VERSION ""

NS_ :

BS_:

BU_: Turbocharger OnBoardDataLogger OffBoardDiagnosticTool2 OffBoardDiagnosticTool1 FileServer ParkingBrakeController SeatControl2 FanDriveController SteeringColumnUnit CommunicationUnitRadio CommunicationUnitSatellite CommunicationUnitCellular PropulsionBatteryCharger ChassisController2 ChassisController1 EngineValveControl AuxiliaryHeater2 AuxiliaryHeater1 ClutchUnit RampControl InformationSystem1 SuspensionSystemController2 OilSensor VehicleDynamicStability ExhaustEmissionController TransmissionDisplay2 TransmissionDisplay1 ClimateControl2 WaterPumpController RearAxleSteeringController LightingOperatorControl SeatController1 IgnitionController2 IgnitionController1 TirePressureController CabController2 CabController1 PneumaticSystemController SuspensionSystemController1 HydraulicPumpController EnduranceBrakingSystem RetarderExhaustEngine2 OnBoardDiagnosticUnit HeadwayController RetarderExhaustEngine1 CabDisplay1 ManagementComputer VirtualTerminal OffVehicleGateway PowerTakeOffFront HitchControl AuxiliaryValveControl BodyController TractorTrailerBridge1 StarterSystem ElectricalSystem VehicleSecurity VehicleNavigation AerodynamicControl ElectricalChargingSystem ClimateControl1 TripRecorder InstrumentCluster SuspensionDriveAxle2 SuspensionDriveAxle1 SuspensionSteerAxle SteeringController FuelSystem CruiseControl RetarderDriveline RetarderEngine BrakesDriveAxle2 BrakesDriveAxle1 BrakesSystemController BrakesSteerAxle AxleDrive2 AxleDrive1 AxleSteering PowerTakeOff ShiftConsoleSecondary ShiftConsolePrimary Transmission2 Transmission1 Engine2 Engine1

BO_ 2365479678 ASC1: 8 Vector__XXX
 SG_ MemoryLevel : 60|4@1+ (1,0) [0|15] "" Vector__XXX
 SG_ SuspensionCtrlRefusalInformation : 56|4@1+ (1,0) [0|15] "" Vector__XXX
 SG_ SpeedDependantLevelCtrlStatus : 54|2@1+ (1,0) [0|3] "" Vector__XXX
 SG_ AllwLevelCtrlDuringBrakingStatus : 52|2@1+ (1,0) [0|3] "" Vector__XXX
 SG_ SuspensionRemoteCtrl2 : 50|2@1+ (1,0) [0|3] "" Vector__XXX
 SG_ SuspensionRemoteCtrl1 : 48|2@1+ (1,0) [0|3] "" Vector__XXX
 SG_ LiftAxle2Pos : 46|2@1+ (1,0) [0|3] "" Vector__XXX
 SG_ RearAxleInBumperRange : 42|2@1+ (1,0) [0|3] "" Vector__XXX
 SG_ FrontAxleInBumperRange : 40|2@1+ (1,0) [0|3] "" Vector__XXX
 SG_ LiftAxle1Pos : 38|2@1+ (1,0) [0|3] "" Vector__XXX
 SG_ DoorRelease : 36|2@1+ (1,0) [0|3] "" Vector__XXX
 SG_ VehicleMotionInhibit : 34|2@1+ (1,0) [0|3] "" Vector__XXX
 SG_ SecurityDevice : 32|2@1+ (1,0) [0|3] "" Vector__XXX
 SG_ LevelCtrlMode : 28|4@1+ (1,0) [0|15] "" Vector__XXX
 SG_ KneelingInformation : 24|4@1+ (1,0) [0|15] "" Vector__XXX
 SG_ LiftingCtrlModeRearAxle : 22|2@1+ (1,0) [0|3] "" Vector__XXX
 SG_ LiftingCtrlModeFrontAxle : 20|2@1+ (1,0) [0|3] "" Vector__XXX
 SG_ LoweringCtrlModeRearAxle : 18|2@1+ (1,0) [0|3] "" Vector__XXX
 SG_ LoweringCtrlModeFrontAxle : 16|2@1+ (1,0) [0|3] "" Vector__XXX
 SG_ AboveNominalLevelRearAxle : 14|2@1+ (1,0) [0|3] "" Vector__XXX
 SG_ AboveNominalLevelFrontAxle : 12|2@1+ (1,0) [0|3] "" Vector__XXX
 SG_ BelowNominalLevelRearAxle : 10|2@1+ (1,0) [0|3] "" Vector__XXX
 SG_ BelowNominalLevelFrontAxle : 8|2@1+ (1,0) [0|3] "" Vector__XXX
 SG_ NominalLevelRearAxle : 4|4@1+ (1,0) [0|15] "" Vector__XXX
 SG_ NominalLevelFrontAxle : 0|4@1+ (1,0) [0|15] "" Vector__XXX

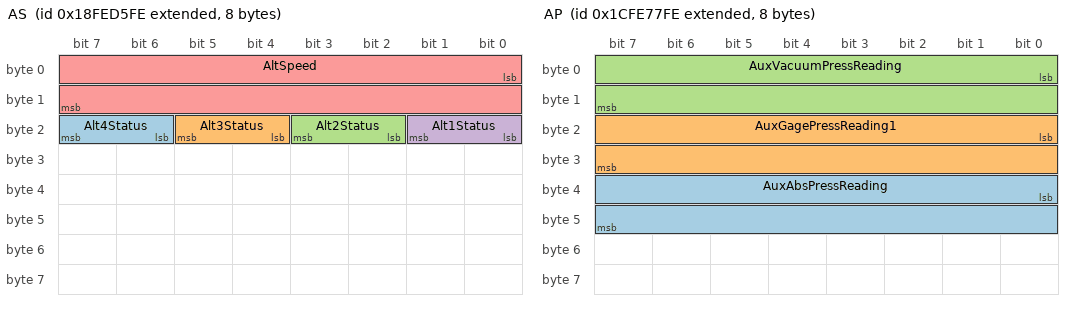
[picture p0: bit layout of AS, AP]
BO_ 2566837758 AS: 8 Vector__XXX
 SG_ Alt4Status : 22|2@1+ (1,0) [0|3] "" Vector__XXX
 SG_ Alt3Status : 20|2@1+ (1,0) [0|3] "" Vector__XXX
 SG_ Alt2Status : 18|2@1+ (1,0) [0|3] "" Vector__XXX
 SG_ Alt1Status : 16|2@1+ (1,0) [0|3] "" Vector__XXX
 SG_ AltSpeed : 0|16@1+ (0.5,0) [0|32127.5] "rpm" Vector__XXX

BO_ 2633922558 AP: 8 Vector__XXX
 SG_ AuxAbsPressReading : 32|16@1+ (0.5,0) [0|32127.5] "kPa" Vector__XXX
 SG_ AuxGagePressReading1 : 16|16@1+ (0.5,0) [0|32127.5] "kPa" Vector__XXX
 SG_ AuxVacuumPressReading : 0|16@1+ (0.5,0) [0|32127.5] "kPa" Vector__XXX

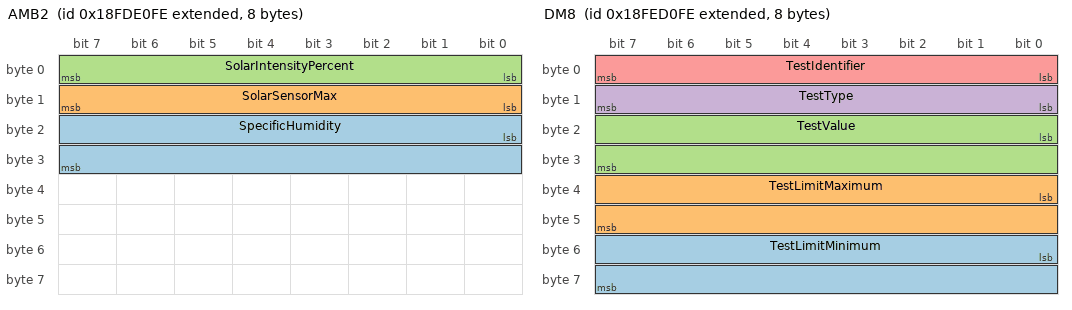
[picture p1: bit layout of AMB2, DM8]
BO_ 2566775038 AMB2: 8 Vector__XXX
 SG_ SpecificHumidity : 16|16@1+ (0.01,0) [0|642.55] "g/kg" Vector__XXX
 SG_ SolarSensorMax : 8|8@1+ (1,0) [0|100] "mW/cm^2" Vector__XXX
 SG_ SolarIntensityPercent : 0|8@1+ (0.4,0) [0|100] "%" Vector__XXX

BO_ 2566836478 DM8: 8 Vector__XXX
 SG_ TestLimitMinimum : 48|16@1+ (1,0) [0|64255] "" Vector__XXX
 SG_ TestLimitMaximum : 32|16@1+ (1,0) [0|64255] "" Vector__XXX
 SG_ TestValue : 16|16@1+ (1,0) [0|64255] "" Vector__XXX
 SG_ TestType : 8|8@1+ (1,0) [1|64] "" Vector__XXX
 SG_ TestIdentifier : 0|8@1+ (1,0) [1|64] "" Vector__XXX

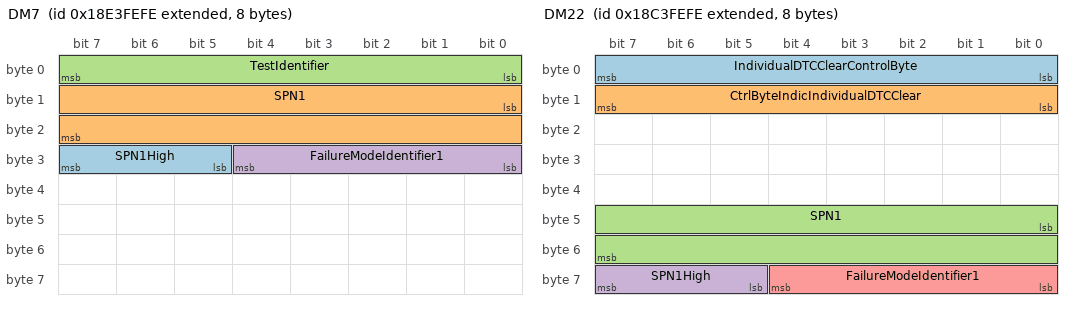
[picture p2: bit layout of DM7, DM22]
BO_ 2565078782 DM7: 8 Vector__XXX
 SG_ SPN1High : 29|3@1+ (1,0) [0|7] "" Vector__XXX
 SG_ SPN1 : 8|16@1+ (1,0) [0|65536] "" Vector__XXX
 SG_ TestIdentifier : 0|8@1+ (1,0) [1|64] "" Vector__XXX
 SG_ FailureModeIdentifier1 : 24|5@1+ (1,0) [0|0] "" Vector__XXX

BO_ 2566836222 DM6: 22 Vector__XXX
 SG_ FlashRedStopLamp : 12|2@1+ (1,0) [0|3] "" Vector__XXX
 SG_ FlashProtectLamp : 8|2@1+ (1,0) [0|3] "" Vector__XXX
 SG_ FlashMalfuncIndicatorLamp : 14|2@1+ (1,0) [0|3] "" Vector__XXX
 SG_ FlashAmberWarningLamp : 10|2@1+ (1,0) [0|3] "" Vector__XXX
 SG_ MalfunctionIndicatorLampStatus : 6|2@1+ (1,0) [0|3] "" Vector__XXX
 SG_ RedStopLampState : 4|2@1+ (1,0) [0|3] "" Vector__XXX
 SG_ AmberWarningLampStatus : 2|2@1+ (1,0) [0|3] "" Vector__XXX
 SG_ ProtectLampStatus : 0|2@1+ (1,0) [0|3] "" Vector__XXX
 SG_ DTC5 : 144|32@1+ (1,0) [0|4294967295] "" Vector__XXX
 SG_ DTC4 : 112|32@1+ (1,0) [0|4294967295] "" Vector__XXX
 SG_ DTC3 : 80|32@1+ (1,0) [0|4294967295] "" Vector__XXX
 SG_ DTC2 : 48|32@1+ (1,0) [0|4294967295] "" Vector__XXX
 SG_ DTC1 : 16|32@1+ (1,0) [0|4294967295] "" Vector__XXX

BO_ 2566835966 DM5: 8 Vector__XXX
 SG_ BoostPressureControlSystemStatus : 57|1@1- (1,0) [0|0] "" Vector__XXX
 SG_ DieselParticulateFilterStatus : 58|1@1- (1,0) [0|0] "" Vector__XXX
 SG_ NOxConvertingCatalystAdsorberSta : 59|1@1- (1,0) [0|0] "" Vector__XXX
 SG_ NMHCConvertingCatalystStatus : 60|1@1- (1,0) [0|0] "" Vector__XXX
 SG_ BoostPressureControlSystemSuppor : 41|1@1- (1,0) [0|0] "" Vector__XXX
 SG_ DieselParticulateFilterSupport : 42|1@1- (1,0) [0|0] "" Vector__XXX
 SG_ NOxConvertingCatalystAdsorberSup : 43|1@1- (1,0) [0|0] "" Vector__XXX
 SG_ NMHCConvertingCatalystSupport : 44|1@1- (1,0) [0|0] "" Vector__XXX
 SG_ MisfireMonitoringSupport : 24|1@1+ (1,0) [0|0] "" Vector__XXX
 SG_ OBDCompliance : 16|8@1+ (1,0) [0|240] "" Vector__XXX
 SG_ PreviouslyActiveTroubleCodes : 8|8@1+ (1,0) [0|240] "" Vector__XXX
 SG_ ActiveTroubleCodes : 0|8@1+ (1,0) [0|240] "" Vector__XXX
 SG_ SecondAirSystemMonStatus : 51|1@1+ (1,0) [0|1] "" Vector__XXX
 SG_ EvaporativeSystemMonStatus : 50|1@1+ (1,0) [0|1] "" Vector__XXX
 SG_ ACSystemRefrigerantMonStatus : 52|1@1+ (1,0) [0|1] "" Vector__XXX
 SG_ OxygenSensorHeaterMonStatus : 54|1@1+ (1,0) [0|1] "" Vector__XXX
 SG_ OxygenSensorMonStatus : 53|1@1+ (1,0) [0|1] "" Vector__XXX
 SG_ EGRSystemMonitoringStatus : 55|1@1+ (1,0) [0|1] "" Vector__XXX
 SG_ CatalystMonStatus : 48|1@1+ (1,0) [0|1] "" Vector__XXX
 SG_ ColdStartAidSystemMonStatus : 56|1@1+ (1,0) [0|1] "" Vector__XXX
 SG_ HeatedCatalystMonStatus : 49|1@1+ (1,0) [0|0] "" Vector__XXX
 SG_ CatalystMonSupp : 32|1@1+ (1,0) [0|1] "" Vector__XXX
 SG_ ColdStartAidSystemMonSupp : 40|1@1+ (1,0) [0|1] "" Vector__XXX
 SG_ HeatedCatalystMonSupp : 33|1@1+ (1,0) [0|0] "" Vector__XXX
 SG_ EvaporativeSystemMonSupp : 34|1@1+ (1,0) [0|1] "" Vector__XXX
 SG_ SecondAirSystemMonSupp : 35|1@1+ (1,0) [0|1] "" Vector__XXX
 SG_ ACSystemRefrigerantMonSupp : 36|1@1+ (1,0) [0|1] "" Vector__XXX
 SG_ OxygenSensorMonSupp : 37|1@1+ (1,0) [0|1] "" Vector__XXX
 SG_ OxygenSensorHeaterMonSupp : 38|1@1+ (1,0) [0|1] "" Vector__XXX
 SG_ EGRSystemMonitoringSupp : 39|1@1+ (1,0) [0|1] "" Vector__XXX
 SG_ MisfireMonitoringStatus : 28|1@1+ (1,0) [0|0] "" Vector__XXX
 SG_ ComprehensiveCompMonStatus : 30|1@1+ (1,0) [0|1] "" Vector__XXX
 SG_ FuelSystemMonitoringStatus : 29|1@1+ (1,0) [0|1] "" Vector__XXX
 SG_ ComprehensiveComponentMonSupp : 26|1@1+ (1,0) [0|0] "" Vector__XXX
 SG_ FuelSystemMonitoringSupport : 25|1@1+ (1,0) [0|1] "" Vector__XXX

BO_ 2566835710 DM4: 13 Vector__XXX
 SG_ EngIntakeManifold1Press : 48|8@1+ (2,0) [0|500] "kPa" Vector__XXX
 SG_ FreezeFrameLength : 0|8@1+ (1,0) [0|255] "Byte" Vector__XXX
 SG_ EngSpeed : 56|16@1+ (0.125,0) [0|8031.875] "rpm" Vector__XXX
 SG_ EngTorqueMode : 40|4@1+ (1,0) [0|15] "" Vector__XXX
 SG_ WheelBasedVehicleSpeed : 88|16@1+ (0.0039062485409696,0) [0|250.996] "km/h" Vector__XXX
 SG_ EngPercentLoadAtCurrentSpeed : 72|8@1+ (1,0) [0|250] "%" Vector__XXX
 SG_ EngCoolantTemp : 80|8@1+ (1,-40) [-40|210] "deg C" Vector__XXX
 SG_ DTC1 : 8|32@1+ (1,0) [0|4294967295] "" Vector__XXX

BO_ 2566835454 DM3: 0 Vector__XXX

BO_ 2566764542 DM25: 13 Vector__XXX
 SG_ ExpandedFreezeFrameLength : 0|8@1+ (1,0) [0|255] "Byte" Vector__XXX
 SG_ DTC1 : 8|32@1+ (1,0) [0|4294967295] "" Vector__XXX

BO_ 2566764286 DM24: 12 Vector__XXX
 SG_ SPNSupported1High : 21|3@1+ (1,0) [0|7] "" Vector__XXX
 SG_ SPNSupportTypeSTR3 : 82|1@1+ (1,0) [0|1] "" Vector__XXX
 SG_ SPNSupportTypeSTR2 : 81|1@1+ (1,0) [0|1] "" Vector__XXX
 SG_ SPNSupportTypeEFF3 : 80|1@1+ (1,0) [0|1] "" Vector__XXX
 SG_ SPNSupportTypeEFF2 : 48|1@1+ (1,0) [0|1] "" Vector__XXX
 SG_ SPNSupportTypeDS3 : 50|1@1+ (1,0) [0|1] "" Vector__XXX
 SG_ SPNSupportTypeDS2 : 49|1@1+ (1,0) [0|1] "" Vector__XXX
 SG_ SPNSupported3High : 85|3@1+ (1,0) [0|7] "" Vector__XXX
 SG_ SPNSupported2High : 53|3@1+ (1,0) [0|7] "" Vector__XXX
 SG_ SPNSupported3 : 64|16@1+ (1,0) [0|65535] "" Vector__XXX
 SG_ SPNSupported2 : 32|16@1+ (1,0) [0|65535] "" Vector__XXX
 SG_ SPNDataLength3 : 88|8@1+ (1,0) [0|240] "" Vector__XXX
 SG_ SPNSupportTypeSTR1 : 18|1@1+ (1,0) [0|1] "" Vector__XXX
 SG_ SPNSupportTypeDS1 : 17|1@1+ (1,0) [0|1] "" Vector__XXX
 SG_ SPNSupportTypeEFF1 : 16|1@1+ (1,0) [0|1] "" Vector__XXX
 SG_ SPNDataLength2 : 56|8@1+ (1,0) [0|240] "" Vector__XXX
 SG_ SPNDataLength1 : 24|8@1+ (1,0) [0|240] "" Vector__XXX
 SG_ SPNSupported1 : 0|16@1+ (1,0) [0|65535] "" Vector__XXX

BO_ 2566764030 DM23: 22 Vector__XXX
 SG_ FlashRedStopLamp : 12|2@1+ (1,0) [0|3] "" Vector__XXX
 SG_ FlashProtectLamp : 8|2@1+ (1,0) [0|3] "" Vector__XXX
 SG_ FlashMalfuncIndicatorLamp : 14|2@1+ (1,0) [0|3] "" Vector__XXX
 SG_ FlashAmberWarningLamp : 10|2@1+ (1,0) [0|3] "" Vector__XXX
 SG_ MalfunctionIndicatorLampStatus : 6|2@1+ (1,0) [0|3] "" Vector__XXX
 SG_ RedStopLampState : 4|2@1+ (1,0) [0|3] "" Vector__XXX
 SG_ AmberWarningLampStatus : 2|2@1+ (1,0) [0|3] "" Vector__XXX
 SG_ ProtectLampStatus : 0|2@1+ (1,0) [0|3] "" Vector__XXX
 SG_ DTC5 : 144|32@1+ (1,0) [0|4294967295] "" Vector__XXX
 SG_ DTC4 : 112|32@1+ (1,0) [0|4294967295] "" Vector__XXX
 SG_ DTC3 : 80|32@1+ (1,0) [0|4294967295] "" Vector__XXX
 SG_ DTC2 : 48|32@1+ (1,0) [0|4294967295] "" Vector__XXX
 SG_ DTC1 : 16|32@1+ (1,0) [0|4294967295] "" Vector__XXX

BO_ 2562981630 DM22: 8 Vector__XXX
 SG_ IndividualDTCClearControlByte : 0|8@1+ (1,0) [0|255] "" Vector__XXX
 SG_ CtrlByteIndicIndividualDTCClear : 8|8@1+ (1,0) [0|255] "" Vector__XXX
 SG_ SPN1 : 40|16@1+ (1,0) [0|65536] "" Vector__XXX
 SG_ SPN1High : 61|3@1+ (1,0) [0|7] "" Vector__XXX
 SG_ FailureModeIdentifier1 : 56|5@1+ (1,0) [0|0] "" Vector__XXX

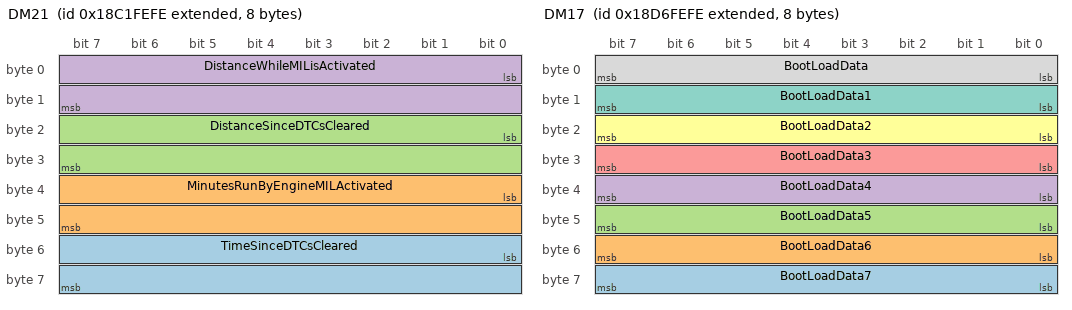
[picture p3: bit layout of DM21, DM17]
BO_ 2562850558 DM21: 8 Vector__XXX
 SG_ TimeSinceDTCsCleared : 48|16@1+ (1,0) [0|64255] "mins" Vector__XXX
 SG_ MinutesRunByEngineMILActivated : 32|16@1+ (1,0) [0|64255] "mins" Vector__XXX
 SG_ DistanceSinceDTCsCleared : 16|16@1+ (1,0) [0|64255] "km" Vector__XXX
 SG_ DistanceWhileMILisActivated : 0|16@1+ (1,0) [0|64255] "km" Vector__XXX

BO_ 2562916094 DM20: 11 Vector__XXX
 SG_ ApplSysMonitorDenominator : 72|16@1+ (1,0) [0|65535] "" Vector__XXX
 SG_ ApplSysMonitorNumerator : 56|16@1+ (1,0) [0|65535] "" Vector__XXX
 SG_ SPNofApplSysMonitor : 32|24@1+ (1,0) [0|524287] "" Vector__XXX
 SG_ OBDMonitoringCondEncountered : 16|16@1+ (1,0) [0|65535] "" Vector__XXX
 SG_ IgnitionCycleCounter : 0|16@1+ (1,0) [0|65535] "" Vector__XXX

BO_ 2564030206 DM19: 20 Vector__XXX
 SG_ CalibrationID4 : 128|32@1+ (1,0) [0|4294967295] "" Vector__XXX
 SG_ CalibrationID3 : 96|32@1+ (1,0) [0|4294967295] "" Vector__XXX
 SG_ CalibrationID2 : 64|32@1+ (1,0) [0|4294967295] "" Vector__XXX
 SG_ CalibrationID1 : 32|32@1+ (1,0) [0|4294967295] "" Vector__XXX
 SG_ CalibrationVerificationNumber : 0|32@1+ (1,0) [0|4294967295] "" Vector__XXX

BO_ 2564226814 DM17: 8 Vector__XXX
 SG_ BootLoadData7 : 56|8@1- (1,0) [0|0] "" Vector__XXX
 SG_ BootLoadData6 : 48|8@1- (1,0) [0|0] "" Vector__XXX
 SG_ BootLoadData5 : 40|8@1- (1,0) [0|0] "" Vector__XXX
 SG_ BootLoadData4 : 32|8@1- (1,0) [0|0] "" Vector__XXX
 SG_ BootLoadData3 : 24|8@1- (1,0) [0|0] "" Vector__XXX
 SG_ BootLoadData2 : 16|8@1- (1,0) [0|0] "" Vector__XXX
 SG_ BootLoadData1 : 8|8@1- (1,0) [0|0] "" Vector__XXX
 SG_ BootLoadData : 0|8@1- (1,0) [0|0] "" Vector__XXX

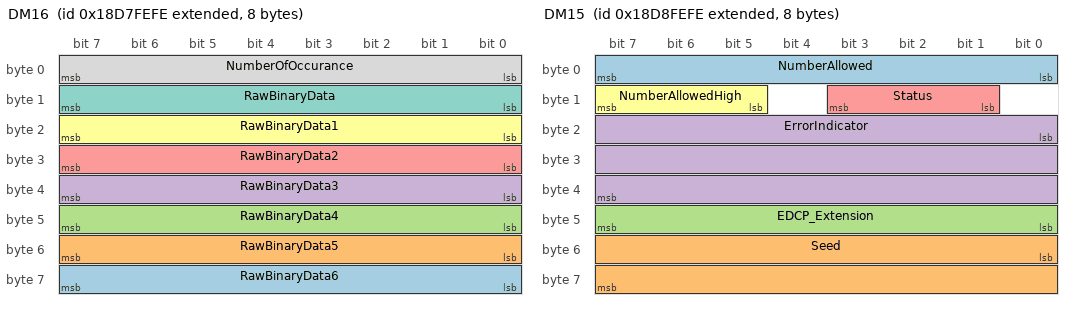
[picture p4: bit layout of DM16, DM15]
BO_ 2564292350 DM16: 8 Vector__XXX
 SG_ RawBinaryData6 : 56|8@1- (1,0) [0|0] "" Vector__XXX
 SG_ RawBinaryData5 : 48|8@1- (1,0) [0|0] "" Vector__XXX
 SG_ RawBinaryData4 : 40|8@1- (1,0) [0|0] "" Vector__XXX
 SG_ RawBinaryData3 : 32|8@1- (1,0) [0|0] "" Vector__XXX
 SG_ RawBinaryData2 : 24|8@1- (1,0) [0|0] "" Vector__XXX
 SG_ RawBinaryData1 : 16|8@1- (1,0) [0|0] "" Vector__XXX
 SG_ RawBinaryData : 8|8@1- (1,0) [0|0] "" Vector__XXX
 SG_ NumberOfOccurance : 0|8@1+ (1,0) [0|0] "" Vector__XXX

BO_ 2564357886 DM15: 8 Vector__XXX
 SG_ NumberAllowed : 0|8@1+ (1,0) [0|2047] "" Vector__XXX
 SG_ Seed : 48|16@1+ (1,0) [0|65535] "" Vector__XXX
 SG_ EDCP_Extension : 40|8@1+ (1,0) [0|255] "" Vector__XXX
 SG_ ErrorIndicator : 16|24@1+ (1,0) [0|16777215] "" Vector__XXX
 SG_ Status : 9|3@1+ (1,0) [0|7] "" Vector__XXX
 SG_ NumberAllowedHigh : 13|3@1+ (1,0) [0|7] "" Vector__XXX

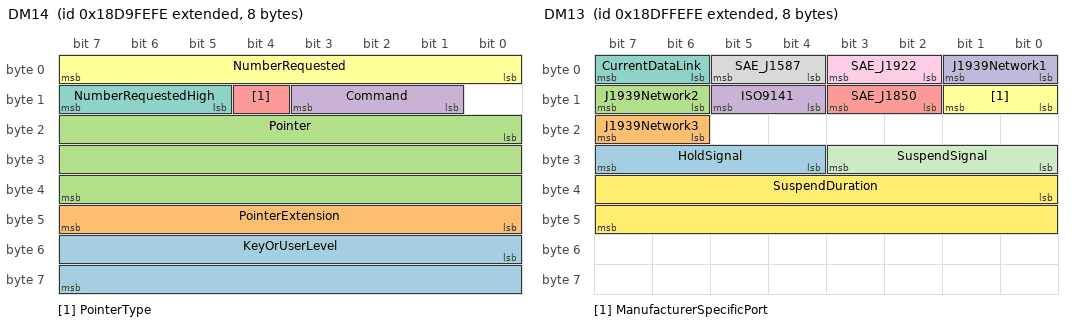
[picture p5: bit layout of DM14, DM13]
BO_ 2564423422 DM14: 8 Vector__XXX
 SG_ KeyOrUserLevel : 48|16@1+ (1,0) [0|65535] "" Vector__XXX
 SG_ PointerExtension : 40|8@1+ (1,0) [0|255] "" Vector__XXX
 SG_ Pointer : 16|24@1+ (1,0) [0|16777215] "" Vector__XXX
 SG_ Command : 9|3@1+ (1,0) [0|7] "" Vector__XXX
 SG_ PointerType : 12|1@1+ (1,0) [0|1] "" Vector__XXX
 SG_ NumberRequested : 0|8@1+ (1,0) [0|2047] "" Vector__XXX
 SG_ NumberRequestedHigh : 13|3@1+ (1,0) [0|7] "" Vector__XXX

BO_ 2564816638 DM13: 8 Vector__XXX
 SG_ HoldSignal : 28|4@1+ (1,0) [0|15] "" Vector__XXX
 SG_ J1939Network3 : 22|2@1+ (1,0) [0|3] "" Vector__XXX
 SG_ J1939Network2 : 14|2@1+ (1,0) [0|3] "" Vector__XXX
 SG_ ISO9141 : 12|2@1+ (1,0) [0|3] "" Vector__XXX
 SG_ SAE_J1850 : 10|2@1+ (1,0) [0|3] "" Vector__XXX
 SG_ ManufacturerSpecificPort : 8|2@1+ (1,0) [0|3] "" Vector__XXX
 SG_ CurrentDataLink : 6|2@1+ (1,0) [0|3] "" Vector__XXX
 SG_ SAE_J1587 : 4|2@1+ (1,0) [0|3] "" Vector__XXX
 SG_ SAE_J1922 : 2|2@1+ (1,0) [0|3] "" Vector__XXX
 SG_ J1939Network1 : 0|2@1+ (1,0) [0|3] "" Vector__XXX
 SG_ SuspendSignal : 24|4@1+ (1,0) [0|15] "" Vector__XXX
 SG_ SuspendDuration : 32|16@1+ (1,0) [0|64255] "sec" Vector__XXX

BO_ 2566837502 DM12: 22 Vector__XXX
 SG_ FlashRedStopLamp : 12|2@1+ (1,0) [0|3] "" Vector__XXX
 SG_ FlashProtectLamp : 8|2@1+ (1,0) [0|3] "" Vector__XXX
 SG_ MalfunctionIndicatorLampStatus : 6|2@1+ (1,0) [0|3] "" Vector__XXX
 SG_ RedStopLampState : 4|2@1+ (1,0) [0|3] "" Vector__XXX
 SG_ AmberWarningLampStatus : 2|2@1+ (1,0) [0|3] "" Vector__XXX
 SG_ ProtectLampStatus : 0|2@1+ (1,0) [0|3] "" Vector__XXX
 SG_ FlashMalfuncIndicatorLamp : 14|2@1+ (1,0) [0|3] "" Vector__XXX
 SG_ FlashAmberWarningLamp : 10|2@1+ (1,0) [0|3] "" Vector__XXX
 SG_ DTC5 : 144|32@1+ (1,0) [0|4294967295] "" Vector__XXX
 SG_ DTC4 : 112|32@1+ (1,0) [0|4294967295] "" Vector__XXX
 SG_ DTC3 : 80|32@1+ (1,0) [0|4294967295] "" Vector__XXX
 SG_ DTC2 : 48|32@1+ (1,0) [0|4294967295] "" Vector__XXX
 SG_ DTC1 : 16|32@1+ (1,0) [0|4294967295] "" Vector__XXX

BO_ 2566837246 DM11: 0 Vector__XXX

BO_ 2566836990 DM10: 8 Vector__XXX
 SG_ TestIdentifierSupported : 0|64@1+ (1,0) [1|1.844674407371E+019] "" Vector__XXX

BO_ 2566834942 DM1: 22 Vector__XXX
 SG_ SPN_Conversion_Method5 : 175|1@1+ (1,0) [0|0] "" Vector__XXX
 SG_ Occurance_Count5 : 168|7@1+ (1,0) [0|0] "" Vector__XXX
 SG_ Failure_Mode_Indentifier5 : 160|5@1+ (1,0) [0|0] "" Vector__XXX
 SG_ SPN5 : 151|19@0+ (1,0) [0|0] "" Vector__XXX
 SG_ SPN_Conversion_Method4 : 143|1@1+ (1,0) [0|0] "" Vector__XXX
 SG_ Occurance_Count4 : 136|7@1+ (1,0) [0|0] "" Vector__XXX
 SG_ Failure_Mode_Indentifier4 : 128|5@1+ (1,0) [0|0] "" Vector__XXX
 SG_ SPN4 : 119|19@0+ (1,0) [0|0] "" Vector__XXX
 SG_ SPN_Conversion_Method3 : 111|1@1+ (1,0) [0|0] "" Vector__XXX
 SG_ Occurance_Count3 : 104|7@1+ (1,0) [0|0] "" Vector__XXX
 SG_ Failure_Mode_Indentifier3 : 96|5@1+ (1,0) [0|0] "" Vector__XXX
 SG_ SPN3 : 87|19@0+ (1,0) [0|0] "" Vector__XXX
 SG_ Occurance_Count2 : 72|7@1+ (1,0) [0|0] "" Vector__XXX
 SG_ SPN_Conversion_Method2 : 79|1@1+ (1,0) [0|0] "" Vector__XXX
 SG_ Failure_Mode_Indentifier2 : 64|5@1+ (1,0) [0|0] "" Vector__XXX
 SG_ SPN2 : 55|19@0+ (1,0) [0|0] "" Vector__XXX
 SG_ SPN : 23|19@0+ (1,0) [0|0] "" Vector__XXX
 SG_ SPN_Conversion_Method : 47|1@1+ (1,0) [0|0] "" Vector__XXX
 SG_ Occurance_Count : 40|7@1+ (1,0) [0|0] "" Vector__XXX
 SG_ Failure_Mode_Indentifier : 32|5@1+ (1,0) [0|0] "" Vector__XXX
 SG_ FlashRedStopLamp : 12|2@1+ (1,0) [0|3] "" Vector__XXX
 SG_ FlashProtectLamp : 8|2@1+ (1,0) [0|3] "" Vector__XXX
 SG_ FlashMalfuncIndicatorLamp : 14|2@1+ (1,0) [0|3] "" Vector__XXX
 SG_ FlashAmberWarningLamp : 10|2@1+ (1,0) [0|3] "" Vector__XXX
 SG_ MalfunctionIndicatorLampStatus : 6|2@1+ (1,0) [0|3] "" Vector__XXX
 SG_ AmberWarningLampStatus : 2|2@1+ (1,0) [0|3] "" Vector__XXX
 SG_ RedStopLampState : 4|2@1+ (1,0) [0|3] "" Vector__XXX
 SG_ ProtectLampStatus : 0|2@1+ (1,0) [0|3] "" Vector__XXX

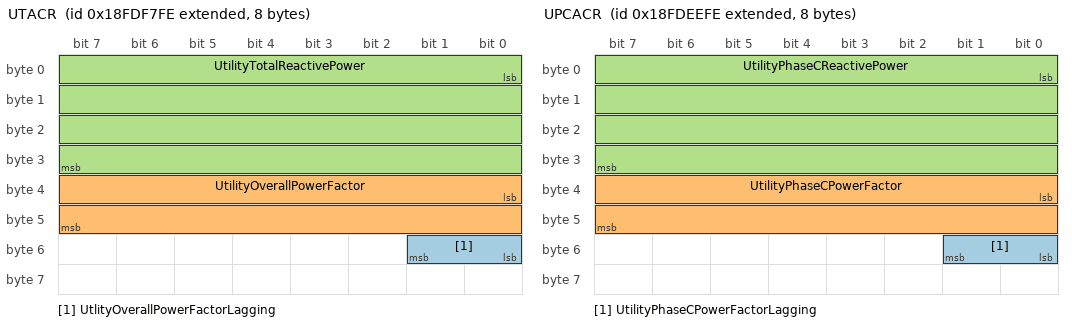
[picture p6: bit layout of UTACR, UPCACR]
BO_ 2566780926 UTACR: 8 Vector__XXX
 SG_ UtlityOverallPowerFactorLagging : 48|2@1+ (1,0) [0|3] "" Vector__XXX
 SG_ UtilityOverallPowerFactor : 32|16@1+ (1,-1) [-1|2.92181] "" Vector__XXX
 SG_ UtilityTotalReactivePower : 0|32@1+ (1,-2000000000) [-2000000000|2211081215] "VAr" Vector__XXX

BO_ 2566781182 UTACP: 8 Vector__XXX
 SG_ UtilityTotalApparentPower : 32|32@1+ (1,-2000000000) [-2000000000|2211081215] "VA" Vector__XXX
 SG_ UtilityTotalRealPower : 0|32@1+ (1,-2000000000) [-2000000000|2211081215] "W" Vector__XXX

BO_ 2566778366 UTACE: 8 Vector__XXX
 SG_ UtilityTotalKWHoursImport : 32|32@1+ (1,0) [0|4211081215] "kWh" Vector__XXX
 SG_ UtilityTotalKWHoursExport : 0|32@1+ (1,0) [0|4211081215] "kWh" Vector__XXX

BO_ 2566778622 UPCACR: 8 Vector__XXX
 SG_ UtilityPhaseCPowerFactorLagging : 48|2@1+ (1,0) [0|3] "" Vector__XXX
 SG_ UtilityPhaseCPowerFactor : 32|16@1+ (1,-1) [-1|2.92181] "" Vector__XXX
 SG_ UtilityPhaseCReactivePower : 0|32@1+ (1,-2000000000) [-2000000000|2211081215] "VAr" Vector__XXX

BO_ 2566778878 UPCACP: 8 Vector__XXX
 SG_ UtilityPhaseCApparentPower : 32|32@1+ (1,-2000000000) [-2000000000|2211081215] "VA" Vector__XXX
 SG_ UtilityPhaseCRealPower : 0|32@1+ (1,-2000000000) [-2000000000|2211081215] "W" Vector__XXX

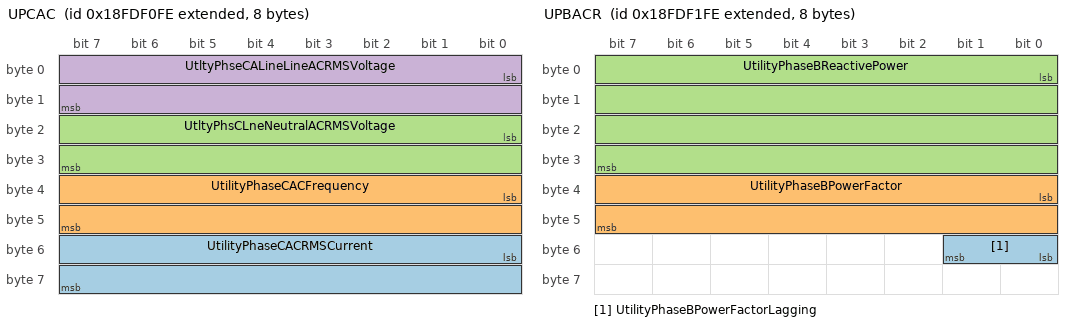
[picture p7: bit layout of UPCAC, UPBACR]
BO_ 2566779134 UPCAC: 8 Vector__XXX
 SG_ UtilityPhaseCACRMSCurrent : 48|16@1+ (1,0) [0|64255] "A" Vector__XXX
 SG_ UtilityPhaseCACFrequency : 32|16@1+ (1,0) [0|501.9921875] "Hz" Vector__XXX
 SG_ UtltyPhsCLneNeutralACRMSVoltage : 16|16@1+ (1,0) [0|64255] "V" Vector__XXX
 SG_ UtltyPhseCALineLineACRMSVoltage : 0|16@1+ (1,0) [0|64255] "V" Vector__XXX

BO_ 2566779390 UPBACR: 8 Vector__XXX
 SG_ UtilityPhaseBPowerFactorLagging : 48|2@1+ (1,0) [0|3] "" Vector__XXX
 SG_ UtilityPhaseBPowerFactor : 32|16@1+ (1,-1) [-1|2.92181] "" Vector__XXX
 SG_ UtilityPhaseBReactivePower : 0|32@1+ (1,-2000000000) [-2000000000|2211081215] "VAr" Vector__XXX

BO_ 2566779646 UPBACP: 8 Vector__XXX
 SG_ UtilityPhaseBApparentPower : 32|32@1+ (1,-2000000000) [-2000000000|2211081215] "VA" Vector__XXX
 SG_ UtilityPhaseBRealPower : 0|32@1+ (1,-2000000000) [-2000000000|2211081215] "W" Vector__XXX

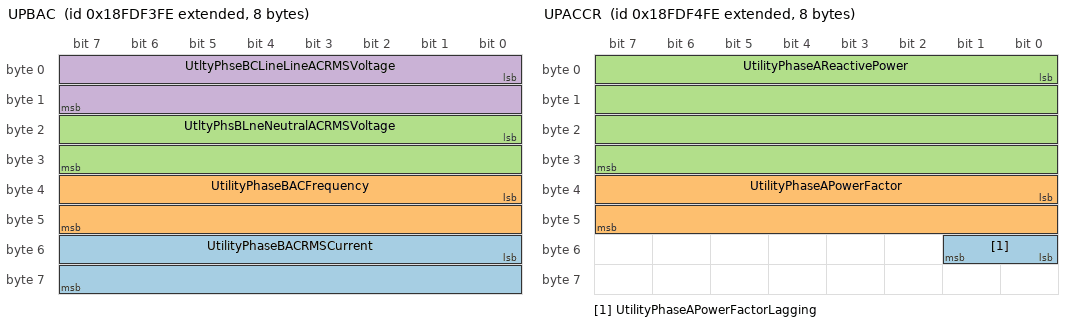
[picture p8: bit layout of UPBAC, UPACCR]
BO_ 2566779902 UPBAC: 8 Vector__XXX
 SG_ UtilityPhaseBACRMSCurrent : 48|16@1+ (1,0) [0|64255] "A" Vector__XXX
 SG_ UtilityPhaseBACFrequency : 32|16@1+ (1,0) [0|501.9921875] "Hz" Vector__XXX
 SG_ UtltyPhsBLneNeutralACRMSVoltage : 16|16@1+ (1,0) [0|64255] "V" Vector__XXX
 SG_ UtltyPhseBCLineLineACRMSVoltage : 0|16@1+ (1,0) [0|64255] "V" Vector__XXX

BO_ 2566780158 UPACCR: 8 Vector__XXX
 SG_ UtilityPhaseAPowerFactorLagging : 48|2@1+ (1,0) [0|3] "" Vector__XXX
 SG_ UtilityPhaseAPowerFactor : 32|16@1+ (1,-1) [-1|2.92181] "" Vector__XXX
 SG_ UtilityPhaseAReactivePower : 0|32@1+ (1,-2000000000) [-2000000000|2211081215] "VAr" Vector__XXX

BO_ 2566780414 UPAACP: 8 Vector__XXX
 SG_ UtilityPhaseAApparentPower : 32|32@1+ (1,-2000000000) [-2000000000|2211081215] "VA" Vector__XXX
 SG_ UtilityPhaseARealPower : 0|32@1+ (1,-2000000000) [-2000000000|2211081215] "W" Vector__XXX

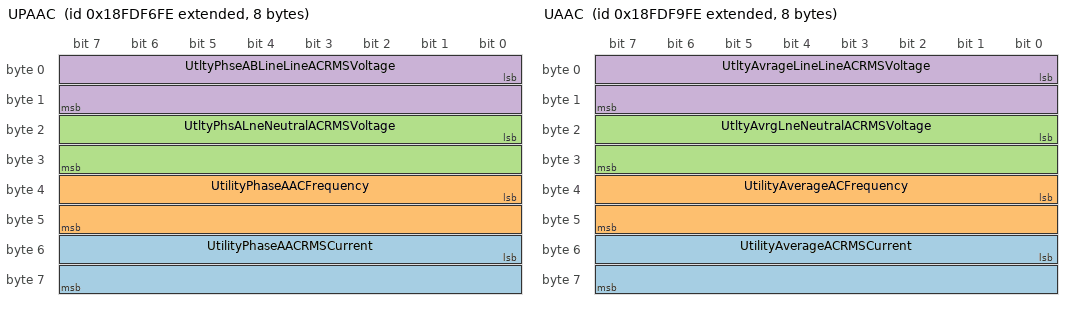
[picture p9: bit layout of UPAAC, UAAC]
BO_ 2566780670 UPAAC: 8 Vector__XXX
 SG_ UtilityPhaseAACRMSCurrent : 48|16@1+ (1,0) [0|64255] "A" Vector__XXX
 SG_ UtilityPhaseAACFrequency : 32|16@1+ (1,0) [0|501.9921875] "Hz" Vector__XXX
 SG_ UtltyPhsALneNeutralACRMSVoltage : 16|16@1+ (1,0) [0|64255] "V" Vector__XXX
 SG_ UtltyPhseABLineLineACRMSVoltage : 0|16@1+ (1,0) [0|64255] "V" Vector__XXX

BO_ 2566781438 UAAC: 8 Vector__XXX
 SG_ UtilityAverageACRMSCurrent : 48|16@1+ (1,0) [0|64255] "A" Vector__XXX
 SG_ UtilityAverageACFrequency : 32|16@1+ (1,0) [0|501.9921875] "Hz" Vector__XXX
 SG_ UtltyAvrgLneNeutralACRMSVoltage : 16|16@1+ (1,0) [0|64255] "V" Vector__XXX
 SG_ UtltyAvrageLineLineACRMSVoltage : 0|16@1+ (1,0) [0|64255] "V" Vector__XXX

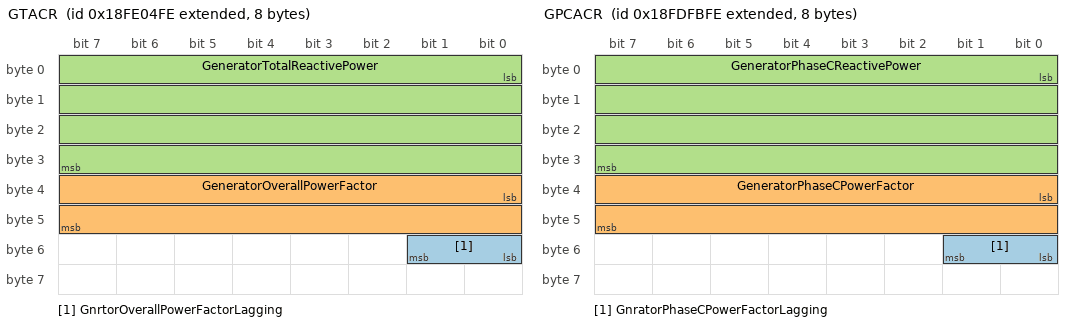
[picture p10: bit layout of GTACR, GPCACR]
BO_ 2566784254 GTACR: 8 Vector__XXX
 SG_ GnrtorOverallPowerFactorLagging : 48|2@1+ (1,0) [0|3] "" Vector__XXX
 SG_ GeneratorOverallPowerFactor : 32|16@1+ (1,-1) [-1|2.92181] "" Vector__XXX
 SG_ GeneratorTotalReactivePower : 0|32@1+ (1,-2000000000) [-2000000000|2211081215] "VAr" Vector__XXX

BO_ 2566784510 GTACP: 8 Vector__XXX
 SG_ GeneratorTotalApparentPower : 32|32@1+ (1,-2000000000) [-2000000000|2211081215] "VA" Vector__XXX
 SG_ GeneratorTotalRealPower : 0|32@1+ (1,-2000000000) [-2000000000|2211081215] "W" Vector__XXX

BO_ 2566781694 GTACE: 8 Vector__XXX
 SG_ GeneratorTotalKWHoursImport : 32|32@1+ (1,0) [0|4211081215] "kWh" Vector__XXX
 SG_ GeneratorTotalKWHoursExport : 0|32@1+ (1,0) [0|4211081215] "kWh" Vector__XXX

BO_ 2566781950 GPCACR: 8 Vector__XXX
 SG_ GnratorPhaseCPowerFactorLagging : 48|2@1+ (1,0) [0|3] "" Vector__XXX
 SG_ GeneratorPhaseCPowerFactor : 32|16@1+ (1,-1) [-1|2.92181] "" Vector__XXX
 SG_ GeneratorPhaseCReactivePower : 0|32@1+ (1,-2000000000) [-2000000000|2211081215] "VAr" Vector__XXX

BO_ 2566782206 GPCACP: 8 Vector__XXX
 SG_ GeneratorPhaseCApparentPower : 32|32@1+ (1,-2000000000) [-2000000000|2211081215] "VA" Vector__XXX
 SG_ GeneratorPhaseCRealPower : 0|32@1+ (1,-2000000000) [-2000000000|2211081215] "W" Vector__XXX

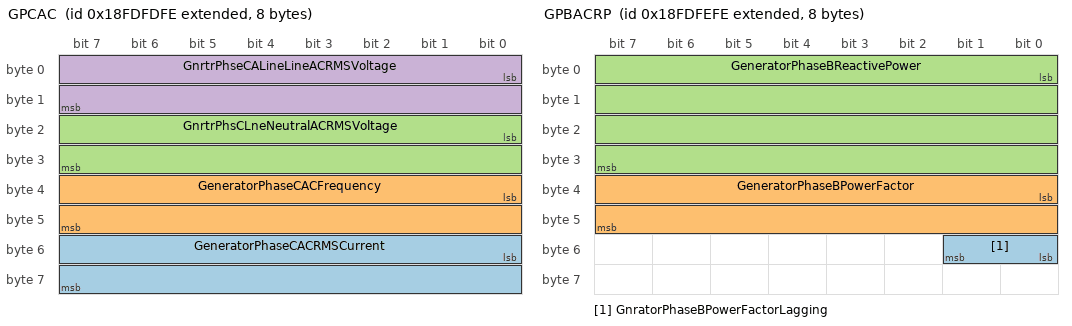
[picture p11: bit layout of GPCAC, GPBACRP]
BO_ 2566782462 GPCAC: 8 Vector__XXX
 SG_ GeneratorPhaseCACRMSCurrent : 48|16@1+ (1,0) [0|64255] "A" Vector__XXX
 SG_ GeneratorPhaseCACFrequency : 32|16@1+ (1,0) [0|501.9921875] "Hz" Vector__XXX
 SG_ GnrtrPhsCLneNeutralACRMSVoltage : 16|16@1+ (1,0) [0|64255] "V" Vector__XXX
 SG_ GnrtrPhseCALineLineACRMSVoltage : 0|16@1+ (1,0) [0|64255] "V" Vector__XXX

BO_ 2566782718 GPBACRP: 8 Vector__XXX
 SG_ GnratorPhaseBPowerFactorLagging : 48|2@1+ (1,0) [0|3] "" Vector__XXX
 SG_ GeneratorPhaseBPowerFactor : 32|16@1+ (1,-1) [-1|2.92181] "" Vector__XXX
 SG_ GeneratorPhaseBReactivePower : 0|32@1+ (1,-2000000000) [-2000000000|2211081215] "VAr" Vector__XXX

BO_ 2566782974 GPBACP: 8 Vector__XXX
 SG_ GeneratorPhaseBApparentPower : 32|32@1+ (1,-2000000000) [-2000000000|2211081215] "VA" Vector__XXX
 SG_ GeneratorPhaseBRealPower : 0|32@1+ (1,-2000000000) [-2000000000|2211081215] "W" Vector__XXX

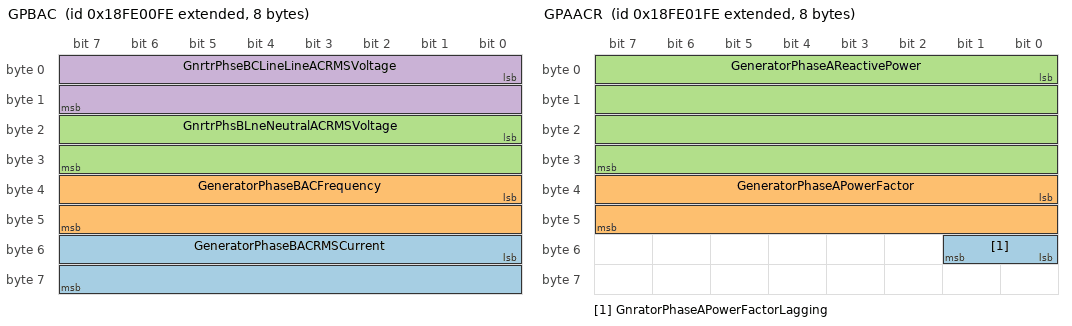
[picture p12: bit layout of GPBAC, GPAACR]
BO_ 2566783230 GPBAC: 8 Vector__XXX
 SG_ GeneratorPhaseBACRMSCurrent : 48|16@1+ (1,0) [0|64255] "A" Vector__XXX
 SG_ GeneratorPhaseBACFrequency : 32|16@1+ (1,0) [0|501.9921875] "Hz" Vector__XXX
 SG_ GnrtrPhsBLneNeutralACRMSVoltage : 16|16@1+ (1,0) [0|64255] "V" Vector__XXX
 SG_ GnrtrPhseBCLineLineACRMSVoltage : 0|16@1+ (1,0) [0|64255] "V" Vector__XXX

BO_ 2566783486 GPAACR: 8 Vector__XXX
 SG_ GnratorPhaseAPowerFactorLagging : 48|2@1+ (1,0) [0|3] "" Vector__XXX
 SG_ GeneratorPhaseAPowerFactor : 32|16@1+ (1,-1) [-1|2.92181] "" Vector__XXX
 SG_ GeneratorPhaseAReactivePower : 0|32@1+ (1,-2000000000) [-2000000000|2211081215] "VAr" Vector__XXX

BO_ 2566783742 GPAACP: 8 Vector__XXX
 SG_ GeneratorPhaseAApparentPower : 32|32@1+ (1,-2000000000) [-2000000000|2211081215] "VA" Vector__XXX
 SG_ GeneratorPhaseARealPower : 0|32@1+ (1,-2000000000) [-2000000000|2211081215] "W" Vector__XXX

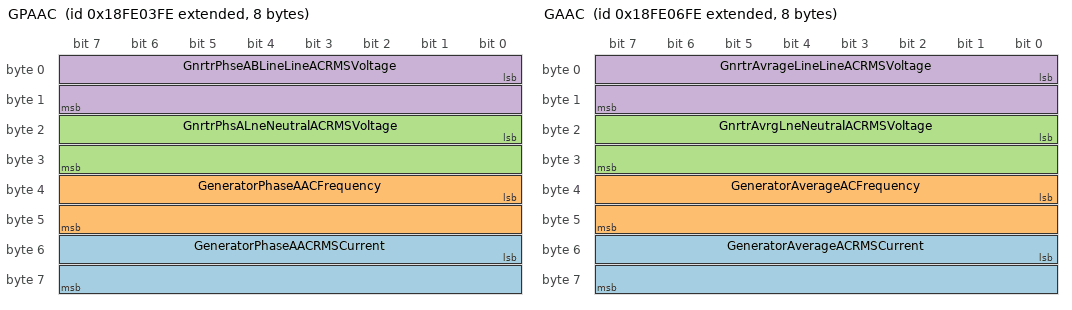
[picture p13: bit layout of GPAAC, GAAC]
BO_ 2566783998 GPAAC: 8 Vector__XXX
 SG_ GeneratorPhaseAACRMSCurrent : 48|16@1+ (1,0) [0|64255] "A" Vector__XXX
 SG_ GeneratorPhaseAACFrequency : 32|16@1+ (1,0) [0|501.9921875] "Hz" Vector__XXX
 SG_ GnrtrPhsALneNeutralACRMSVoltage : 16|16@1+ (1,0) [0|64255] "V" Vector__XXX
 SG_ GnrtrPhseABLineLineACRMSVoltage : 0|16@1+ (1,0) [0|64255] "V" Vector__XXX

BO_ 2566784766 GAAC: 8 Vector__XXX
 SG_ GeneratorAverageACRMSCurrent : 48|16@1+ (1,0) [0|64255] "A" Vector__XXX
 SG_ GeneratorAverageACFrequency : 32|16@1+ (1,0) [0|501.9921875] "Hz" Vector__XXX
 SG_ GnrtrAvrgLneNeutralACRMSVoltage : 16|16@1+ (1,0) [0|64255] "V" Vector__XXX
 SG_ GnrtrAvrageLineLineACRMSVoltage : 0|16@1+ (1,0) [0|64255] "V" Vector__XXX

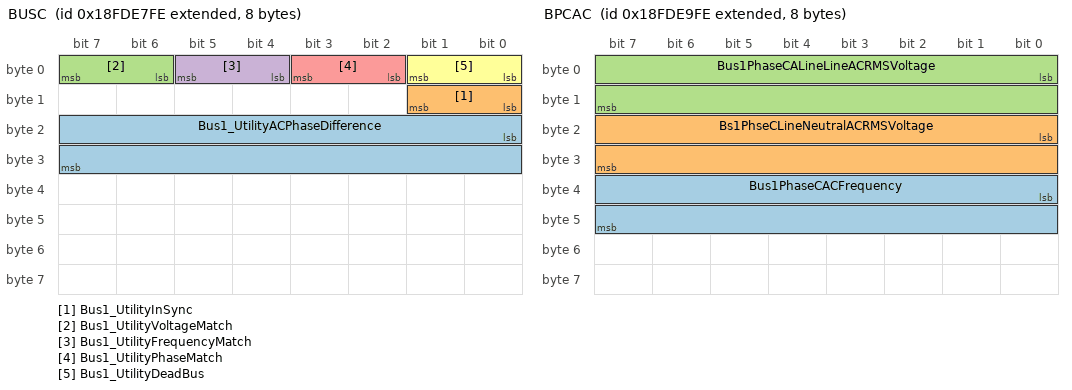
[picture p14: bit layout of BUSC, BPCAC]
BO_ 2566776830 BUSC: 8 Vector__XXX
 SG_ Bus1_UtilityACPhaseDifference : 16|16@1+ (1,-200) [-200|301.99] "deg" Vector__XXX
 SG_ Bus1_UtilityInSync : 8|2@1+ (1,0) [0|3] "" Vector__XXX
 SG_ Bus1_UtilityVoltageMatch : 6|2@1+ (1,0) [0|3] "" Vector__XXX
 SG_ Bus1_UtilityFrequencyMatch : 4|2@1+ (1,0) [0|3] "" Vector__XXX
 SG_ Bus1_UtilityPhaseMatch : 2|2@1+ (1,0) [0|3] "" Vector__XXX
 SG_ Bus1_UtilityDeadBus : 0|2@1+ (1,0) [0|3] "" Vector__XXX

BO_ 2566777342 BPCAC: 8 Vector__XXX
 SG_ Bus1PhaseCACFrequency : 32|16@1+ (1,0) [0|501.9921875] "Hz" Vector__XXX
 SG_ Bs1PhseCLineNeutralACRMSVoltage : 16|16@1+ (1,0) [0|64255] "V" Vector__XXX
 SG_ Bus1PhaseCALineLineACRMSVoltage : 0|16@1+ (1,0) [0|64255] "V" Vector__XXX

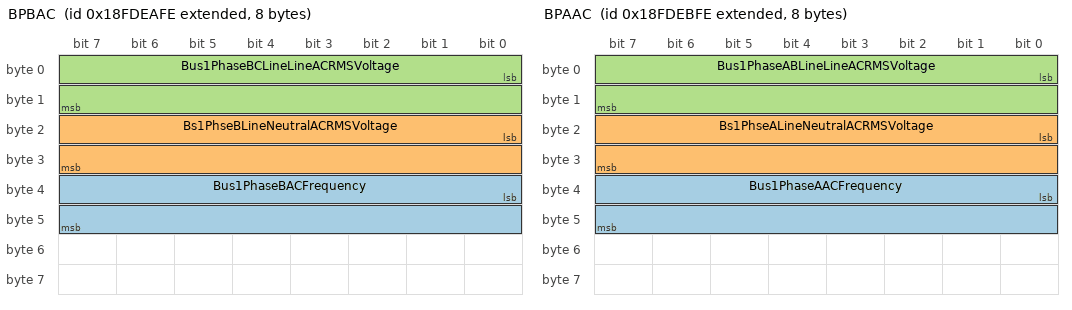
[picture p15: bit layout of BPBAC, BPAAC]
BO_ 2566777598 BPBAC: 8 Vector__XXX
 SG_ Bus1PhaseBACFrequency : 32|16@1+ (1,0) [0|501.9921875] "Hz" Vector__XXX
 SG_ Bs1PhseBLineNeutralACRMSVoltage : 16|16@1+ (1,0) [0|64255] "V" Vector__XXX
 SG_ Bus1PhaseBCLineLineACRMSVoltage : 0|16@1+ (1,0) [0|64255] "V" Vector__XXX

BO_ 2566777854 BPAAC: 8 Vector__XXX
 SG_ Bus1PhaseAACFrequency : 32|16@1+ (1,0) [0|501.9921875] "Hz" Vector__XXX
 SG_ Bs1PhseALineNeutralACRMSVoltage : 16|16@1+ (1,0) [0|64255] "V" Vector__XXX
 SG_ Bus1PhaseABLineLineACRMSVoltage : 0|16@1+ (1,0) [0|64255] "V" Vector__XXX

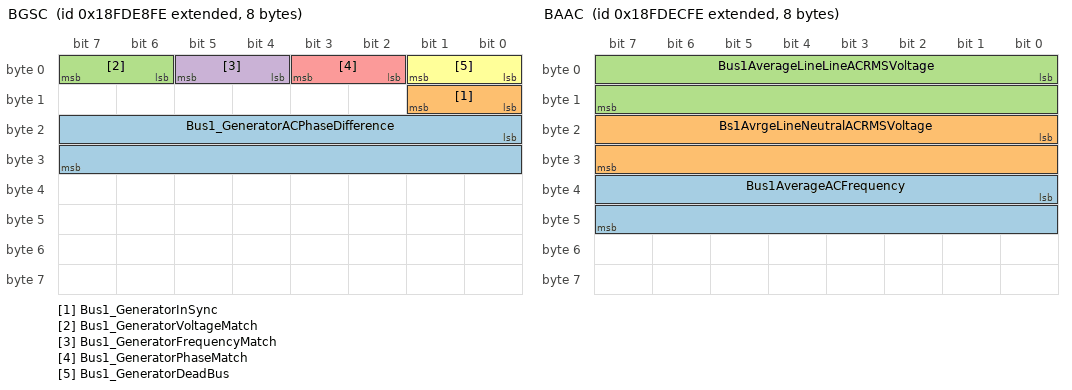
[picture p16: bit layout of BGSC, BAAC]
BO_ 2566777086 BGSC: 8 Vector__XXX
 SG_ Bus1_GeneratorACPhaseDifference : 16|16@1+ (1,-200) [-200|301.99] "deg" Vector__XXX
 SG_ Bus1_GeneratorInSync : 8|2@1+ (1,0) [0|3] "" Vector__XXX
 SG_ Bus1_GeneratorVoltageMatch : 6|2@1+ (1,0) [0|3] "" Vector__XXX
 SG_ Bus1_GeneratorFrequencyMatch : 4|2@1+ (1,0) [0|3] "" Vector__XXX
 SG_ Bus1_GeneratorPhaseMatch : 2|2@1+ (1,0) [0|3] "" Vector__XXX
 SG_ Bus1_GeneratorDeadBus : 0|2@1+ (1,0) [0|3] "" Vector__XXX

BO_ 2566778110 BAAC: 8 Vector__XXX
 SG_ Bus1AverageACFrequency : 32|16@1+ (1,0) [0|501.9921875] "Hz" Vector__XXX
 SG_ Bs1AvrgeLineNeutralACRMSVoltage : 16|16@1+ (1,0) [0|64255] "V" Vector__XXX
 SG_ Bus1AverageLineLineACRMSVoltage : 0|16@1+ (1,0) [0|64255] "V" Vector__XXX

BO_ 2633895422 WSMSTR: 8 Vector__XXX
 SG_ NumberOfMembers : 0|8@1+ (1,0) [0|0] "" Vector__XXX

BO_ 2566838526 CA: 9 Vector__XXX
 SG_ AddressAssignment : 64|8@1+ (1,0) [0|255] "" Vector__XXX
 SG_ ArbitraryAddressCapable : 63|1@1+ (1,0) [0|1] "" Vector__XXX
 SG_ IndustryGroup M : 60|3@1+ (1,0) [0|7] "" Vector__XXX
 SG_ VehicleSystemInstance : 56|4@1+ (1,0) [0|15] "" Vector__XXX
 SG_ Function : 40|8@1+ (1,0) [0|255] "" Vector__XXX
 SG_ VehicleSystem m0 : 49|7@1+ (1,0) [0|127] "" Vector__XXX
 SG_ FunctionInstance : 35|5@1+ (1,0) [0|31] "" Vector__XXX
 SG_ ECUInstance : 32|3@1+ (1,0) [0|7] "" Vector__XXX
 SG_ ManufacturerCode : 21|11@1+ (1,0) [0|2047] "" Vector__XXX
 SG_ IdentityNumber : 0|21@1+ (1,0) [0|2097152] "" Vector__XXX
 SG_ VehicleSystem5 m5 : 49|7@1+ (1,0) [0|127] "" Vector__XXX
 SG_ VehicleSystem4 m4 : 49|7@1+ (1,0) [0|127] "" Vector__XXX
 SG_ VehicleSystem3 m3 : 49|7@1+ (1,0) [0|127] "" Vector__XXX
 SG_ VehicleSystem2 m2 : 49|7@1+ (1,0) [0|127] "" Vector__XXX
 SG_ VehicleSystem1 m1 : 49|7@1+ (1,0) [0|127] "" Vector__XXX

BO_ 2565799678 ACL: 8 Vector__XXX
 SG_ ArbitraryAddressCapable : 63|1@1+ (1,0) [0|1] "" Vector__XXX
 SG_ IndustryGroup M : 60|3@1+ (1,0) [0|7] "" Vector__XXX
 SG_ VehicleSystemInstance : 56|4@1+ (1,0) [0|15] "" Vector__XXX
 SG_ Function : 40|8@1+ (1,0) [0|255] "" Vector__XXX
 SG_ FunctionInstance : 35|5@1+ (1,0) [0|31] "" Vector__XXX
 SG_ ECUInstance : 32|3@1+ (1,0) [0|7] "" Vector__XXX
 SG_ ManufacturerCode : 21|11@1+ (1,0) [0|2047] "" Vector__XXX
 SG_ IdentityNumber : 0|21@1+ (1,0) [0|2097152] "" Vector__XXX
 SG_ VehicleSystem m0 : 49|7@1+ (1,0) [0|127] "" Vector__XXX
 SG_ VehicleSystem5 m5 : 49|7@1+ (1,0) [0|127] "" Vector__XXX
 SG_ VehicleSystem4 m4 : 49|7@1+ (1,0) [0|127] "" Vector__XXX
 SG_ VehicleSystem3 m3 : 49|7@1+ (1,0) [0|127] "" Vector__XXX
 SG_ VehicleSystem2 m2 : 49|7@1+ (1,0) [0|127] "" Vector__XXX
 SG_ VehicleSystem1 m1 : 49|7@1+ (1,0) [0|127] "" Vector__XXX

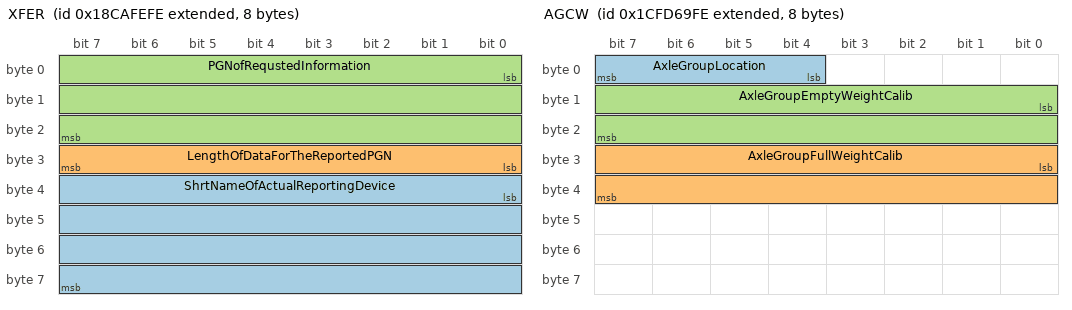
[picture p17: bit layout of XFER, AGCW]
BO_ 2563440382 XFER: 8 Vector__XXX
 SG_ ShrtNameOfActualReportingDevice : 32|32@1+ (1,0) [0|0] "(2^32 - 1)" Vector__XXX
 SG_ LengthOfDataForTheReportedPGN : 24|8@1+ (1,0) [0|255] "" Vector__XXX
 SG_ PGNofRequstedInformation : 0|24@1+ (1,0) [0|16777215] "" Vector__XXX

BO_ 2632711934 TPDT: 8 Vector__XXX
 SG_ SequenceNumber : 0|8@1+ (1,0) [0|255] "" Vector__XXX

BO_ 2632777470 TPCM: 8 Vector__XXX
 SG_ TotalNumberOfPacketsEoMA m19 : 24|8@1+ (1,0) [0|255] "" Vector__XXX
 SG_ TotalMessageSizeEoMA m19 : 8|16@1+ (1,0) [0|64255] "counts" Vector__XXX
 SG_ TotalMessageSizeBAM m32 : 8|16@1+ (1,0) [0|64255] "counts" Vector__XXX
 SG_ TotalNumberOfPacketsBAM m32 : 24|8@1+ (1,0) [0|255] "" Vector__XXX
 SG_ ConnectionAbortReason m255 : 8|8@1+ (1,0) [0|255] "" Vector__XXX
 SG_ NextPacketNumberToBeSent m17 : 16|8@1+ (1,0) [0|255] "" Vector__XXX
 SG_ NumberOfPacketsThatCanBeSent m17 : 8|8@1+ (1,0) [0|255] "" Vector__XXX
 SG_ PGNumber : 40|24@1+ (1,0) [0|16777200] "" Vector__XXX
 SG_ MaximumNumberOfPackets m16 : 32|8@1+ (1,0) [0|255] "" Vector__XXX
 SG_ TotalNumberOfPackets m16 : 24|8@1+ (1,0) [0|255] "" Vector__XXX
 SG_ TotalMessageSize m16 : 8|16@1+ (1,0) [0|64255] "counts" Vector__XXX
 SG_ ControlByte M : 0|8@1+ (1,0) [0|255] "" Vector__XXX

BO_ 2563374846 RQST2: 8 Vector__XXX
 SG_ UseTransferMode : 24|2@1+ (1,0) [0|3] "" Vector__XXX
 SG_ ParameterGroupNumber : 0|24@1+ (1,0) [0|16777215] "" Vector__XXX

BO_ 2565537534 RQST: 3 Vector__XXX
 SG_ ParameterGroupNumber : 0|24@1+ (1,0) [0|16777215] "" Vector__XXX

BO_ 2499635966 AGW: 8 Vector__XXX
 SG_ AxleGroupWeight : 8|16@1+ (2,0) [0|128510] "kg" Vector__XXX
 SG_ AxleGroupLocation : 0|4@1+ (1,0) [0|15] "" Vector__XXX

BO_ 2633853438 AGCW: 8 Vector__XXX
 SG_ AxleGroupLocation : 4|4@1+ (1,0) [0|15] "" Vector__XXX
 SG_ AxleGroupFullWeightCalib : 24|16@1+ (2,0) [0|128510] "kg" Vector__XXX
 SG_ AxleGroupEmptyWeightCalib : 8|16@1+ (2,0) [0|128510] "kg" Vector__XXX

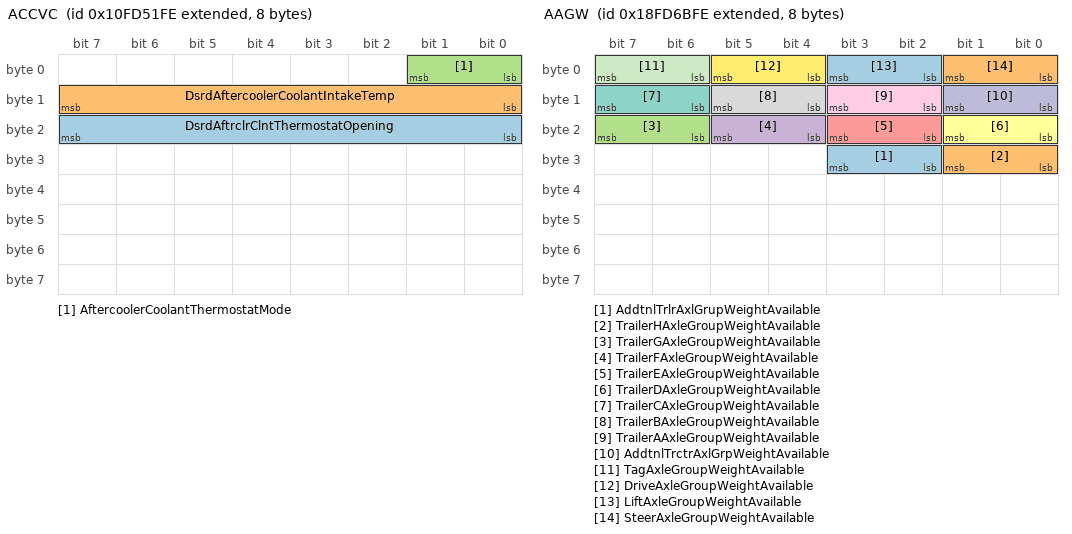
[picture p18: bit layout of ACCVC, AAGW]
BO_ 2432520702 ACCVC: 8 Vector__XXX
 SG_ DsrdAftrclrClntThermostatOpening : 16|8@1+ (1,0) [0|100] "%" Vector__XXX
 SG_ DsrdAftercoolerCoolantIntakeTemp : 8|8@1+ (1,-40) [-40|210] "deg C" Vector__XXX
 SG_ AftercoolerCoolantThermostatMode : 0|2@1+ (1,0) [0|3] "" Vector__XXX

BO_ 2566745086 AAGW: 8 Vector__XXX
 SG_ AddtnlTrlrAxlGrupWeightAvailable : 26|2@1+ (1,0) [0|3] "" Vector__XXX
 SG_ TrailerHAxleGroupWeightAvailable : 24|2@1+ (1,0) [0|3] "" Vector__XXX
 SG_ TrailerGAxleGroupWeightAvailable : 22|2@1+ (1,0) [0|3] "" Vector__XXX
 SG_ TrailerFAxleGroupWeightAvailable : 20|2@1+ (1,0) [0|3] "" Vector__XXX
 SG_ TrailerEAxleGroupWeightAvailable : 18|2@1+ (1,0) [0|3] "" Vector__XXX
 SG_ TrailerDAxleGroupWeightAvailable : 16|2@1+ (1,0) [0|3] "" Vector__XXX
 SG_ TrailerCAxleGroupWeightAvailable : 14|2@1+ (1,0) [0|3] "" Vector__XXX
 SG_ TrailerBAxleGroupWeightAvailable : 12|2@1+ (1,0) [0|3] "" Vector__XXX
 SG_ TrailerAAxleGroupWeightAvailable : 10|2@1+ (1,0) [0|3] "" Vector__XXX
 SG_ AddtnlTrctrAxlGrpWeightAvailable : 8|2@1+ (1,0) [0|3] "" Vector__XXX
 SG_ TagAxleGroupWeightAvailable : 6|2@1+ (1,0) [0|3] "" Vector__XXX
 SG_ DriveAxleGroupWeightAvailable : 4|2@1+ (1,0) [0|3] "" Vector__XXX
 SG_ LiftAxleGroupWeightAvailable : 2|2@1+ (1,0) [0|3] "" Vector__XXX
 SG_ SteerAxleGroupWeightAvailable : 0|2@1+ (1,0) [0|3] "" Vector__XXX

BO_ 2566739198 DM52: 22 Vector__XXX
 SG_ FlashRedStopLamp : 12|2@1+ (1,0) [0|3] "" Vector__XXX
 SG_ FlashProtectLamp : 8|2@1+ (1,0) [0|3] "" Vector__XXX
 SG_ FlashMalfuncIndicatorLamp : 14|2@1+ (1,0) [0|3] "" Vector__XXX
 SG_ FlashAmberWarningLamp : 10|2@1+ (1,0) [0|3] "" Vector__XXX
 SG_ MalfunctionIndicatorLampStatus : 6|2@1+ (1,0) [0|3] "" Vector__XXX
 SG_ AmberWarningLampStatus : 2|2@1+ (1,0) [0|3] "" Vector__XXX
 SG_ RedStopLampState : 4|2@1+ (1,0) [0|3] "" Vector__XXX
 SG_ ProtectLampStatus : 0|2@1+ (1,0) [0|3] "" Vector__XXX
 SG_ DTC5 : 144|32@1+ (1,0) [0|4294967295] "" Vector__XXX
 SG_ DTC4 : 112|32@1+ (1,0) [0|4294967295] "" Vector__XXX
 SG_ DTC3 : 80|32@1+ (1,0) [0|4294967295] "" Vector__XXX
 SG_ DTC2 : 48|32@1+ (1,0) [0|4294967295] "" Vector__XXX
 SG_ DTC1 : 16|32@1+ (1,0) [0|4294967295] "" Vector__XXX

CM_ BO_ 2365479678 "Used for suspension control information";
CM_ SG_ 2365479678 MemoryLevel "Signal which indicates that the air suspension control has memory levels selected or stored.";
CM_ SG_ 2365479678 SuspensionCtrlRefusalInformation "Signal which indicates that the air suspension control cannot perform a request due to the operating conditions. It also";
CM_ SG_ 2365479678 SpeedDependantLevelCtrlStatus "This parameter indicates if the function Speed Dependant Level Control is active. The function is activated by SPN 5295.";
CM_ SG_ 2365479678 AllwLevelCtrlDuringBrakingStatus "This parameter indicates if the function Allow Level Control During Braking is active. Functions is activated by SPN 5293.";
CM_ SG_ 2365479678 SuspensionRemoteCtrl2 "Signal which indicates that the suspension system is controlled by remote control #2. Remote control is an external unit to";
CM_ SG_ 2365479678 SuspensionRemoteCtrl1 "Signal which indicates that the suspension system is controlled by remote control #1. Remote control is an external unit to";
CM_ SG_ 2365479678 LiftAxle2Pos "Signal which indicates the position / load condition of lift axle / tag axle #2. Numbering of lift/tag axles starts at front axle.";
CM_ SG_ 2365479678 RearAxleInBumperRange "Signal which indicates that the vehicle height at the rear axle (SPNs 1723 and 1724) is within the bumper range.";
CM_ SG_ 2365479678 FrontAxleInBumperRange "Signal which indicates that the vehicle height at the front axle (SPNs 1721 and 1722) is within the bumper range.";
CM_ SG_ 2365479678 LiftAxle1Pos "Signal which indicates the position / load condition of lift axle / tag axle #1. Numbering of lift/tag axles starts at front axle.";
CM_ SG_ 2365479678 DoorRelease "Signal which indicates that the doors may be opened. [Please note: doors instead of door!]";
CM_ SG_ 2365479678 VehicleMotionInhibit "Signal which indicates whether vehicle motion is inhibited.";
CM_ SG_ 2365479678 SecurityDevice "The signal which indicates the status of the security device. An example of a security device is a curbstone feeler";
CM_ SG_ 2365479678 LevelCtrlMode "Signal which indicates the actual control mode of the air suspension system";
CM_ SG_ 2365479678 KneelingInformation "Signal which indicates the actual level change in case of kneeling function";
CM_ SG_ 2365479678 LiftingCtrlModeRearAxle "Signal which indicates the actual lifting level change at the rear axle";
CM_ SG_ 2365479678 LiftingCtrlModeFrontAxle "Signal which indicates the actual lifting level change at the front axle";
CM_ SG_ 2365479678 LoweringCtrlModeRearAxle "Signal which indicates the actual lowering level change at the rear axle";
CM_ SG_ 2365479678 LoweringCtrlModeFrontAxle "Signal which indicates the actual lowering level change at the front axle";
CM_ SG_ 2365479678 AboveNominalLevelRearAxle "Signal which indicates whether the actual height of the rear axle is above the nominal (desired) level of the rear axle. For";
CM_ SG_ 2365479678 AboveNominalLevelFrontAxle "Signal which indicates whether the actual height of the front axle is above the nominal (desired) level of the front axle. For";
CM_ SG_ 2365479678 BelowNominalLevelRearAxle "Signal which indicates whether the actual height of the rear axle is below the nominal (desired) level for the rear axle. For";
CM_ SG_ 2365479678 BelowNominalLevelFrontAxle "Signal which indicates whether the actual height of the front axle is below the nominal (desired) level for the front axle. For";
CM_ SG_ 2365479678 NominalLevelRearAxle "Signal which indicates the nominal (desired) height of the rear axle to be controlled by the suspension system.";
CM_ SG_ 2365479678 NominalLevelFrontAxle "Signal which indicates the nominal (desired) height of the front axle to be controlled by the suspension system.";
CM_ SG_ 2566837758 Alt4Status "Alternator 4 operating status.";
CM_ SG_ 2566837758 Alt3Status "Alternator 3 operating status.";
CM_ SG_ 2566837758 Alt2Status "Alternator 2 operating status.";
CM_ SG_ 2566837758 Alt1Status "Alternator 1 operating status.";
CM_ SG_ 2566837758 AltSpeed "Actual rotation speed of the alternator.";
CM_ SG_ 2633922558 AuxAbsPressReading "Identifies the current absolute pressure (relative to 0 pressure) that is configured uniquely per application. Not to be used";
CM_ SG_ 2633922558 AuxGagePressReading1 "Identifies the current gage pressure (relative to atmosphere) that is configured uniquely per application. Not to be used in";
CM_ SG_ 2633922558 AuxVacuumPressReading "Identifies the current vacuum pressure (relative to atmosphere) that is configured uniquely per application. Not to be used";
CM_ BO_ 2566775038 "This message contains measurement and configuration information about the vehicle ambient conditions.";
CM_ SG_ 2566775038 SpecificHumidity "Specific humidity of the ambient intake air.";
CM_ SG_ 2566775038 SolarSensorMax "This is the maximum value which can be reported by the sensor for the solar intensity. (This is a configuration parameter)";
CM_ SG_ 2566775038 SolarIntensityPercent "This is the solar radiation (power density) falling on the vehicle in percent of the maximum sensor value (SPN 2611).";
CM_ BO_ 2566836478 "Test results for non-continously monitored systems.";
CM_ SG_ 2566836478 TestLimitMinimum "The threshold which the test value must be above to pass the test.";
CM_ SG_ 2566836478 TestLimitMaximum "The threshold which the test value must be below to pass the test.";
CM_ SG_ 2566836478 TestValue "The test value collected during the test.";
CM_ SG_ 2566836478 TestType "Identifies the non-continously monitored component identifier that was tested.";
CM_ SG_ 2566836478 TestIdentifier "Designates the test to be run.";
CM_ BO_ 2565078782 "Command non-continously monitored test";
CM_ SG_ 2565078782 SPN1High "SPN #1 (Conversion Version 4)";
CM_ SG_ 2565078782 SPN1 "SPN #1 (Conversion Version 4)";
CM_ SG_ 2565078782 TestIdentifier "Designates the test to be run.";
CM_ SG_ 2565078782 FailureModeIdentifier1 "The FMI defines the type of failure detected in the subsystem identified by an SPN.";
CM_ BO_ 2566836222 "Pending DTCs";
CM_ SG_ 2566836222 FlashRedStopLamp "This parameter provides the capability to flash the RSL (SPN 3039).";
CM_ SG_ 2566836222 FlashProtectLamp "This parameter provides the capability to flash the engine protect lamp (SPN 3041).";
CM_ SG_ 2566836222 FlashMalfuncIndicatorLamp "This parameter provides the capability to flash the MIL (SPN 3038).";
CM_ SG_ 2566836222 FlashAmberWarningLamp "This parameter provides the capability to flash the AWL (SPN 3040). ";
CM_ SG_ 2566836222 MalfunctionIndicatorLampStatus "A lamp used to relay only emissions-related trouble code information.";
CM_ SG_ 2566836222 RedStopLampState "This lamp is uesed to relay trouble code information that is of a severe enought condition that it warrants stopping the vehicle.";
CM_ SG_ 2566836222 AmberWarningLampStatus "This lamp is used to relay trouble code information that is reporting a problem with the vehicle system but the vehicle need
not be immediately stopped.";
CM_ SG_ 2566836222 ProtectLampStatus "This lamp is used to relay trouble code informatio that is reporting a problem with a vehicle system that is most
probably not electronic subsystem related.";
CM_ SG_ 2566836222 DTC5 "Diagnostic Trouble Code";
CM_ SG_ 2566836222 DTC4 "Diagnostic Trouble Code";
CM_ SG_ 2566836222 DTC3 "Diagnostic Trouble Code";
CM_ SG_ 2566836222 DTC2 "Diagnostic Trouble Code";
CM_ SG_ 2566836222 DTC1 "Diagnostic Trouble Code";
CM_ BO_ 2566835966 "Diagnostic readiness 1";
CM_ SG_ 2566835966 OBDCompliance "Identifies the OBD compliance capabilityof the responding controller.";
CM_ SG_ 2566835966 PreviouslyActiveTroubleCodes "Identifies the number of previously active trouble codes that are present in a specific controller.";
CM_ SG_ 2566835966 ActiveTroubleCodes "Identifies the number of active trouble codes that are present in a specific controller.";
CM_ BO_ 2566835710 "Freeze frame parameters";
CM_ SG_ 2566835710 EngIntakeManifold1Press "The gage pressure measurement of the air intake manifold. If there are multiple air pressure sensors in the intake stream,";
CM_ SG_ 2566835710 FreezeFrameLength "The freeze frame length shall be equal to the number of bytes in the required parameters plus the number of bytes in the
manufacturer specific parameters.";
CM_ SG_ 2566835710 EngSpeed "Actual engine speed which is calculated over a minimum crankshaft angle of 720 degrees divided by the number of";
CM_ SG_ 2566835710 EngTorqueMode "State signal which indicates which engine torque mode is currently generating, limiting, or controlling the torque. Note";
CM_ SG_ 2566835710 WheelBasedVehicleSpeed "Speed of the vehicle as calculated from wheel or tailshaft speed.";
CM_ SG_ 2566835710 EngPercentLoadAtCurrentSpeed "The ratio of actual engine percent torque (indicated) to maximum indicated torque available at the current engine speed,";
CM_ SG_ 2566835710 EngCoolantTemp "Temperature of liquid found in engine cooling system.";
CM_ SG_ 2566835710 DTC1 "Diagnostic Trouble Code";
CM_ BO_ 2566835454 "Diagnostic data clear/reset of previously active DTCs.";
CM_ BO_ 2566764542 "Expanded freeze frame.";
CM_ SG_ 2566764542 ExpandedFreezeFrameLength "The freeze frame length shall be equal to the number of bytes in the required parameters plus the number of bytes in the
manufacturer specific parameters.";
CM_ SG_ 2566764542 DTC1 "Diagnostic Trouble Code";
CM_ BO_ 2566764286 "SPN Support. This message is used to identify those SPNs supported by the product for freeze frames and data stream messages.";
CM_ SG_ 2566764286 SPNSupported1High "This parameter defines the SPN(s) that is/are supported for the freeze frame and/or data stream information.";
CM_ SG_ 2566764286 SPNSupportTypeSTR3 "This parameter defines whether the applicable parameter (that is the SPN) is supported in the freeze frame, the data stream or both the freeze frame and data stream.";
CM_ SG_ 2566764286 SPNSupportTypeSTR2 "This parameter defines whether the applicable parameter (that is the SPN) is supported in the freeze frame, the data stream or both the freeze frame and data stream.";
CM_ SG_ 2566764286 SPNSupportTypeEFF3 "This parameter defines whether the applicable parameter (that is the SPN) is supported in the freeze frame, the data stream or both the freeze frame and data stream.";
CM_ SG_ 2566764286 SPNSupportTypeEFF2 "This parameter defines whether the applicable parameter (that is the SPN) is supported in the freeze frame, the data stream or both the freeze frame and data stream.";
CM_ SG_ 2566764286 SPNSupportTypeDS3 "This parameter defines whether the applicable parameter (that is the SPN) is supported in the freeze frame, the data stream or both the freeze frame and data stream.";
CM_ SG_ 2566764286 SPNSupportTypeDS2 "This parameter defines whether the applicable parameter (that is the SPN) is supported in the freeze frame, the data stream or both the freeze frame and data stream.";
CM_ SG_ 2566764286 SPNSupported3High "This parameter defines the SPN(s) that is/are supported for the freeze frame and/or data stream information.";
CM_ SG_ 2566764286 SPNSupported2High "This parameter defines the SPN(s) that is/are supported for the freeze frame and/or data stream information.";
CM_ SG_ 2566764286 SPNSupported3 "This parameter defines the SPN(s) that is/are supported for the freeze frame and/or data stream information.";
CM_ SG_ 2566764286 SPNSupported2 "This parameter defines the SPN(s) that is/are supported for the freeze frame and/or data stream information.";
CM_ SG_ 2566764286 SPNDataLength3 "The number of data bytes associated with the SPN in the Freeze Frame.";
CM_ SG_ 2566764286 SPNSupportTypeSTR1 "This parameter defines whether the applicable parameter (that is the SPN) is supported in the freeze frame, the data stream or both the freeze frame and data stream.";
CM_ SG_ 2566764286 SPNSupportTypeDS1 "This parameter defines whether the applicable parameter (that is the SPN) is supported in the freeze frame, the data stream or both the freeze frame and data stream.";
CM_ SG_ 2566764286 SPNSupportTypeEFF1 "This parameter defines whether the applicable parameter (that is the SPN) is supported in the freeze frame, the data stream or both the freeze frame and data stream.";
CM_ SG_ 2566764286 SPNDataLength2 "The number of data bytes associated with the SPN in the Freeze Frame.";
CM_ SG_ 2566764286 SPNDataLength1 "The number of data bytes associated with the SPN in the Freeze Frame.";
CM_ SG_ 2566764286 SPNSupported1 "This parameter defines the SPN(s) that is/are supported for the freeze frame and/or data stream information.";
CM_ BO_ 2566764030 "Previously active emission related faults.";
CM_ SG_ 2566764030 FlashRedStopLamp "This parameter provides the capability to flash the RSL (SPN 3039).";
CM_ SG_ 2566764030 FlashProtectLamp "This parameter provides the capability to flash the engine protect lamp (SPN 3041).";
CM_ SG_ 2566764030 FlashMalfuncIndicatorLamp "This parameter provides the capability to flash the MIL (SPN 3038).";
CM_ SG_ 2566764030 FlashAmberWarningLamp "This parameter provides the capability to flash the AWL (SPN 3040). ";
CM_ SG_ 2566764030 MalfunctionIndicatorLampStatus "A lamp used to relay only emissions-related trouble code information.";
CM_ SG_ 2566764030 RedStopLampState "This lamp is uesed to relay trouble code information that is of a severe enought condition that it warrants stopping the vehicle.";
CM_ SG_ 2566764030 AmberWarningLampStatus "This lamp is used to relay trouble code information that is reporting a problem with the vehicle system but the vehicle need
not be immediately stopped.";
CM_ SG_ 2566764030 ProtectLampStatus "This lamp is used to relay trouble code informatio that is reporting a problem with a vehicle system that is most
probably not electronic subsystem related.";
CM_ SG_ 2566764030 DTC5 "Diagnostic Trouble Code";
CM_ SG_ 2566764030 DTC4 "Diagnostic Trouble Code";
CM_ SG_ 2566764030 DTC3 "Diagnostic Trouble Code";
CM_ SG_ 2566764030 DTC2 "Diagnostic Trouble Code";
CM_ SG_ 2566764030 DTC1 "Diagnostic Trouble Code";
CM_ BO_ 2562981630 "Individual Clear/Reset of active and previously active DTC.";
CM_ SG_ 2562981630 SPN1 "SPN #1 (Conversion Version 4)";
CM_ SG_ 2562981630 SPN1High "SPN #1 (Conversion Version 4)";
CM_ SG_ 2562981630 FailureModeIdentifier1 "The FMI defines the type of failure detected in the subsystem identified by an SPN.";
CM_ BO_ 2562850558 "Diagnostic readiness 2";
CM_ SG_ 2562850558 TimeSinceDTCsCleared "Time accumulated since DTCs were cleared (via an external test equipment or possibly, a battery disconnect) (SPN=?).";
CM_ SG_ 2562850558 MinutesRunByEngineMILActivated "Accumulated count (in minutes) while the MIL is activated (on) (SPN=?).";
CM_ SG_ 2562850558 DistanceSinceDTCsCleared "Distance accumulated since DTCs were cleared (SPN=?).";
CM_ SG_ 2562850558 DistanceWhileMILisActivated "The kilometers accumulated while the MIL is activated (SPN 3060).";
CM_ BO_ 2562916094 "Monitor Performance Ratio";
CM_ SG_ 2562916094 ApplSysMonitorDenominator "The number of times a vehicle has been operated that constitutes a driving cycle where this Applicable System Monitor could be operated per regulatory requirements (SPN 3068).";
CM_ SG_ 2562916094 ApplSysMonitorNumerator "The number of times a vehicle has been operated such that all conditions necessary for the Applicable System Monitor to detect a malfunction have been encountered (SPN 3067).";
CM_ SG_ 2562916094 SPNofApplSysMonitor "Contain the SPN of the system monitor for which Monitor ratio is being reported (SPN 3066).";
CM_ SG_ 2562916094 OBDMonitoringCondEncountered "Displays the number of times that the vehicle has been operated in the specified OBD monitoring conditions (SPN 3049).";
CM_ SG_ 2562916094 IgnitionCycleCounter "A single counter that defines the number of ignition cycles (SPN 3048).";
CM_ BO_ 2564030206 "Calibration Information";
CM_ BO_ 2564226814 "Boot Load Data";
CM_ BO_ 2564292350 "Binary Data Transfer";
CM_ SG_ 2564292350 NumberOfOccurance "Number of occurance of raw binary data";
CM_ BO_ 2564357886 "Memory Access Response";
CM_ SG_ 2564357886 ErrorIndicator "Error Indicator/EDC Parameter";
CM_ BO_ 2564423422 "Memory Access Request";
CM_ SG_ 2564423422 KeyOrUserLevel "Key/User Level";
CM_ SG_ 2564423422 Command "Process Data Command";
CM_ SG_ 2564423422 NumberRequested "Length/Number Requested";
CM_ SG_ 2564423422 NumberRequestedHigh "Length/Number Requested";
CM_ BO_ 2564816638 "Stop start broadcast";
CM_ SG_ 2564816638 HoldSignal "Indicator to all nodes that the communication ports that have been acted upon by the 'Stop start broadcast'
PGN are remaining in the modified state.";
CM_ SG_ 2564816638 J1939Network3 "Identifies the action to be performed on the SAE J1939 Network #3.";
CM_ SG_ 2564816638 J1939Network2 "Identifies the action to be performed on the SAE J1939 Network #2.";
CM_ SG_ 2564816638 ISO9141 "Identifies the action to be performed on the ISO9141 communications port.";
CM_ SG_ 2564816638 SAE_J1850 "Identifies the action to be performed on the SAE J1850 communications port.";
CM_ SG_ 2564816638 ManufacturerSpecificPort "Identifies the action to be performed on 'Other, manufacturer specific port' communications port.";
CM_ SG_ 2564816638 CurrentDataLink "Identifies the action to be performed on the communications port that this parameter was received.";
CM_ SG_ 2564816638 SAE_J1587 "Identifies the action to be performed on the SAE J1587 communications port.";
CM_ SG_ 2564816638 SAE_J1922 "Identifies the action to be performed on the SAE J1922 communications port.";
CM_ SG_ 2564816638 J1939Network1 "Identifies the action to be performed on the SAE J1939 Network #1, Primary vehicle communications port.";
CM_ BO_ 2566837502 "Emissions-related active diagnostic trouble codes.";
CM_ SG_ 2566837502 FlashRedStopLamp "This parameter provides the capability to flash the RSL (SPN 3039).";
CM_ SG_ 2566837502 FlashProtectLamp "This parameter provides the capability to flash the engine protect lamp (SPN 3041).";
CM_ SG_ 2566837502 MalfunctionIndicatorLampStatus "A lamp used to relay only emissions-related trouble code information.";
CM_ SG_ 2566837502 RedStopLampState "This lamp is uesed to relay trouble code information that is of a severe enought condition that it warrants stopping the vehicle.";
CM_ SG_ 2566837502 AmberWarningLampStatus "This lamp is used to relay trouble code information that is reporting a problem with the vehicle system but the vehicle need
not be immediately stopped.";
CM_ SG_ 2566837502 ProtectLampStatus "This lamp is used to relay trouble code informatio that is reporting a problem with a vehicle system that is most
probably not electronic subsystem related.";
CM_ SG_ 2566837502 FlashMalfuncIndicatorLamp "This parameter provides the capability to flash the MIL (SPN 3038).";
CM_ SG_ 2566837502 FlashAmberWarningLamp "This parameter provides the capability to flash the AWL (SPN 3040). ";
CM_ SG_ 2566837502 DTC5 "Diagnostic Trouble Code";
CM_ SG_ 2566837502 DTC4 "Diagnostic Trouble Code";
CM_ SG_ 2566837502 DTC3 "Diagnostic Trouble Code";
CM_ SG_ 2566837502 DTC2 "Diagnostic Trouble Code";
CM_ SG_ 2566837502 DTC1 "Diagnostic Trouble Code";
CM_ BO_ 2566837246 "Diagnostic data clear/Reset for active DTCs";
CM_ BO_ 2566836990 "Non-continously monitored systems test identifiers support";
CM_ SG_ 2566836990 TestIdentifierSupported "Indicates the test identifiers that the controller supports.";
CM_ BO_ 2566834942 "Active diagnostic trouble codes";
CM_ SG_ 2566834942 FlashRedStopLamp "This parameter provides the capability to flash the RSL (SPN 3039).";
CM_ SG_ 2566834942 FlashProtectLamp "This parameter provides the capability to flash the engine protect lamp (SPN 3041).";
CM_ SG_ 2566834942 FlashMalfuncIndicatorLamp "This parameter provides the capability to flash the MIL (SPN 3038).";
CM_ SG_ 2566834942 FlashAmberWarningLamp "This parameter provides the capability to flash the AWL (SPN 3040). ";
CM_ SG_ 2566834942 MalfunctionIndicatorLampStatus "A lamp used to relay only emissions-related trouble code information.";
CM_ SG_ 2566834942 AmberWarningLampStatus "This lamp is used to relay trouble code information that is reporting a problem with the vehicle system but the vehicle need
not be immediately stopped.";
CM_ SG_ 2566834942 RedStopLampState "This lamp is uesed to relay trouble code information that is of a severe enought condition that it warrants stopping the vehicle.";
CM_ SG_ 2566834942 ProtectLampStatus "This lamp is used to relay trouble code informatio that is reporting a problem with a vehicle system that is most
probably not electronic subsystem related.";
CM_ BO_ 2566780926 "Utility Total AC Reactive Power";
CM_ SG_ 2566780926 UtlityOverallPowerFactorLagging "Lead/lag status for utility incomer average power factor.";
CM_ SG_ 2566780926 UtilityOverallPowerFactor "The average power factor of the utility incomer.";
CM_ SG_ 2566780926 UtilityTotalReactivePower "The total reactive power delivered by the utility incomer";
CM_ BO_ 2566781182 "Utility Total AC Power";
CM_ SG_ 2566781182 UtilityTotalApparentPower "The total apparent power delivered by the utility incomer.";
CM_ SG_ 2566781182 UtilityTotalRealPower "Total real power delivered by the utility incomer.";
CM_ BO_ 2566778366 "Utility Total AC Energy";
CM_ SG_ 2566778366 UtilityTotalKWHoursImport "The total kilowatt-hours that have been imported by the utility incomer.";
CM_ SG_ 2566778366 UtilityTotalKWHoursExport "The total kilowatt-hours that have been exported by the utility incomer.";
CM_ BO_ 2566778622 "Utility Phase C AC Reactive Power";
CM_ SG_ 2566778622 UtilityPhaseCPowerFactorLagging "Lead/lag status for utility incomer phase C power factor.";
CM_ SG_ 2566778622 UtilityPhaseCPowerFactor "The power factor of phases C of the utility incomer.";
CM_ SG_ 2566778622 UtilityPhaseCReactivePower "The reactive power delivered by phase C of the utility incomer";
CM_ BO_ 2566778878 "Utility Phase C AC Power";
CM_ SG_ 2566778878 UtilityPhaseCApparentPower "The apparent power delivered by phase C of the utility incomer.";
CM_ SG_ 2566778878 UtilityPhaseCRealPower "The real power delivered by phase C of the utility incomer.";
CM_ BO_ 2566779134 "Utility Phase C AC Basic Quantities";
CM_ SG_ 2566779134 UtilityPhaseCACRMSCurrent "RMS current measured at the utility incomer phase C.";
CM_ SG_ 2566779134 UtilityPhaseCACFrequency "AC frequency measured at the utility incomer phase C.";
CM_ SG_ 2566779134 UtltyPhsCLneNeutralACRMSVoltage "Line to Neutral RMS voltage measured at the utility incomer phase C.";
CM_ SG_ 2566779134 UtltyPhseCALineLineACRMSVoltage "Line to Line RMS voltage measured at the utility incomer phase CA.";
CM_ BO_ 2566779390 "Utility Phase B AC Reactive Power";
CM_ SG_ 2566779390 UtilityPhaseBPowerFactorLagging "Lead/lag status for utility incomer phase B power factor.";
CM_ SG_ 2566779390 UtilityPhaseBPowerFactor "The power factor of phases B of the utility incomer.";
CM_ SG_ 2566779390 UtilityPhaseBReactivePower "The reactive power delivered by phase B of the utility incomer";
CM_ BO_ 2566779646 "Utility Phase B AC Power";
CM_ SG_ 2566779646 UtilityPhaseBApparentPower "The apparent power delivered by phase B of the utility incomer.";
CM_ SG_ 2566779646 UtilityPhaseBRealPower "The real power delivered by phase B of the utility incomer.";
CM_ BO_ 2566779902 "Utility Phase B AC Basic Quantities";
CM_ SG_ 2566779902 UtilityPhaseBACRMSCurrent "RMS current measured at the utility incomer phase B.";
CM_ SG_ 2566779902 UtilityPhaseBACFrequency "AC frequency measured at the utility incomer phase B.";
CM_ SG_ 2566779902 UtltyPhsBLneNeutralACRMSVoltage "Line to Neutral RMS voltage measured at the utility incomer phase B.";
CM_ SG_ 2566779902 UtltyPhseBCLineLineACRMSVoltage "Line to Line RMS voltage measured at the utility incomer phase BC.";
CM_ BO_ 2566780158 "Utility Phase A  AC Reactive Power";
CM_ SG_ 2566780158 UtilityPhaseAPowerFactorLagging "Lead/lag status for utility incomer phase A power factor.";
CM_ SG_ 2566780158 UtilityPhaseAPowerFactor "The power factor of phase A of the utility incomer.";
CM_ SG_ 2566780158 UtilityPhaseAReactivePower "The reactive power delivered by phase A of the utility incomer";
CM_ BO_ 2566780414 "Utility Phase A  AC Power";
CM_ SG_ 2566780414 UtilityPhaseAApparentPower "The apparent power delivered by phase A of the utility incomer.";
CM_ SG_ 2566780414 UtilityPhaseARealPower "The real power delivered by phase A of the utility incomer.";
CM_ BO_ 2566780670 "Utility Phase A Basic AC Quantities";
CM_ SG_ 2566780670 UtilityPhaseAACRMSCurrent "RMS current measured at the utility incomer phase A.";
CM_ SG_ 2566780670 UtilityPhaseAACFrequency "AC frequency measured at the utility incomer phase A.";
CM_ SG_ 2566780670 UtltyPhsALneNeutralACRMSVoltage "Line to Neutral RMS voltage measured at the utility incomer phase A.";
CM_ SG_ 2566780670 UtltyPhseABLineLineACRMSVoltage "Line to Line RMS voltage measured at the utility incomer phase AB.";
CM_ BO_ 2566781438 "Utility Average Basic AC Quantities";
CM_ SG_ 2566781438 UtilityAverageACRMSCurrent "Average RMS current measured at the utility incomer.";
CM_ SG_ 2566781438 UtilityAverageACFrequency "Average AC frequency measured at the utility incomer.";
CM_ SG_ 2566781438 UtltyAvrgLneNeutralACRMSVoltage "The average Line to Neutral AC RMS voltage measured at the utility incomer .";
CM_ SG_ 2566781438 UtltyAvrageLineLineACRMSVoltage "Average Line to Line RMS voltage measured at the utility incomer .";
CM_ BO_ 2566784254 "Generator Total AC Reactive Power";
CM_ SG_ 2566784254 GnrtorOverallPowerFactorLagging "Lead/lag status for generator average power factor.";
CM_ SG_ 2566784254 GeneratorOverallPowerFactor "The average power factor of the generator.";
CM_ SG_ 2566784254 GeneratorTotalReactivePower "The total reactive power delivered by the generator";
CM_ BO_ 2566784510 "Generator Total AC Power";
CM_ SG_ 2566784510 GeneratorTotalApparentPower "The total apparent power delivered by the generator.";
CM_ SG_ 2566784510 GeneratorTotalRealPower "Total real power delivered by the generator.";
CM_ BO_ 2566781694 "Generator Total AC Energy";
CM_ SG_ 2566781694 GeneratorTotalKWHoursImport "The total kilowatt-hours that have been imported by the generator.";
CM_ SG_ 2566781694 GeneratorTotalKWHoursExport "The total kilowatt-hours that have been exported by the generator.";
CM_ BO_ 2566781950 "Generator Phase C AC Reactive Power";
CM_ SG_ 2566781950 GnratorPhaseCPowerFactorLagging "Lead/lag status for generator phase C power factor.";
CM_ SG_ 2566781950 GeneratorPhaseCPowerFactor "The power factor of phases C of the generator.";
CM_ SG_ 2566781950 GeneratorPhaseCReactivePower "The reactive power delivered by phase C of the generator";
CM_ BO_ 2566782206 "Generator Phase C AC Power";
CM_ SG_ 2566782206 GeneratorPhaseCApparentPower "The apparent power delivered by phase C of the generator.";
CM_ SG_ 2566782206 GeneratorPhaseCRealPower "The real power delivered by phase C of the generator.";
CM_ BO_ 2566782462 "Generator Phase C Basic AC Quantities";
CM_ SG_ 2566782462 GeneratorPhaseCACRMSCurrent "RMS current measured at the generator phase C output.";
CM_ SG_ 2566782462 GeneratorPhaseCACFrequency "AC frequency measured at the generator phase C output.";
CM_ SG_ 2566782462 GnrtrPhsCLneNeutralACRMSVoltage "Line to Neutral RMS voltage measured at the generator phase C output.";
CM_ SG_ 2566782462 GnrtrPhseCALineLineACRMSVoltage "Line to Line RMS voltage measured at the generator phase CA output.";
CM_ BO_ 2566782718 "Generator Phase B AC Reactive Power";
CM_ SG_ 2566782718 GnratorPhaseBPowerFactorLagging "Lead/lag status for generator phase B power factor.";
CM_ SG_ 2566782718 GeneratorPhaseBPowerFactor "The power factor of phases B of the generator.";
CM_ SG_ 2566782718 GeneratorPhaseBReactivePower "The reactive power delivered by phase B of the generator";
CM_ BO_ 2566782974 "Generator Phase B AC Power";
CM_ SG_ 2566782974 GeneratorPhaseBApparentPower "The apparent power delivered by phase B of the generator.";
CM_ SG_ 2566782974 GeneratorPhaseBRealPower "The real power delivered by phase B of the generator.";
CM_ BO_ 2566783230 "Generator Phase B Basic AC Quantities";
CM_ SG_ 2566783230 GeneratorPhaseBACRMSCurrent "RMS current measured at the generator phase B output.";
CM_ SG_ 2566783230 GeneratorPhaseBACFrequency "AC frequency measured at the generator phase B output.";
CM_ SG_ 2566783230 GnrtrPhsBLneNeutralACRMSVoltage "Line to Neutral RMS voltage measured at the generator phase B output.";
CM_ SG_ 2566783230 GnrtrPhseBCLineLineACRMSVoltage "Line to Line RMS voltage measured at the generator phase BC output.";
CM_ BO_ 2566783486 "Generator Phase A AC Reactive Power";
CM_ SG_ 2566783486 GnratorPhaseAPowerFactorLagging "Lead/lag status for generator phase A power factor.";
CM_ SG_ 2566783486 GeneratorPhaseAPowerFactor "The power factor of phase A of the generator.";
CM_ SG_ 2566783486 GeneratorPhaseAReactivePower "The reactive power delivered by phase A of the generator";
CM_ BO_ 2566783742 "Generator Phase A AC Power";
CM_ SG_ 2566783742 GeneratorPhaseAApparentPower "The apparent power delivered by phase A of the generator.";
CM_ SG_ 2566783742 GeneratorPhaseARealPower "The real power delivered by phase A of the generator.";
CM_ BO_ 2566783998 "Generator Phase A Basic AC Quantities";
CM_ SG_ 2566783998 GeneratorPhaseAACRMSCurrent "RMS current measured at the generator phase A output.";
CM_ SG_ 2566783998 GeneratorPhaseAACFrequency "AC frequency measured at the generator phase A output.";
CM_ SG_ 2566783998 GnrtrPhsALneNeutralACRMSVoltage "Line to Neutral RMS voltage measured at the generator phase A output.";
CM_ SG_ 2566783998 GnrtrPhseABLineLineACRMSVoltage "Line to Line RMS voltage measured at the generator phase AB output.";
CM_ BO_ 2566784766 "Generator Average Basic AC Quantities";
CM_ SG_ 2566784766 GeneratorAverageACRMSCurrent "Average RMS current measured at the generator output.";
CM_ SG_ 2566784766 GeneratorAverageACFrequency "Average AC frequency measured at the generator output.";
CM_ SG_ 2566784766 GnrtrAvrgLneNeutralACRMSVoltage "The average Line to Neutral AC RMS voltage measured at the Generator output.";
CM_ SG_ 2566784766 GnrtrAvrageLineLineACRMSVoltage "Average Line to Line RMS voltage measured at the generator output.";
CM_ BO_ 2566776830 "Bus #1/Utility Sync Check Status";
CM_ SG_ 2566776830 Bus1_UtilityACPhaseDifference "The phase difference between the Bus #1 voltage and Utility voltage.";
CM_ SG_ 2566776830 Bus1_UtilityInSync "Indicator of whether Bus #1 and Utility are properly synchronized for paralleling. This indicator will be based on parameters such as Voltage Match, Frequency Match, and Phase Match.";
CM_ SG_ 2566776830 Bus1_UtilityVoltageMatch "Indicator of whether voltage difference between Bus #1 and Utility is adequate for paralleling. This indicator will be based on the measured AC voltages qualified using parameters such as Voltage Tolerance.";
CM_ SG_ 2566776830 Bus1_UtilityFrequencyMatch "Indicator of whether frequency difference between Bus #1 and Utility is adequate for paralleling. This indicator will be based on the measured AC frequencies qualified using parameters such as Frequency Tolerance, Phase Tolerance, and Dwell Time.";
CM_ SG_ 2566776830 Bus1_UtilityPhaseMatch "Indicator of whether phase difference between Bus #1 and Utility is adequate for paralleling. This indicator will be based on the measured AC phase difference qualified using parameters such as Phase Tolerance and Dwell Time.";
CM_ SG_ 2566776830 Bus1_UtilityDeadBus "Indicator of whether Bus #1 is considered dead for closing to the utility. This indicator will be based on parameters such as Bus #1 Voltage and dead bus threshold values.";
CM_ BO_ 2566777342 "Bus #1 Phase C  Basic AC Quantities";
CM_ SG_ 2566777342 Bus1PhaseCACFrequency "AC frequency measured at bus #1 phase C.";
CM_ SG_ 2566777342 Bs1PhseCLineNeutralACRMSVoltage "Line to Neutral RMS voltage measured at bus #1 phase C.";
CM_ SG_ 2566777342 Bus1PhaseCALineLineACRMSVoltage "Line to Line RMS voltage measured at bus #1 phase CA.";
CM_ BO_ 2566777598 "Bus #1 Phase B  Basic AC Quantities";
CM_ SG_ 2566777598 Bus1PhaseBACFrequency "AC frequency measured at bus #1 phase B.";
CM_ SG_ 2566777598 Bs1PhseBLineNeutralACRMSVoltage "Line to Neutral RMS voltage measured at bus #1 phase B.";
CM_ SG_ 2566777598 Bus1PhaseBCLineLineACRMSVoltage "Line to Line RMS voltage measured at bus #1 phase BC.";
CM_ BO_ 2566777854 "Bus #1 Phase A  Basic AC Quantities";
CM_ SG_ 2566777854 Bus1PhaseAACFrequency "AC frequency measured at bus #1 phase A.";
CM_ SG_ 2566777854 Bs1PhseALineNeutralACRMSVoltage "Line to Neutral RMS voltage measured at bus #1 phase A.";
CM_ SG_ 2566777854 Bus1PhaseABLineLineACRMSVoltage "Line to Line RMS voltage measured at bus #1 phase AB.";
CM_ BO_ 2566777086 "Bus #1/Generator Sync Check Status";
CM_ SG_ 2566777086 Bus1_GeneratorACPhaseDifference "The phase difference between the Bus #1 voltage and Generator voltage.";
CM_ SG_ 2566777086 Bus1_GeneratorInSync "Indicator of whether Bus #1 and Generator are properly synchronized for paralleling. This indicator will be based on parameters such as Voltage Match, Frequency Match, and Phase Match.";
CM_ SG_ 2566777086 Bus1_GeneratorVoltageMatch "Indicator of whether voltage difference between Bus #1 and Generator is adequate for paralleling. This indicator will be based on the measured AC voltages qualified using parameters such as Voltage Tolerance.";
CM_ SG_ 2566777086 Bus1_GeneratorFrequencyMatch "Indicator of whether frequency difference between Bus #1 and Generator is adequate for paralleling. This indicator will be based on the measured AC frequencies qualified using parameters such as Frequency Tolerance, Phase Tolerance, and Dwell Time.";
CM_ SG_ 2566777086 Bus1_GeneratorPhaseMatch "Indicator of whether phase difference between Bus #1 and Generator is adequate for paralleling. This indicator will be based on the measured AC phase difference qualified using parameters such as Phase Tolerance and Dwell Time.";
CM_ SG_ 2566777086 Bus1_GeneratorDeadBus "Indicator of whether Bus #1 is considered dead for closing to the generator. This indicator will be based on parameters such as Bus #1 Voltage and dead bus threshold values.";
CM_ BO_ 2566778110 "Bus #1 Average Basic AC Quantities";
CM_ SG_ 2566778110 Bus1AverageACFrequency "Average AC frequency measured at bus #1.";
CM_ SG_ 2566778110 Bs1AvrgeLineNeutralACRMSVoltage "The average Line to Neutral AC RMS voltage measured at bus #1 .";
CM_ SG_ 2566778110 Bus1AverageLineLineACRMSVoltage "Average Line to Line RMS voltage measured at bus #1 .";
CM_ BO_ 2633895422 "Working Set Master";
CM_ BO_ 2566838526 "Commanded Address";
CM_ SG_ 2566838526 AddressAssignment "The source address that is to be assigned to the CA that has the NAME corresponding to the one conveyed in the first eight bytes of this Commanded Address message.";
CM_ SG_ 2566838526 IndustryGroup "0 = Global; 
   1  = On-Highway; 
   2  = Agricultural and Forestry; 
   3  = Construction; 
   4  = Marine;
   5  = Industrial - Process
          Control - Stationary (Gen-Sets)
   6  = Reserve for SAE
   7  = Reserve for SAE";
CM_ SG_ 2566838526 ManufacturerCode "Assigned by NMEA 2000 Committee";
CM_ BO_ 2565799678 "Address Claimed";
CM_ BO_ 2563440382 "Transfer";
CM_ SG_ 2563440382 ShrtNameOfActualReportingDevice "Short name of reporting device of the requested PGN via the Transfer PGN.";
CM_ SG_ 2563440382 LengthOfDataForTheReportedPGN "Length of data reported with the associated PGN via the Transfer PGN.";
CM_ SG_ 2563440382 PGNofRequstedInformation "PGN associated with this transfer message";
CM_ BO_ 2632711934 "Transport Protocol - Data Transfer";
CM_ BO_ 2632777470 "Transport Protocol - Connection Management";
CM_ SG_ 2632777470 TotalNumberOfPacketsEoMA "Total number of packets for BAM message.Total number of packets received for RTS/CTS message.Total number of packets for RTS/CTS message.";
CM_ SG_ 2632777470 TotalMessageSizeEoMA "Total message size (in bytes) for BAM message.Total message size (in bytes) for RTS/CTS message.Total message size (in bytes) for RTS/CTS message.";
CM_ SG_ 2632777470 TotalMessageSizeBAM "Total message size (in bytes) for BAM message.Total message size (in bytes) for RTS/CTS message.Total message size (in bytes) for RTS/CTS message.";
CM_ SG_ 2632777470 TotalNumberOfPacketsBAM "Total number of packets for BAM message.Total number of packets received for RTS/CTS message.Total number of packets for RTS/CTS message.";
CM_ SG_ 2632777470 NextPacketNumberToBeSent "Next Packet Number to be sent (TP.CM_CTS)";
CM_ SG_ 2632777470 NumberOfPacketsThatCanBeSent "Number of Packets that can be sent (TP.CM_CTS)";
CM_ SG_ 2632777470 MaximumNumberOfPackets "Maximum number of packets for RTS/CTS message.";
CM_ SG_ 2632777470 TotalNumberOfPackets "Total number of packets for BAM message.Total number of packets received for RTS/CTS message.Total number of packets for RTS/CTS message.";
CM_ SG_ 2632777470 TotalMessageSize "Total message size (in bytes) for BAM message.Total message size (in bytes) for RTS/CTS message.Total message size (in bytes) for RTS/CTS message.";
CM_ BO_ 2563374846 "Request 2";
CM_ SG_ 2563374846 UseTransferMode "Requester is to respond via the Transfer PGN";
CM_ SG_ 2563374846 ParameterGroupNumber "PGN which is requested by Request2 message";
CM_ BO_ 2565537534 "Request";
CM_ SG_ 2565537534 ParameterGroupNumber "PGN which is requested by Request2 message";
CM_ BO_ 2499635966 "Combination of specific axle group and the weight imposed on that axle group";
CM_ SG_ 2499635966 AxleGroupWeight "Total mass imposed on the road surface by all the tires in the axle group";
CM_ SG_ 2499635966 AxleGroupLocation "Specific axle group used in conjunction with and when communicating the axle group weight, listed from the front of the";
CM_ BO_ 2633853438 "Indicates axle group calibration weights";
CM_ SG_ 2633853438 AxleGroupLocation "Specific axle group used in conjunction with and when communicating the axle group calibration, listed from the front of";
CM_ SG_ 2633853438 AxleGroupFullWeightCalib "The full weight calibration measurement of an axle group";
CM_ SG_ 2633853438 AxleGroupEmptyWeightCalib "The empty weight calibration measurement of an axle group";
CM_ BO_ 2432520702 "Transmit status information from the Master ECU to an electronic thermostat";
CM_ SG_ 2432520702 DsrdAftrclrClntThermostatOpening "Used to transmit the desired position of the low temperature aftercooler temperature control valve. 0% represents the";
CM_ SG_ 2432520702 DsrdAftercoolerCoolantIntakeTemp "Indicates the desired temperature of the fluid in the low temperature aftercooler circuit to an electronic thermostat. If the";
CM_ SG_ 2432520702 AftercoolerCoolantThermostatMode "Specifies if the aftercooler coolant thermostat valve will operate in temperature control mode or position control mode.";
CM_ BO_ 2566745086 "Indicates which axle groups are included in the current weight calculation";
CM_ SG_ 2566745086 AddtnlTrlrAxlGrupWeightAvailable "Indicates the availability of the additional trailer axle group for purposes of weight measurement";
CM_ SG_ 2566745086 TrailerHAxleGroupWeightAvailable "Indicates the availability of the trailer H axle group for purposes of weight measurement";
CM_ SG_ 2566745086 TrailerGAxleGroupWeightAvailable "Indicates the availability of the trailer G axle group for purposes of weight measurement";
CM_ SG_ 2566745086 TrailerFAxleGroupWeightAvailable "Indicates the availability of the trailer F axle group for purposes of weight measurement";
CM_ SG_ 2566745086 TrailerEAxleGroupWeightAvailable "Indicates the availability of the trailer E axle group for purposes of weight measurement";
CM_ SG_ 2566745086 TrailerDAxleGroupWeightAvailable "Indicates the availability of the trailer D axle group for purposes of weight measurement";
CM_ SG_ 2566745086 TrailerCAxleGroupWeightAvailable "Indicates the availability of the trailer C axle group for purposes of weight measurement";
CM_ SG_ 2566745086 TrailerBAxleGroupWeightAvailable "Indicates the availability of the trailer B axle group for purposes of weight measurement";
CM_ SG_ 2566745086 TrailerAAxleGroupWeightAvailable "Indicates the availability of the trailer A axle group for purposes of weight measurement";
CM_ SG_ 2566745086 AddtnlTrctrAxlGrpWeightAvailable "Indicates the availability of the additional tractor axle group for purposes of weight measurement";
CM_ SG_ 2566745086 TagAxleGroupWeightAvailable "Indicates the availability of the tag axle group for purposes of weight measurement";
CM_ SG_ 2566745086 DriveAxleGroupWeightAvailable "Indicates the availability of the drive axle group for purposes of weight measurement";
CM_ SG_ 2566745086 LiftAxleGroupWeightAvailable "Indicates the availability of the lift axle group for purposes of weight measurement";
CM_ SG_ 2566745086 SteerAxleGroupWeightAvailable "Indicates the availability of the steer axle group for purposes of weight measurement";
CM_ BO_ 2566739198 "Class C, Previously Active";
CM_ SG_ 2566739198 FlashRedStopLamp "This parameter provides the capability to flash the RSL (SPN 3039).";
CM_ SG_ 2566739198 FlashProtectLamp "This parameter provides the capability to flash the engine protect lamp (SPN 3041).";
CM_ SG_ 2566739198 FlashMalfuncIndicatorLamp "This parameter provides the capability to flash the MIL (SPN 3038).";
CM_ SG_ 2566739198 FlashAmberWarningLamp "This parameter provides the capability to flash the AWL (SPN 3040). ";
CM_ SG_ 2566739198 MalfunctionIndicatorLampStatus "A lamp used to relay only emissions-related trouble code information.";
CM_ SG_ 2566739198 AmberWarningLampStatus "This lamp is used to relay trouble code information that is reporting a problem with the vehicle system but the vehicle need
not be immediately stopped.";
CM_ SG_ 2566739198 RedStopLampState "This lamp is uesed to relay trouble code information that is of a severe enought condition that it warrants stopping the vehicle.";
CM_ SG_ 2566739198 ProtectLampStatus "This lamp is used to relay trouble code informatio that is reporting a problem with a vehicle system that is most
probably not electronic subsystem related.";
CM_ SG_ 2566739198 DTC5 "Diagnostic Trouble Code";
CM_ SG_ 2566739198 DTC4 "Diagnostic Trouble Code";
CM_ SG_ 2566739198 DTC3 "Diagnostic Trouble Code";
CM_ SG_ 2566739198 DTC2 "Diagnostic Trouble Code";
CM_ SG_ 2566739198 DTC1 "Diagnostic Trouble Code";
BA_DEF_ BO_  "GenMsgCycleTimeFast" INT 0 3600000;
BA_DEF_ SG_  "SigType" ENUM  "Default","Range","RangeSigned","ASCII","Discrete","Control","ReferencePGN","DTC","StringDelimiter","StringLength","StringLengthControl";
BA_DEF_ SG_  "GenSigStartValue" INT 0 10000;
BA_DEF_ SG_  "GenSigSendType" ENUM  "Cyclic","OnWrite","reserved","OnChange","reserved","reserved","reserved","NoSigSendType";
BA_DEF_ SG_  "GenSigILSupport" ENUM  "Yes","No";
BA_DEF_ SG_  "GenSigEVName" STRING ;
BA_DEF_ SG_  "SPN" INT 0 524287;
BA_DEF_ SG_  "DDI" INT 0 65535;
BA_DEF_ SG_  "SAEDocument" STRING ;
BA_DEF_ BO_  "GenMsgStartDelayTime" INT 0 100000;
BA_DEF_ BO_  "GenMsgILSupport" ENUM  "Yes","No";
BA_DEF_ BO_  "GenMsgRequestable" INT 0 1;
BA_DEF_ BO_  "GenMsgSendType" ENUM  "cyclic","reserved","cyclicIfActive","reserved","reserved","reserved","reserved","reserved","noMsgSendType";
BA_DEF_ BO_  "VFrameFormat" ENUM  "StandardCAN","ExtendedCAN","reserved","J1939PG";
BA_DEF_ BO_  "SingleFrame" INT 0 1;
BA_DEF_ BO_  "GenMsgCycleTime" INT 0 3600000;
BA_DEF_ BO_  "SAE_Document" STRING ;
BA_DEF_ SG_  "SystemSignalLongSymbol" STRING ;
BA_DEF_DEF_  "GenMsgCycleTimeFast" 0;
BA_DEF_DEF_  "SigType" "Default";
BA_DEF_DEF_  "GenSigStartValue" 0;
BA_DEF_DEF_  "GenSigSendType" "NoSigSendType";
BA_DEF_DEF_  "GenSigILSupport" "Yes";
BA_DEF_DEF_  "GenSigEVName" "Env@Nodename_@Signame";
BA_DEF_DEF_  "SPN" 0;
BA_DEF_DEF_  "DDI" 0;
BA_DEF_DEF_  "SAEDocument" "";
BA_DEF_DEF_  "GenMsgStartDelayTime" 0;
BA_DEF_DEF_  "GenMsgILSupport" "Yes";
BA_DEF_DEF_  "GenMsgRequestable" 1;
BA_DEF_DEF_  "GenMsgSendType" "noMsgSendType";
BA_DEF_DEF_  "VFrameFormat" "J1939PG";
BA_DEF_DEF_  "SingleFrame" 1;
BA_DEF_DEF_  "GenMsgCycleTime" 0;
BA_DEF_DEF_  "SAE_Document" "";
BA_DEF_DEF_  "SystemSignalLongSymbol" "";
BA_ "GenMsgSendType" BO_ 2365479678 0;
BA_ "GenMsgCycleTime" BO_ 2365479678 100;
BA_ "SAE_Document" BO_ 2365479678 "J1939-71";
BA_ "GenMsgSendType" BO_ 2566837758 0;
BA_ "GenMsgCycleTime" BO_ 2566837758 1000;
BA_ "SAE_Document" BO_ 2566837758 "J1939-71";
BA_ "SAE_Document" BO_ 2633922558 "J1939-71";
BA_ "GenMsgSendType" BO_ 2566775038 0;
BA_ "GenMsgCycleTime" BO_ 2566775038 1000;
BA_ "SAE_Document" BO_ 2566775038 "J1939-71";
BA_ "SAE_Document" BO_ 2566836478 "J1939-73";
BA_ "SAE_Document" BO_ 2565078782 "J1939-73";
BA_ "SAE_Document" BO_ 2566836222 "J1939-73";
BA_ "SAE_Document" BO_ 2566835966 "J1939-73";
BA_ "SAE_Document" BO_ 2566835710 "J1939-73";
BA_ "SAE_Document" BO_ 2566835454 "J1939-73";
BA_ "SAE_Document" BO_ 2566764542 "J1939-73";
BA_ "SAE_Document" BO_ 2566764286 "J1939-73";
BA_ "SAE_Document" BO_ 2566764030 "J1939-73";
BA_ "SAE_Document" BO_ 2562981630 "J1939-73";
BA_ "SAE_Document" BO_ 2562850558 "J1939-73";
BA_ "SAE_Document" BO_ 2562916094 "J1939-73";
BA_ "SAE_Document" BO_ 2564030206 "J1939-73";
BA_ "SAE_Document" BO_ 2564226814 "J1939-73";
BA_ "SAE_Document" BO_ 2564292350 "J1939-73";
BA_ "SAE_Document" BO_ 2564357886 "J1939-73";
BA_ "SAE_Document" BO_ 2564423422 "J1939-73";
BA_ "SAE_Document" BO_ 2564816638 "J1939-73";
BA_ "SAE_Document" BO_ 2566837502 "J1939-73";
BA_ "SAE_Document" BO_ 2566837246 "J1939-73";
BA_ "SAE_Document" BO_ 2566836990 "J1939-73";
BA_ "SAE_Document" BO_ 2566834942 "J1939-73";
BA_ "SAE_Document" BO_ 2566780926 "J1939-75";
BA_ "SAE_Document" BO_ 2566781182 "J1939-75";
BA_ "SAE_Document" BO_ 2566778366 "J1939-75";
BA_ "SAE_Document" BO_ 2566778622 "J1939-75";
BA_ "SAE_Document" BO_ 2566778878 "J1939-75";
BA_ "SAE_Document" BO_ 2566779134 "J1939-75";
BA_ "SAE_Document" BO_ 2566779390 "J1939-75";
BA_ "SAE_Document" BO_ 2566779646 "J1939-75";
BA_ "SAE_Document" BO_ 2566779902 "J1939-75";
BA_ "SAE_Document" BO_ 2566780158 "J1939-75";
BA_ "SAE_Document" BO_ 2566780414 "J1939-75";
BA_ "SAE_Document" BO_ 2566780670 "J1939-75";
BA_ "SAE_Document" BO_ 2566781438 "J1939-75";
BA_ "SAE_Document" BO_ 2566784254 "J1939-75";
BA_ "SAE_Document" BO_ 2566784510 "J1939-75";
BA_ "SAE_Document" BO_ 2566781694 "J1939-75";
BA_ "SAE_Document" BO_ 2566781950 "J1939-75";
BA_ "SAE_Document" BO_ 2566782206 "J1939-75";
BA_ "SAE_Document" BO_ 2566782462 "J1939-75";
BA_ "SAE_Document" BO_ 2566782718 "J1939-75";
BA_ "SAE_Document" BO_ 2566782974 "J1939-75";
BA_ "SAE_Document" BO_ 2566783230 "J1939-75";
BA_ "SAE_Document" BO_ 2566783486 "J1939-75";
BA_ "SAE_Document" BO_ 2566783742 "J1939-75";
BA_ "SAE_Document" BO_ 2566783998 "J1939-75";
BA_ "SAE_Document" BO_ 2566784766 "J1939-75";
BA_ "SAE_Document" BO_ 2566776830 "J1939-75";
BA_ "SAE_Document" BO_ 2566777342 "J1939-75";
BA_ "SAE_Document" BO_ 2566777598 "J1939-75";
BA_ "SAE_Document" BO_ 2566777854 "J1939-75";
BA_ "SAE_Document" BO_ 2566777086 "J1939-75";
BA_ "SAE_Document" BO_ 2566778110 "J1939-75";
BA_ "SAE_Document" BO_ 2633895422 "J1939-81";
BA_ "SAE_Document" BO_ 2566838526 "J1939-81";
BA_ "SAE_Document" BO_ 2565799678 "J1939-81";
BA_ "SAE_Document" BO_ 2563440382 "J1939-21";
BA_ "SAE_Document" BO_ 2632711934 "J1939-21";
BA_ "SAE_Document" BO_ 2632777470 "J1939-21";
BA_ "SAE_Document" BO_ 2563374846 "J1939-21";
BA_ "SAE_Document" BO_ 2565537534 "J1939-21";
BA_ "SAE_Document" BO_ 2499635966 "J1939-71";
BA_ "SAE_Document" BO_ 2633853438 "J1939-71";
BA_ "GenMsgSendType" BO_ 2432520702 0;
BA_ "GenMsgCycleTime" BO_ 2432520702 1000;
BA_ "SAE_Document" BO_ 2432520702 "J1939-71";
BA_ "SAE_Document" BO_ 2566745086 "J1939-71";
BA_ "SAE_Document" BO_ 2566739198 "J1939-73";
BA_ "SPN" SG_ 2365479678 MemoryLevel 5432;
BA_ "SAEDocument" SG_ 2365479678 MemoryLevel "J1939-71";
BA_ "SPN" SG_ 2365479678 SuspensionCtrlRefusalInformation 1827;
BA_ "SAEDocument" SG_ 2365479678 SuspensionCtrlRefusalInformation "J1939-71";
BA_ "SigType" SG_ 2365479678 SpeedDependantLevelCtrlStatus 5;
BA_ "SPN" SG_ 2365479678 SpeedDependantLevelCtrlStatus 5296;
BA_ "SAEDocument" SG_ 2365479678 SpeedDependantLevelCtrlStatus "J1939-71";
BA_ "SigType" SG_ 2365479678 AllwLevelCtrlDuringBrakingStatus 5;
BA_ "SPN" SG_ 2365479678 AllwLevelCtrlDuringBrakingStatus 5294;
BA_ "SAEDocument" SG_ 2365479678 AllwLevelCtrlDuringBrakingStatus "J1939-71";
BA_ "SigType" SG_ 2365479678 SuspensionRemoteCtrl2 4;
BA_ "SPN" SG_ 2365479678 SuspensionRemoteCtrl2 1825;
BA_ "SAEDocument" SG_ 2365479678 SuspensionRemoteCtrl2 "J1939-71";
BA_ "SigType" SG_ 2365479678 SuspensionRemoteCtrl1 4;
BA_ "SPN" SG_ 2365479678 SuspensionRemoteCtrl1 1826;
BA_ "SAEDocument" SG_ 2365479678 SuspensionRemoteCtrl1 "J1939-71";
BA_ "SigType" SG_ 2365479678 LiftAxle2Pos 4;
BA_ "SPN" SG_ 2365479678 LiftAxle2Pos 1822;
BA_ "SAEDocument" SG_ 2365479678 LiftAxle2Pos "J1939-71";
BA_ "SigType" SG_ 2365479678 RearAxleInBumperRange 4;
BA_ "SPN" SG_ 2365479678 RearAxleInBumperRange 1823;
BA_ "SAEDocument" SG_ 2365479678 RearAxleInBumperRange "J1939-71";
BA_ "SigType" SG_ 2365479678 FrontAxleInBumperRange 4;
BA_ "SPN" SG_ 2365479678 FrontAxleInBumperRange 1824;
BA_ "SAEDocument" SG_ 2365479678 FrontAxleInBumperRange "J1939-71";
BA_ "SigType" SG_ 2365479678 LiftAxle1Pos 4;
BA_ "SPN" SG_ 2365479678 LiftAxle1Pos 1743;
BA_ "SAEDocument" SG_ 2365479678 LiftAxle1Pos "J1939-71";
BA_ "SigType" SG_ 2365479678 DoorRelease 5;
BA_ "SPN" SG_ 2365479678 DoorRelease 1744;
BA_ "SAEDocument" SG_ 2365479678 DoorRelease "J1939-71";
BA_ "SigType" SG_ 2365479678 VehicleMotionInhibit 5;
BA_ "SPN" SG_ 2365479678 VehicleMotionInhibit 1745;
BA_ "SAEDocument" SG_ 2365479678 VehicleMotionInhibit "J1939-71";
BA_ "SigType" SG_ 2365479678 SecurityDevice 5;
BA_ "SPN" SG_ 2365479678 SecurityDevice 1746;
BA_ "SAEDocument" SG_ 2365479678 SecurityDevice "J1939-71";
BA_ "SPN" SG_ 2365479678 LevelCtrlMode 1741;
BA_ "SAEDocument" SG_ 2365479678 LevelCtrlMode "J1939-71";
BA_ "SPN" SG_ 2365479678 KneelingInformation 1742;
BA_ "SAEDocument" SG_ 2365479678 KneelingInformation "J1939-71";
BA_ "SigType" SG_ 2365479678 LiftingCtrlModeRearAxle 5;
BA_ "SPN" SG_ 2365479678 LiftingCtrlModeRearAxle 1756;
BA_ "SAEDocument" SG_ 2365479678 LiftingCtrlModeRearAxle "J1939-71";
BA_ "SigType" SG_ 2365479678 LiftingCtrlModeFrontAxle 5;
BA_ "SPN" SG_ 2365479678 LiftingCtrlModeFrontAxle 1739;
BA_ "SAEDocument" SG_ 2365479678 LiftingCtrlModeFrontAxle "J1939-71";
BA_ "SigType" SG_ 2365479678 LoweringCtrlModeRearAxle 5;
BA_ "SPN" SG_ 2365479678 LoweringCtrlModeRearAxle 1755;
BA_ "SAEDocument" SG_ 2365479678 LoweringCtrlModeRearAxle "J1939-71";
BA_ "SigType" SG_ 2365479678 LoweringCtrlModeFrontAxle 5;
BA_ "SPN" SG_ 2365479678 LoweringCtrlModeFrontAxle 1740;
BA_ "SAEDocument" SG_ 2365479678 LoweringCtrlModeFrontAxle "J1939-71";
BA_ "SigType" SG_ 2365479678 AboveNominalLevelRearAxle 4;
BA_ "SPN" SG_ 2365479678 AboveNominalLevelRearAxle 1736;
BA_ "SAEDocument" SG_ 2365479678 AboveNominalLevelRearAxle "J1939-71";
BA_ "SigType" SG_ 2365479678 AboveNominalLevelFrontAxle 4;
BA_ "SPN" SG_ 2365479678 AboveNominalLevelFrontAxle 1737;
BA_ "SAEDocument" SG_ 2365479678 AboveNominalLevelFrontAxle "J1939-71";
BA_ "SigType" SG_ 2365479678 BelowNominalLevelRearAxle 5;
BA_ "SPN" SG_ 2365479678 BelowNominalLevelRearAxle 1754;
BA_ "SAEDocument" SG_ 2365479678 BelowNominalLevelRearAxle "J1939-71";
BA_ "SigType" SG_ 2365479678 BelowNominalLevelFrontAxle 4;
BA_ "SPN" SG_ 2365479678 BelowNominalLevelFrontAxle 1738;
BA_ "SAEDocument" SG_ 2365479678 BelowNominalLevelFrontAxle "J1939-71";
BA_ "SPN" SG_ 2365479678 NominalLevelRearAxle 1733;
BA_ "SAEDocument" SG_ 2365479678 NominalLevelRearAxle "J1939-71";
BA_ "SPN" SG_ 2365479678 NominalLevelFrontAxle 1734;
BA_ "SAEDocument" SG_ 2365479678 NominalLevelFrontAxle "J1939-71";
BA_ "SigType" SG_ 2566837758 Alt4Status 4;
BA_ "SPN" SG_ 2566837758 Alt4Status 3356;
BA_ "SAEDocument" SG_ 2566837758 Alt4Status "J1939-71";
BA_ "SigType" SG_ 2566837758 Alt3Status 4;
BA_ "SPN" SG_ 2566837758 Alt3Status 3355;
BA_ "SAEDocument" SG_ 2566837758 Alt3Status "J1939-71";
BA_ "SigType" SG_ 2566837758 Alt2Status 4;
BA_ "SPN" SG_ 2566837758 Alt2Status 3354;
BA_ "SAEDocument" SG_ 2566837758 Alt2Status "J1939-71";
BA_ "SigType" SG_ 2566837758 Alt1Status 4;
BA_ "SPN" SG_ 2566837758 Alt1Status 3353;
BA_ "SAEDocument" SG_ 2566837758 Alt1Status "J1939-71";
BA_ "SigType" SG_ 2566837758 AltSpeed 1;
BA_ "SPN" SG_ 2566837758 AltSpeed 589;
BA_ "SAEDocument" SG_ 2566837758 AltSpeed "J1939-71";
BA_ "SigType" SG_ 2633922558 AuxAbsPressReading 1;
BA_ "SPN" SG_ 2633922558 AuxAbsPressReading 138;
BA_ "SAEDocument" SG_ 2633922558 AuxAbsPressReading "J1939-71";
BA_ "SigType" SG_ 2633922558 AuxGagePressReading1 1;
BA_ "SPN" SG_ 2633922558 AuxGagePressReading1 137;
BA_ "SAEDocument" SG_ 2633922558 AuxGagePressReading1 "J1939-71";
BA_ "SigType" SG_ 2633922558 AuxVacuumPressReading 1;
BA_ "SPN" SG_ 2633922558 AuxVacuumPressReading 136;
BA_ "SAEDocument" SG_ 2633922558 AuxVacuumPressReading "J1939-71";
BA_ "SigType" SG_ 2566775038 SpecificHumidity 1;
BA_ "SPN" SG_ 2566775038 SpecificHumidity 4490;
BA_ "SAEDocument" SG_ 2566775038 SpecificHumidity "J1939-71";
BA_ "SPN" SG_ 2566775038 SolarSensorMax 2611;
BA_ "SAEDocument" SG_ 2566775038 SolarSensorMax "J1939-71";
BA_ "SigType" SG_ 2566775038 SolarIntensityPercent 1;
BA_ "SPN" SG_ 2566775038 SolarIntensityPercent 2610;
BA_ "SAEDocument" SG_ 2566775038 SolarIntensityPercent "J1939-71";
BA_ "SigType" SG_ 2566836478 TestLimitMinimum 1;
BA_ "SPN" SG_ 2566836478 TestLimitMinimum 1228;
BA_ "SAEDocument" SG_ 2566836478 TestLimitMinimum "J1939-73";
BA_ "SigType" SG_ 2566836478 TestLimitMaximum 1;
BA_ "SPN" SG_ 2566836478 TestLimitMaximum 1227;
BA_ "SAEDocument" SG_ 2566836478 TestLimitMaximum "J1939-73";
BA_ "SigType" SG_ 2566836478 TestValue 1;
BA_ "SPN" SG_ 2566836478 TestValue 1226;
BA_ "SAEDocument" SG_ 2566836478 TestValue "J1939-73";
BA_ "SigType" SG_ 2566836478 TestType 1;
BA_ "GenSigStartValue" SG_ 2566836478 TestType 1;
BA_ "SPN" SG_ 2566836478 TestType 1225;
BA_ "SAEDocument" SG_ 2566836478 TestType "J1939-73";
BA_ "SigType" SG_ 2566836478 TestIdentifier 1;
BA_ "GenSigStartValue" SG_ 2566836478 TestIdentifier 1;
BA_ "SPN" SG_ 2566836478 TestIdentifier 1224;
BA_ "SAEDocument" SG_ 2566836478 TestIdentifier "J1939-73";
BA_ "SAEDocument" SG_ 2565078782 SPN1High "J1939-73";
BA_ "SPN" SG_ 2565078782 SPN1 1214;
BA_ "SAEDocument" SG_ 2565078782 SPN1 "J1939-73";
BA_ "SigType" SG_ 2565078782 TestIdentifier 1;
BA_ "GenSigStartValue" SG_ 2565078782 TestIdentifier 1;
BA_ "SPN" SG_ 2565078782 TestIdentifier 1224;
BA_ "SAEDocument" SG_ 2565078782 TestIdentifier "J1939-73";
BA_ "SPN" SG_ 2565078782 FailureModeIdentifier1 1215;
BA_ "SAEDocument" SG_ 2565078782 FailureModeIdentifier1 "J1939-73";
BA_ "SigType" SG_ 2566836222 FlashRedStopLamp 4;
BA_ "SPN" SG_ 2566836222 FlashRedStopLamp 3039;
BA_ "SAEDocument" SG_ 2566836222 FlashRedStopLamp "J1939-73";
BA_ "SigType" SG_ 2566836222 FlashProtectLamp 4;
BA_ "SPN" SG_ 2566836222 FlashProtectLamp 3041;
BA_ "SAEDocument" SG_ 2566836222 FlashProtectLamp "J1939-73";
BA_ "SigType" SG_ 2566836222 FlashMalfuncIndicatorLamp 4;
BA_ "SPN" SG_ 2566836222 FlashMalfuncIndicatorLamp 3038;
BA_ "SAEDocument" SG_ 2566836222 FlashMalfuncIndicatorLamp "J1939-73";
BA_ "SigType" SG_ 2566836222 FlashAmberWarningLamp 4;
BA_ "SPN" SG_ 2566836222 FlashAmberWarningLamp 3040;
BA_ "SAEDocument" SG_ 2566836222 FlashAmberWarningLamp "J1939-73";
BA_ "SigType" SG_ 2566836222 MalfunctionIndicatorLampStatus 4;
BA_ "SPN" SG_ 2566836222 MalfunctionIndicatorLampStatus 1213;
BA_ "SAEDocument" SG_ 2566836222 MalfunctionIndicatorLampStatus "J1939-73";
BA_ "SigType" SG_ 2566836222 RedStopLampState 4;
BA_ "SPN" SG_ 2566836222 RedStopLampState 623;
BA_ "SAEDocument" SG_ 2566836222 RedStopLampState "J1939-73";
BA_ "SigType" SG_ 2566836222 AmberWarningLampStatus 4;
BA_ "SPN" SG_ 2566836222 AmberWarningLampStatus 624;
BA_ "SAEDocument" SG_ 2566836222 AmberWarningLampStatus "J1939-73";
BA_ "SigType" SG_ 2566836222 ProtectLampStatus 4;
BA_ "SPN" SG_ 2566836222 ProtectLampStatus 987;
BA_ "SAEDocument" SG_ 2566836222 ProtectLampStatus "J1939-73";
BA_ "SigType" SG_ 2566836222 DTC5 7;
BA_ "SAEDocument" SG_ 2566836222 DTC5 "J1939-73";
BA_ "SigType" SG_ 2566836222 DTC4 7;
BA_ "SAEDocument" SG_ 2566836222 DTC4 "J1939-73";
BA_ "SigType" SG_ 2566836222 DTC3 7;
BA_ "SAEDocument" SG_ 2566836222 DTC3 "J1939-73";
BA_ "SigType" SG_ 2566836222 DTC2 7;
BA_ "SAEDocument" SG_ 2566836222 DTC2 "J1939-73";
BA_ "SigType" SG_ 2566836222 DTC1 7;
BA_ "SAEDocument" SG_ 2566836222 DTC1 "J1939-73";
BA_ "SystemSignalLongSymbol" SG_ 2566835966 NOxConvertingCatalystAdsorberSta "NOxConvertingCatalystAdsorberStatus";
BA_ "SystemSignalLongSymbol" SG_ 2566835966 BoostPressureControlSystemSuppor "BoostPressureControlSystemSupport";
BA_ "SystemSignalLongSymbol" SG_ 2566835966 NOxConvertingCatalystAdsorberSup "NOxConvertingCatalystAdsorberSupport";
BA_ "SAEDocument" SG_ 2566835966 MisfireMonitoringSupport "J1939-73";
BA_ "SigType" SG_ 2566835966 OBDCompliance 1;
BA_ "SPN" SG_ 2566835966 OBDCompliance 1220;
BA_ "SAEDocument" SG_ 2566835966 OBDCompliance "J1939-73";
BA_ "SigType" SG_ 2566835966 PreviouslyActiveTroubleCodes 1;
BA_ "SPN" SG_ 2566835966 PreviouslyActiveTroubleCodes 1219;
BA_ "SAEDocument" SG_ 2566835966 PreviouslyActiveTroubleCodes "J1939-73";
BA_ "SigType" SG_ 2566835966 ActiveTroubleCodes 1;
BA_ "SPN" SG_ 2566835966 ActiveTroubleCodes 1218;
BA_ "SAEDocument" SG_ 2566835966 ActiveTroubleCodes "J1939-73";
BA_ "SAEDocument" SG_ 2566835966 SecondAirSystemMonStatus "J1939-73";
BA_ "SAEDocument" SG_ 2566835966 EvaporativeSystemMonStatus "J1939-73";
BA_ "SAEDocument" SG_ 2566835966 ACSystemRefrigerantMonStatus "J1939-73";
BA_ "SAEDocument" SG_ 2566835966 OxygenSensorHeaterMonStatus "J1939-73";
BA_ "SAEDocument" SG_ 2566835966 OxygenSensorMonStatus "J1939-73";
BA_ "SAEDocument" SG_ 2566835966 EGRSystemMonitoringStatus "J1939-73";
BA_ "SAEDocument" SG_ 2566835966 CatalystMonStatus "J1939-73";
BA_ "SAEDocument" SG_ 2566835966 ColdStartAidSystemMonStatus "J1939-73";
BA_ "SAEDocument" SG_ 2566835966 HeatedCatalystMonStatus "J1939-73";
BA_ "SAEDocument" SG_ 2566835966 CatalystMonSupp "J1939-73";
BA_ "SAEDocument" SG_ 2566835966 ColdStartAidSystemMonSupp "J1939-73";
BA_ "SAEDocument" SG_ 2566835966 HeatedCatalystMonSupp "J1939-73";
BA_ "SAEDocument" SG_ 2566835966 EvaporativeSystemMonSupp "J1939-73";
BA_ "SAEDocument" SG_ 2566835966 SecondAirSystemMonSupp "J1939-73";
BA_ "SAEDocument" SG_ 2566835966 ACSystemRefrigerantMonSupp "J1939-73";
BA_ "SAEDocument" SG_ 2566835966 OxygenSensorMonSupp "J1939-73";
BA_ "SAEDocument" SG_ 2566835966 OxygenSensorHeaterMonSupp "J1939-73";
BA_ "SAEDocument" SG_ 2566835966 EGRSystemMonitoringSupp "J1939-73";
BA_ "SAEDocument" SG_ 2566835966 MisfireMonitoringStatus "J1939-73";
BA_ "SAEDocument" SG_ 2566835966 ComprehensiveCompMonStatus "J1939-73";
BA_ "SAEDocument" SG_ 2566835966 FuelSystemMonitoringStatus "J1939-73";
BA_ "SAEDocument" SG_ 2566835966 ComprehensiveComponentMonSupp "J1939-73";
BA_ "SAEDocument" SG_ 2566835966 FuelSystemMonitoringSupport "J1939-73";
BA_ "SigType" SG_ 2566835710 EngIntakeManifold1Press 1;
BA_ "SPN" SG_ 2566835710 EngIntakeManifold1Press 102;
BA_ "SAEDocument" SG_ 2566835710 EngIntakeManifold1Press "J1939-71";
BA_ "SPN" SG_ 2566835710 FreezeFrameLength 1217;
BA_ "SAEDocument" SG_ 2566835710 FreezeFrameLength "J1939-73";
BA_ "SigType" SG_ 2566835710 EngSpeed 1;
BA_ "SPN" SG_ 2566835710 EngSpeed 190;
BA_ "SAEDocument" SG_ 2566835710 EngSpeed "J1939-71";
BA_ "SPN" SG_ 2566835710 EngTorqueMode 899;
BA_ "SAEDocument" SG_ 2566835710 EngTorqueMode "J1939-71";
BA_ "SigType" SG_ 2566835710 WheelBasedVehicleSpeed 1;
BA_ "SPN" SG_ 2566835710 WheelBasedVehicleSpeed 84;
BA_ "SAEDocument" SG_ 2566835710 WheelBasedVehicleSpeed "J1939-71";
BA_ "SPN" SG_ 2566835710 EngPercentLoadAtCurrentSpeed 92;
BA_ "SAEDocument" SG_ 2566835710 EngPercentLoadAtCurrentSpeed "J1939-71";
BA_ "SigType" SG_ 2566835710 EngCoolantTemp 1;
BA_ "SPN" SG_ 2566835710 EngCoolantTemp 110;
BA_ "SAEDocument" SG_ 2566835710 EngCoolantTemp "J1939-71";
BA_ "SigType" SG_ 2566835710 DTC1 7;
BA_ "SAEDocument" SG_ 2566835710 DTC1 "J1939-73";
BA_ "SPN" SG_ 2566764542 ExpandedFreezeFrameLength 3149;
BA_ "SAEDocument" SG_ 2566764542 ExpandedFreezeFrameLength "J1939-73";
BA_ "SigType" SG_ 2566764542 DTC1 7;
BA_ "SAEDocument" SG_ 2566764542 DTC1 "J1939-73";
BA_ "SAEDocument" SG_ 2566764286 SPNSupported1High "J1939-73";
BA_ "SAEDocument" SG_ 2566764286 SPNSupportTypeSTR3 "J1939-73";
BA_ "SAEDocument" SG_ 2566764286 SPNSupportTypeSTR2 "J1939-73";
BA_ "SAEDocument" SG_ 2566764286 SPNSupportTypeEFF3 "J1939-73";
BA_ "SAEDocument" SG_ 2566764286 SPNSupportTypeEFF2 "J1939-73";
BA_ "SAEDocument" SG_ 2566764286 SPNSupportTypeDS3 "J1939-73";
BA_ "SAEDocument" SG_ 2566764286 SPNSupportTypeDS2 "J1939-73";
BA_ "SAEDocument" SG_ 2566764286 SPNSupported3High "J1939-73";
BA_ "SAEDocument" SG_ 2566764286 SPNSupported2High "J1939-73";
BA_ "SAEDocument" SG_ 2566764286 SPNSupported3 "J1939-73";
BA_ "SAEDocument" SG_ 2566764286 SPNSupported2 "J1939-73";
BA_ "SAEDocument" SG_ 2566764286 SPNDataLength3 "J1939-73";
BA_ "SAEDocument" SG_ 2566764286 SPNSupportTypeSTR1 "J1939-73";
BA_ "SAEDocument" SG_ 2566764286 SPNSupportTypeDS1 "J1939-73";
BA_ "SAEDocument" SG_ 2566764286 SPNSupportTypeEFF1 "J1939-73";
BA_ "SAEDocument" SG_ 2566764286 SPNDataLength2 "J1939-73";
BA_ "SPN" SG_ 2566764286 SPNDataLength1 4103;
BA_ "SAEDocument" SG_ 2566764286 SPNDataLength1 "J1939-73";
BA_ "SPN" SG_ 2566764286 SPNSupported1 3297;
BA_ "SAEDocument" SG_ 2566764286 SPNSupported1 "J1939-73";
BA_ "SigType" SG_ 2566764030 FlashRedStopLamp 4;
BA_ "SPN" SG_ 2566764030 FlashRedStopLamp 3039;
BA_ "SAEDocument" SG_ 2566764030 FlashRedStopLamp "J1939-73";
BA_ "SigType" SG_ 2566764030 FlashProtectLamp 4;
BA_ "SPN" SG_ 2566764030 FlashProtectLamp 3041;
BA_ "SAEDocument" SG_ 2566764030 FlashProtectLamp "J1939-73";
BA_ "SigType" SG_ 2566764030 FlashMalfuncIndicatorLamp 4;
BA_ "SPN" SG_ 2566764030 FlashMalfuncIndicatorLamp 3038;
BA_ "SAEDocument" SG_ 2566764030 FlashMalfuncIndicatorLamp "J1939-73";
BA_ "SigType" SG_ 2566764030 FlashAmberWarningLamp 4;
BA_ "SPN" SG_ 2566764030 FlashAmberWarningLamp 3040;
BA_ "SAEDocument" SG_ 2566764030 FlashAmberWarningLamp "J1939-73";
BA_ "SigType" SG_ 2566764030 MalfunctionIndicatorLampStatus 4;
BA_ "SPN" SG_ 2566764030 MalfunctionIndicatorLampStatus 1213;
BA_ "SAEDocument" SG_ 2566764030 MalfunctionIndicatorLampStatus "J1939-73";
BA_ "SigType" SG_ 2566764030 RedStopLampState 4;
BA_ "SPN" SG_ 2566764030 RedStopLampState 623;
BA_ "SAEDocument" SG_ 2566764030 RedStopLampState "J1939-73";
BA_ "SigType" SG_ 2566764030 AmberWarningLampStatus 4;
BA_ "SPN" SG_ 2566764030 AmberWarningLampStatus 624;
BA_ "SAEDocument" SG_ 2566764030 AmberWarningLampStatus "J1939-73";
BA_ "SigType" SG_ 2566764030 ProtectLampStatus 4;
BA_ "SPN" SG_ 2566764030 ProtectLampStatus 987;
BA_ "SAEDocument" SG_ 2566764030 ProtectLampStatus "J1939-73";
BA_ "SigType" SG_ 2566764030 DTC5 7;
BA_ "SAEDocument" SG_ 2566764030 DTC5 "J1939-73";
BA_ "SigType" SG_ 2566764030 DTC4 7;
BA_ "SAEDocument" SG_ 2566764030 DTC4 "J1939-73";
BA_ "SigType" SG_ 2566764030 DTC3 7;
BA_ "SAEDocument" SG_ 2566764030 DTC3 "J1939-73";
BA_ "SigType" SG_ 2566764030 DTC2 7;
BA_ "SAEDocument" SG_ 2566764030 DTC2 "J1939-73";
BA_ "SigType" SG_ 2566764030 DTC1 7;
BA_ "SAEDocument" SG_ 2566764030 DTC1 "J1939-73";
BA_ "SPN" SG_ 2562981630 IndividualDTCClearControlByte 3034;
BA_ "SAEDocument" SG_ 2562981630 IndividualDTCClearControlByte "J1939-73";
BA_ "SPN" SG_ 2562981630 CtrlByteIndicIndividualDTCClear 3035;
BA_ "SAEDocument" SG_ 2562981630 CtrlByteIndicIndividualDTCClear "J1939-73";
BA_ "SPN" SG_ 2562981630 SPN1 1214;
BA_ "SAEDocument" SG_ 2562981630 SPN1 "J1939-73";
BA_ "SAEDocument" SG_ 2562981630 SPN1High "J1939-73";
BA_ "SPN" SG_ 2562981630 FailureModeIdentifier1 1215;
BA_ "SAEDocument" SG_ 2562981630 FailureModeIdentifier1 "J1939-73";
BA_ "SigType" SG_ 2562850558 TimeSinceDTCsCleared 1;
BA_ "SPN" SG_ 2562850558 TimeSinceDTCsCleared 3296;
BA_ "SAEDocument" SG_ 2562850558 TimeSinceDTCsCleared "J1939-73";
BA_ "SigType" SG_ 2562850558 MinutesRunByEngineMILActivated 1;
BA_ "SPN" SG_ 2562850558 MinutesRunByEngineMILActivated 3295;
BA_ "SAEDocument" SG_ 2562850558 MinutesRunByEngineMILActivated "J1939-73";
BA_ "SigType" SG_ 2562850558 DistanceSinceDTCsCleared 1;
BA_ "SPN" SG_ 2562850558 DistanceSinceDTCsCleared 3294;
BA_ "SAEDocument" SG_ 2562850558 DistanceSinceDTCsCleared "J1939-73";
BA_ "SigType" SG_ 2562850558 DistanceWhileMILisActivated 1;
BA_ "SPN" SG_ 2562850558 DistanceWhileMILisActivated 3069;
BA_ "SAEDocument" SG_ 2562850558 DistanceWhileMILisActivated "J1939-73";
BA_ "SigType" SG_ 2562916094 ApplSysMonitorDenominator 1;
BA_ "SPN" SG_ 2562916094 ApplSysMonitorDenominator 3068;
BA_ "SAEDocument" SG_ 2562916094 ApplSysMonitorDenominator "J1939-73";
BA_ "SigType" SG_ 2562916094 ApplSysMonitorNumerator 1;
BA_ "SPN" SG_ 2562916094 ApplSysMonitorNumerator 3067;
BA_ "SAEDocument" SG_ 2562916094 ApplSysMonitorNumerator "J1939-73";
BA_ "SigType" SG_ 2562916094 SPNofApplSysMonitor 1;
BA_ "SPN" SG_ 2562916094 SPNofApplSysMonitor 3066;
BA_ "SAEDocument" SG_ 2562916094 SPNofApplSysMonitor "J1939-73";
BA_ "SigType" SG_ 2562916094 OBDMonitoringCondEncountered 1;
BA_ "SPN" SG_ 2562916094 OBDMonitoringCondEncountered 3049;
BA_ "SAEDocument" SG_ 2562916094 OBDMonitoringCondEncountered "J1939-73";
BA_ "SigType" SG_ 2562916094 IgnitionCycleCounter 1;
BA_ "SPN" SG_ 2562916094 IgnitionCycleCounter 3048;
BA_ "SAEDocument" SG_ 2562916094 IgnitionCycleCounter "J1939-73";
BA_ "SAEDocument" SG_ 2564030206 CalibrationID4 "J1939-73";
BA_ "SAEDocument" SG_ 2564030206 CalibrationID3 "J1939-73";
BA_ "SAEDocument" SG_ 2564030206 CalibrationID2 "J1939-73";
BA_ "SPN" SG_ 2564030206 CalibrationID1 1635;
BA_ "SAEDocument" SG_ 2564030206 CalibrationID1 "J1939-73";
BA_ "SigType" SG_ 2564030206 CalibrationVerificationNumber 1;
BA_ "SPN" SG_ 2564030206 CalibrationVerificationNumber 1634;
BA_ "SAEDocument" SG_ 2564030206 CalibrationVerificationNumber "J1939-73";
BA_ "SAEDocument" SG_ 2564226814 BootLoadData7 "J1939-73";
BA_ "SAEDocument" SG_ 2564226814 BootLoadData6 "J1939-73";
BA_ "SAEDocument" SG_ 2564226814 BootLoadData5 "J1939-73";
BA_ "SAEDocument" SG_ 2564226814 BootLoadData4 "J1939-73";
BA_ "SAEDocument" SG_ 2564226814 BootLoadData3 "J1939-73";
BA_ "SAEDocument" SG_ 2564226814 BootLoadData2 "J1939-73";
BA_ "SAEDocument" SG_ 2564226814 BootLoadData1 "J1939-73";
BA_ "SAEDocument" SG_ 2564226814 BootLoadData "J1939-73";
BA_ "SAEDocument" SG_ 2564292350 RawBinaryData6 "J1939-73";
BA_ "SAEDocument" SG_ 2564292350 RawBinaryData5 "J1939-73";
BA_ "SAEDocument" SG_ 2564292350 RawBinaryData4 "J1939-73";
BA_ "SAEDocument" SG_ 2564292350 RawBinaryData3 "J1939-73";
BA_ "SAEDocument" SG_ 2564292350 RawBinaryData2 "J1939-73";
BA_ "SAEDocument" SG_ 2564292350 RawBinaryData1 "J1939-73";
BA_ "SAEDocument" SG_ 2564292350 RawBinaryData "J1939-73";
BA_ "SAEDocument" SG_ 2564292350 NumberOfOccurance "J1939-73";
BA_ "SAEDocument" SG_ 2564357886 NumberAllowed "J1939-73";
BA_ "SAEDocument" SG_ 2564357886 Seed "J1939-73";
BA_ "SAEDocument" SG_ 2564357886 EDCP_Extension "J1939-73";
BA_ "SAEDocument" SG_ 2564357886 ErrorIndicator "J1939-73";
BA_ "SAEDocument" SG_ 2564357886 Status "J1939-73";
BA_ "SAEDocument" SG_ 2564357886 NumberAllowedHigh "J1939-73";
BA_ "SPN" SG_ 2564423422 KeyOrUserLevel 1645;
BA_ "SAEDocument" SG_ 2564423422 KeyOrUserLevel "J1939-73";
BA_ "SPN" SG_ 2564423422 PointerExtension 1643;
BA_ "SAEDocument" SG_ 2564423422 PointerExtension "J1939-73";
BA_ "SPN" SG_ 2564423422 Pointer 1644;
BA_ "SAEDocument" SG_ 2564423422 Pointer "J1939-73";
BA_ "SPN" SG_ 2564423422 Command 1642;
BA_ "SAEDocument" SG_ 2564423422 Command "J1939-73";
BA_ "SPN" SG_ 2564423422 PointerType 1641;
BA_ "SAEDocument" SG_ 2564423422 PointerType "J1939-73";
BA_ "SPN" SG_ 2564423422 NumberRequested 1640;
BA_ "SAEDocument" SG_ 2564423422 NumberRequested "J1939-73";
BA_ "SAEDocument" SG_ 2564423422 NumberRequestedHigh "J1939-73";
BA_ "SPN" SG_ 2564816638 HoldSignal 1236;
BA_ "SAEDocument" SG_ 2564816638 HoldSignal "J1939-73";
BA_ "SigType" SG_ 2564816638 J1939Network3 4;
BA_ "SPN" SG_ 2564816638 J1939Network3 1235;
BA_ "SAEDocument" SG_ 2564816638 J1939Network3 "J1939-73";
BA_ "SigType" SG_ 2564816638 J1939Network2 4;
BA_ "SPN" SG_ 2564816638 J1939Network2 1231;
BA_ "SAEDocument" SG_ 2564816638 J1939Network2 "J1939-73";
BA_ "SigType" SG_ 2564816638 ISO9141 4;
BA_ "SPN" SG_ 2564816638 ISO9141 1232;
BA_ "SAEDocument" SG_ 2564816638 ISO9141 "J1939-73";
BA_ "SigType" SG_ 2564816638 SAE_J1850 4;
BA_ "SPN" SG_ 2564816638 SAE_J1850 1233;
BA_ "SAEDocument" SG_ 2564816638 SAE_J1850 "J1939-73";
BA_ "SigType" SG_ 2564816638 ManufacturerSpecificPort 4;
BA_ "SPN" SG_ 2564816638 ManufacturerSpecificPort 1234;
BA_ "SAEDocument" SG_ 2564816638 ManufacturerSpecificPort "J1939-73";
BA_ "SigType" SG_ 2564816638 CurrentDataLink 4;
BA_ "SPN" SG_ 2564816638 CurrentDataLink 1230;
BA_ "SAEDocument" SG_ 2564816638 CurrentDataLink "J1939-73";
BA_ "SigType" SG_ 2564816638 SAE_J1587 4;
BA_ "SPN" SG_ 2564816638 SAE_J1587 608;
BA_ "SAEDocument" SG_ 2564816638 SAE_J1587 "J1939-73";
BA_ "SigType" SG_ 2564816638 SAE_J1922 4;
BA_ "SPN" SG_ 2564816638 SAE_J1922 622;
BA_ "SAEDocument" SG_ 2564816638 SAE_J1922 "J1939-73";
BA_ "SigType" SG_ 2564816638 J1939Network1 4;
BA_ "SPN" SG_ 2564816638 J1939Network1 639;
BA_ "SAEDocument" SG_ 2564816638 J1939Network1 "J1939-73";
BA_ "SPN" SG_ 2564816638 SuspendSignal 2618;
BA_ "SAEDocument" SG_ 2564816638 SuspendSignal "J1939-73";
BA_ "SPN" SG_ 2564816638 SuspendDuration 2619;
BA_ "SAEDocument" SG_ 2564816638 SuspendDuration "J1939-73";
BA_ "SigType" SG_ 2566837502 FlashRedStopLamp 4;
BA_ "SPN" SG_ 2566837502 FlashRedStopLamp 3039;
BA_ "SAEDocument" SG_ 2566837502 FlashRedStopLamp "J1939-73";
BA_ "SigType" SG_ 2566837502 FlashProtectLamp 4;
BA_ "SPN" SG_ 2566837502 FlashProtectLamp 3041;
BA_ "SAEDocument" SG_ 2566837502 FlashProtectLamp "J1939-73";
BA_ "SigType" SG_ 2566837502 MalfunctionIndicatorLampStatus 4;
BA_ "SPN" SG_ 2566837502 MalfunctionIndicatorLampStatus 1213;
BA_ "SAEDocument" SG_ 2566837502 MalfunctionIndicatorLampStatus "J1939-73";
BA_ "SigType" SG_ 2566837502 RedStopLampState 4;
BA_ "SPN" SG_ 2566837502 RedStopLampState 623;
BA_ "SAEDocument" SG_ 2566837502 RedStopLampState "J1939-73";
BA_ "SigType" SG_ 2566837502 AmberWarningLampStatus 4;
BA_ "SPN" SG_ 2566837502 AmberWarningLampStatus 624;
BA_ "SAEDocument" SG_ 2566837502 AmberWarningLampStatus "J1939-73";
BA_ "SigType" SG_ 2566837502 ProtectLampStatus 4;
BA_ "SPN" SG_ 2566837502 ProtectLampStatus 987;
BA_ "SAEDocument" SG_ 2566837502 ProtectLampStatus "J1939-73";
BA_ "SigType" SG_ 2566837502 FlashMalfuncIndicatorLamp 4;
BA_ "SPN" SG_ 2566837502 FlashMalfuncIndicatorLamp 3038;
BA_ "SAEDocument" SG_ 2566837502 FlashMalfuncIndicatorLamp "J1939-73";
BA_ "SigType" SG_ 2566837502 FlashAmberWarningLamp 4;
BA_ "SPN" SG_ 2566837502 FlashAmberWarningLamp 3040;
BA_ "SAEDocument" SG_ 2566837502 FlashAmberWarningLamp "J1939-73";
BA_ "SigType" SG_ 2566837502 DTC5 7;
BA_ "SAEDocument" SG_ 2566837502 DTC5 "J1939-73";
BA_ "SigType" SG_ 2566837502 DTC4 7;
BA_ "SAEDocument" SG_ 2566837502 DTC4 "J1939-73";
BA_ "SigType" SG_ 2566837502 DTC3 7;
BA_ "SAEDocument" SG_ 2566837502 DTC3 "J1939-73";
BA_ "SigType" SG_ 2566837502 DTC2 7;
BA_ "SAEDocument" SG_ 2566837502 DTC2 "J1939-73";
BA_ "SigType" SG_ 2566837502 DTC1 7;
BA_ "SAEDocument" SG_ 2566837502 DTC1 "J1939-73";
BA_ "SigType" SG_ 2566836990 TestIdentifierSupported 1;
BA_ "GenSigStartValue" SG_ 2566836990 TestIdentifierSupported 1;
BA_ "SPN" SG_ 2566836990 TestIdentifierSupported 1229;
BA_ "SAEDocument" SG_ 2566836990 TestIdentifierSupported "J1939-73";
BA_ "SigType" SG_ 2566834942 FlashRedStopLamp 4;
BA_ "SPN" SG_ 2566834942 FlashRedStopLamp 3039;
BA_ "SAEDocument" SG_ 2566834942 FlashRedStopLamp "J1939-73";
BA_ "SigType" SG_ 2566834942 FlashProtectLamp 4;
BA_ "SPN" SG_ 2566834942 FlashProtectLamp 3041;
BA_ "SAEDocument" SG_ 2566834942 FlashProtectLamp "J1939-73";
BA_ "SigType" SG_ 2566834942 FlashMalfuncIndicatorLamp 4;
BA_ "SPN" SG_ 2566834942 FlashMalfuncIndicatorLamp 3038;
BA_ "SAEDocument" SG_ 2566834942 FlashMalfuncIndicatorLamp "J1939-73";
BA_ "SigType" SG_ 2566834942 FlashAmberWarningLamp 4;
BA_ "SPN" SG_ 2566834942 FlashAmberWarningLamp 3040;
BA_ "SAEDocument" SG_ 2566834942 FlashAmberWarningLamp "J1939-73";
BA_ "SigType" SG_ 2566834942 MalfunctionIndicatorLampStatus 4;
BA_ "SPN" SG_ 2566834942 MalfunctionIndicatorLampStatus 1213;
BA_ "SAEDocument" SG_ 2566834942 MalfunctionIndicatorLampStatus "J1939-73";
BA_ "SigType" SG_ 2566834942 AmberWarningLampStatus 4;
BA_ "SPN" SG_ 2566834942 AmberWarningLampStatus 624;
BA_ "SAEDocument" SG_ 2566834942 AmberWarningLampStatus "J1939-73";
BA_ "SigType" SG_ 2566834942 RedStopLampState 4;
BA_ "SPN" SG_ 2566834942 RedStopLampState 623;
BA_ "SAEDocument" SG_ 2566834942 RedStopLampState "J1939-73";
BA_ "SigType" SG_ 2566834942 ProtectLampStatus 4;
BA_ "SPN" SG_ 2566834942 ProtectLampStatus 987;
BA_ "SAEDocument" SG_ 2566834942 ProtectLampStatus "J1939-73";
BA_ "SigType" SG_ 2566780926 UtlityOverallPowerFactorLagging 4;
BA_ "SPN" SG_ 2566780926 UtlityOverallPowerFactorLagging 2522;
BA_ "SAEDocument" SG_ 2566780926 UtlityOverallPowerFactorLagging "J1939-75";
BA_ "SigType" SG_ 2566780926 UtilityOverallPowerFactor 1;
BA_ "SPN" SG_ 2566780926 UtilityOverallPowerFactor 2498;
BA_ "SAEDocument" SG_ 2566780926 UtilityOverallPowerFactor "J1939-75";
BA_ "SigType" SG_ 2566780926 UtilityTotalReactivePower 1;
BA_ "SPN" SG_ 2566780926 UtilityTotalReactivePower 2490;
BA_ "SAEDocument" SG_ 2566780926 UtilityTotalReactivePower "J1939-75";
BA_ "SigType" SG_ 2566781182 UtilityTotalApparentPower 1;
BA_ "SPN" SG_ 2566781182 UtilityTotalApparentPower 2494;
BA_ "SAEDocument" SG_ 2566781182 UtilityTotalApparentPower "J1939-75";
BA_ "SigType" SG_ 2566781182 UtilityTotalRealPower 1;
BA_ "SPN" SG_ 2566781182 UtilityTotalRealPower 2486;
BA_ "SAEDocument" SG_ 2566781182 UtilityTotalRealPower "J1939-75";
BA_ "SigType" SG_ 2566778366 UtilityTotalKWHoursImport 4;
BA_ "SPN" SG_ 2566778366 UtilityTotalKWHoursImport 2503;
BA_ "SAEDocument" SG_ 2566778366 UtilityTotalKWHoursImport "J1939-75";
BA_ "SigType" SG_ 2566778366 UtilityTotalKWHoursExport 4;
BA_ "SPN" SG_ 2566778366 UtilityTotalKWHoursExport 2502;
BA_ "SAEDocument" SG_ 2566778366 UtilityTotalKWHoursExport "J1939-75";
BA_ "SigType" SG_ 2566778622 UtilityPhaseCPowerFactorLagging 4;
BA_ "SPN" SG_ 2566778622 UtilityPhaseCPowerFactorLagging 2525;
BA_ "SAEDocument" SG_ 2566778622 UtilityPhaseCPowerFactorLagging "J1939-75";
BA_ "SigType" SG_ 2566778622 UtilityPhaseCPowerFactor 1;
BA_ "SPN" SG_ 2566778622 UtilityPhaseCPowerFactor 2501;
BA_ "SAEDocument" SG_ 2566778622 UtilityPhaseCPowerFactor "J1939-75";
BA_ "SigType" SG_ 2566778622 UtilityPhaseCReactivePower 1;
BA_ "SPN" SG_ 2566778622 UtilityPhaseCReactivePower 2493;
BA_ "SAEDocument" SG_ 2566778622 UtilityPhaseCReactivePower "J1939-75";
BA_ "SigType" SG_ 2566778878 UtilityPhaseCApparentPower 1;
BA_ "SPN" SG_ 2566778878 UtilityPhaseCApparentPower 2497;
BA_ "SAEDocument" SG_ 2566778878 UtilityPhaseCApparentPower "J1939-75";
BA_ "SigType" SG_ 2566778878 UtilityPhaseCRealPower 1;
BA_ "SPN" SG_ 2566778878 UtilityPhaseCRealPower 2489;
BA_ "SAEDocument" SG_ 2566778878 UtilityPhaseCRealPower "J1939-75";
BA_ "SigType" SG_ 2566779134 UtilityPhaseCACRMSCurrent 1;
BA_ "SPN" SG_ 2566779134 UtilityPhaseCACRMSCurrent 2485;
BA_ "SAEDocument" SG_ 2566779134 UtilityPhaseCACRMSCurrent "J1939-75";
BA_ "SigType" SG_ 2566779134 UtilityPhaseCACFrequency 1;
BA_ "SPN" SG_ 2566779134 UtilityPhaseCACFrequency 2473;
BA_ "SAEDocument" SG_ 2566779134 UtilityPhaseCACFrequency "J1939-75";
BA_ "SigType" SG_ 2566779134 UtltyPhsCLneNeutralACRMSVoltage 1;
BA_ "SPN" SG_ 2566779134 UtltyPhsCLneNeutralACRMSVoltage 2481;
BA_ "SAEDocument" SG_ 2566779134 UtltyPhsCLneNeutralACRMSVoltage "J1939-75";
BA_ "SigType" SG_ 2566779134 UtltyPhseCALineLineACRMSVoltage 1;
BA_ "SPN" SG_ 2566779134 UtltyPhseCALineLineACRMSVoltage 2477;
BA_ "SAEDocument" SG_ 2566779134 UtltyPhseCALineLineACRMSVoltage "J1939-75";
BA_ "SigType" SG_ 2566779390 UtilityPhaseBPowerFactorLagging 4;
BA_ "SPN" SG_ 2566779390 UtilityPhaseBPowerFactorLagging 2524;
BA_ "SAEDocument" SG_ 2566779390 UtilityPhaseBPowerFactorLagging "J1939-75";
BA_ "SigType" SG_ 2566779390 UtilityPhaseBPowerFactor 1;
BA_ "SPN" SG_ 2566779390 UtilityPhaseBPowerFactor 2500;
BA_ "SAEDocument" SG_ 2566779390 UtilityPhaseBPowerFactor "J1939-75";
BA_ "SigType" SG_ 2566779390 UtilityPhaseBReactivePower 1;
BA_ "SPN" SG_ 2566779390 UtilityPhaseBReactivePower 2492;
BA_ "SAEDocument" SG_ 2566779390 UtilityPhaseBReactivePower "J1939-75";
BA_ "SigType" SG_ 2566779646 UtilityPhaseBApparentPower 1;
BA_ "SPN" SG_ 2566779646 UtilityPhaseBApparentPower 2496;
BA_ "SAEDocument" SG_ 2566779646 UtilityPhaseBApparentPower "J1939-75";
BA_ "SigType" SG_ 2566779646 UtilityPhaseBRealPower 1;
BA_ "SPN" SG_ 2566779646 UtilityPhaseBRealPower 2488;
BA_ "SAEDocument" SG_ 2566779646 UtilityPhaseBRealPower "J1939-75";
BA_ "SigType" SG_ 2566779902 UtilityPhaseBACRMSCurrent 1;
BA_ "SPN" SG_ 2566779902 UtilityPhaseBACRMSCurrent 2484;
BA_ "SAEDocument" SG_ 2566779902 UtilityPhaseBACRMSCurrent "J1939-75";
BA_ "SigType" SG_ 2566779902 UtilityPhaseBACFrequency 1;
BA_ "SPN" SG_ 2566779902 UtilityPhaseBACFrequency 2472;
BA_ "SAEDocument" SG_ 2566779902 UtilityPhaseBACFrequency "J1939-75";
BA_ "SigType" SG_ 2566779902 UtltyPhsBLneNeutralACRMSVoltage 1;
BA_ "SPN" SG_ 2566779902 UtltyPhsBLneNeutralACRMSVoltage 2480;
BA_ "SAEDocument" SG_ 2566779902 UtltyPhsBLneNeutralACRMSVoltage "J1939-75";
BA_ "SigType" SG_ 2566779902 UtltyPhseBCLineLineACRMSVoltage 1;
BA_ "SPN" SG_ 2566779902 UtltyPhseBCLineLineACRMSVoltage 2476;
BA_ "SAEDocument" SG_ 2566779902 UtltyPhseBCLineLineACRMSVoltage "J1939-75";
BA_ "SigType" SG_ 2566780158 UtilityPhaseAPowerFactorLagging 4;
BA_ "SPN" SG_ 2566780158 UtilityPhaseAPowerFactorLagging 2523;
BA_ "SAEDocument" SG_ 2566780158 UtilityPhaseAPowerFactorLagging "J1939-75";
BA_ "SigType" SG_ 2566780158 UtilityPhaseAPowerFactor 1;
BA_ "SPN" SG_ 2566780158 UtilityPhaseAPowerFactor 2499;
BA_ "SAEDocument" SG_ 2566780158 UtilityPhaseAPowerFactor "J1939-75";
BA_ "SigType" SG_ 2566780158 UtilityPhaseAReactivePower 1;
BA_ "SPN" SG_ 2566780158 UtilityPhaseAReactivePower 2491;
BA_ "SAEDocument" SG_ 2566780158 UtilityPhaseAReactivePower "J1939-75";
BA_ "SigType" SG_ 2566780414 UtilityPhaseAApparentPower 1;
BA_ "SPN" SG_ 2566780414 UtilityPhaseAApparentPower 2495;
BA_ "SAEDocument" SG_ 2566780414 UtilityPhaseAApparentPower "J1939-75";
BA_ "SigType" SG_ 2566780414 UtilityPhaseARealPower 1;
BA_ "SPN" SG_ 2566780414 UtilityPhaseARealPower 2487;
BA_ "SAEDocument" SG_ 2566780414 UtilityPhaseARealPower "J1939-75";
BA_ "SigType" SG_ 2566780670 UtilityPhaseAACRMSCurrent 1;
BA_ "SPN" SG_ 2566780670 UtilityPhaseAACRMSCurrent 2483;
BA_ "SAEDocument" SG_ 2566780670 UtilityPhaseAACRMSCurrent "J1939-75";
BA_ "SigType" SG_ 2566780670 UtilityPhaseAACFrequency 1;
BA_ "SPN" SG_ 2566780670 UtilityPhaseAACFrequency 2471;
BA_ "SAEDocument" SG_ 2566780670 UtilityPhaseAACFrequency "J1939-75";
BA_ "SigType" SG_ 2566780670 UtltyPhsALneNeutralACRMSVoltage 1;
BA_ "SPN" SG_ 2566780670 UtltyPhsALneNeutralACRMSVoltage 2479;
BA_ "SAEDocument" SG_ 2566780670 UtltyPhsALneNeutralACRMSVoltage "J1939-75";
BA_ "SigType" SG_ 2566780670 UtltyPhseABLineLineACRMSVoltage 1;
BA_ "SPN" SG_ 2566780670 UtltyPhseABLineLineACRMSVoltage 2475;
BA_ "SAEDocument" SG_ 2566780670 UtltyPhseABLineLineACRMSVoltage "J1939-75";
BA_ "SigType" SG_ 2566781438 UtilityAverageACRMSCurrent 1;
BA_ "SPN" SG_ 2566781438 UtilityAverageACRMSCurrent 2482;
BA_ "SAEDocument" SG_ 2566781438 UtilityAverageACRMSCurrent "J1939-75";
BA_ "SigType" SG_ 2566781438 UtilityAverageACFrequency 1;
BA_ "SPN" SG_ 2566781438 UtilityAverageACFrequency 2470;
BA_ "SAEDocument" SG_ 2566781438 UtilityAverageACFrequency "J1939-75";
BA_ "SigType" SG_ 2566781438 UtltyAvrgLneNeutralACRMSVoltage 1;
BA_ "SPN" SG_ 2566781438 UtltyAvrgLneNeutralACRMSVoltage 2478;
BA_ "SAEDocument" SG_ 2566781438 UtltyAvrgLneNeutralACRMSVoltage "J1939-75";
BA_ "SigType" SG_ 2566781438 UtltyAvrageLineLineACRMSVoltage 1;
BA_ "SPN" SG_ 2566781438 UtltyAvrageLineLineACRMSVoltage 2474;
BA_ "SAEDocument" SG_ 2566781438 UtltyAvrageLineLineACRMSVoltage "J1939-75";
BA_ "SigType" SG_ 2566784254 GnrtorOverallPowerFactorLagging 4;
BA_ "SPN" SG_ 2566784254 GnrtorOverallPowerFactorLagging 2518;
BA_ "SAEDocument" SG_ 2566784254 GnrtorOverallPowerFactorLagging "J1939-75";
BA_ "SigType" SG_ 2566784254 GeneratorOverallPowerFactor 1;
BA_ "SPN" SG_ 2566784254 GeneratorOverallPowerFactor 2464;
BA_ "SAEDocument" SG_ 2566784254 GeneratorOverallPowerFactor "J1939-75";
BA_ "SigType" SG_ 2566784254 GeneratorTotalReactivePower 1;
BA_ "SPN" SG_ 2566784254 GeneratorTotalReactivePower 2456;
BA_ "SAEDocument" SG_ 2566784254 GeneratorTotalReactivePower "J1939-75";
BA_ "SigType" SG_ 2566784510 GeneratorTotalApparentPower 1;
BA_ "SPN" SG_ 2566784510 GeneratorTotalApparentPower 2460;
BA_ "SAEDocument" SG_ 2566784510 GeneratorTotalApparentPower "J1939-75";
BA_ "SigType" SG_ 2566784510 GeneratorTotalRealPower 1;
BA_ "SPN" SG_ 2566784510 GeneratorTotalRealPower 2452;
BA_ "SAEDocument" SG_ 2566784510 GeneratorTotalRealPower "J1939-75";
BA_ "SigType" SG_ 2566781694 GeneratorTotalKWHoursImport 4;
BA_ "SPN" SG_ 2566781694 GeneratorTotalKWHoursImport 2469;
BA_ "SAEDocument" SG_ 2566781694 GeneratorTotalKWHoursImport "J1939-75";
BA_ "SigType" SG_ 2566781694 GeneratorTotalKWHoursExport 4;
BA_ "SPN" SG_ 2566781694 GeneratorTotalKWHoursExport 2468;
BA_ "SAEDocument" SG_ 2566781694 GeneratorTotalKWHoursExport "J1939-75";
BA_ "SigType" SG_ 2566781950 GnratorPhaseCPowerFactorLagging 4;
BA_ "SPN" SG_ 2566781950 GnratorPhaseCPowerFactorLagging 2521;
BA_ "SAEDocument" SG_ 2566781950 GnratorPhaseCPowerFactorLagging "J1939-75";
BA_ "SigType" SG_ 2566781950 GeneratorPhaseCPowerFactor 1;
BA_ "SPN" SG_ 2566781950 GeneratorPhaseCPowerFactor 2467;
BA_ "SAEDocument" SG_ 2566781950 GeneratorPhaseCPowerFactor "J1939-75";
BA_ "SigType" SG_ 2566781950 GeneratorPhaseCReactivePower 1;
BA_ "SPN" SG_ 2566781950 GeneratorPhaseCReactivePower 2459;
BA_ "SAEDocument" SG_ 2566781950 GeneratorPhaseCReactivePower "J1939-75";
BA_ "SigType" SG_ 2566782206 GeneratorPhaseCApparentPower 1;
BA_ "SPN" SG_ 2566782206 GeneratorPhaseCApparentPower 2463;
BA_ "SAEDocument" SG_ 2566782206 GeneratorPhaseCApparentPower "J1939-75";
BA_ "SigType" SG_ 2566782206 GeneratorPhaseCRealPower 1;
BA_ "SPN" SG_ 2566782206 GeneratorPhaseCRealPower 2455;
BA_ "SAEDocument" SG_ 2566782206 GeneratorPhaseCRealPower "J1939-75";
BA_ "SigType" SG_ 2566782462 GeneratorPhaseCACRMSCurrent 1;
BA_ "SPN" SG_ 2566782462 GeneratorPhaseCACRMSCurrent 2451;
BA_ "SAEDocument" SG_ 2566782462 GeneratorPhaseCACRMSCurrent "J1939-75";
BA_ "SigType" SG_ 2566782462 GeneratorPhaseCACFrequency 1;
BA_ "SPN" SG_ 2566782462 GeneratorPhaseCACFrequency 2439;
BA_ "SAEDocument" SG_ 2566782462 GeneratorPhaseCACFrequency "J1939-75";
BA_ "SigType" SG_ 2566782462 GnrtrPhsCLneNeutralACRMSVoltage 1;
BA_ "SPN" SG_ 2566782462 GnrtrPhsCLneNeutralACRMSVoltage 2447;
BA_ "SAEDocument" SG_ 2566782462 GnrtrPhsCLneNeutralACRMSVoltage "J1939-75";
BA_ "SigType" SG_ 2566782462 GnrtrPhseCALineLineACRMSVoltage 1;
BA_ "SPN" SG_ 2566782462 GnrtrPhseCALineLineACRMSVoltage 2443;
BA_ "SAEDocument" SG_ 2566782462 GnrtrPhseCALineLineACRMSVoltage "J1939-75";
BA_ "SigType" SG_ 2566782718 GnratorPhaseBPowerFactorLagging 4;
BA_ "SPN" SG_ 2566782718 GnratorPhaseBPowerFactorLagging 2520;
BA_ "SAEDocument" SG_ 2566782718 GnratorPhaseBPowerFactorLagging "J1939-75";
BA_ "SigType" SG_ 2566782718 GeneratorPhaseBPowerFactor 1;
BA_ "SPN" SG_ 2566782718 GeneratorPhaseBPowerFactor 2466;
BA_ "SAEDocument" SG_ 2566782718 GeneratorPhaseBPowerFactor "J1939-75";
BA_ "SigType" SG_ 2566782718 GeneratorPhaseBReactivePower 1;
BA_ "SPN" SG_ 2566782718 GeneratorPhaseBReactivePower 2458;
BA_ "SAEDocument" SG_ 2566782718 GeneratorPhaseBReactivePower "J1939-75";
BA_ "SigType" SG_ 2566782974 GeneratorPhaseBApparentPower 1;
BA_ "SPN" SG_ 2566782974 GeneratorPhaseBApparentPower 2462;
BA_ "SAEDocument" SG_ 2566782974 GeneratorPhaseBApparentPower "J1939-75";
BA_ "SigType" SG_ 2566782974 GeneratorPhaseBRealPower 1;
BA_ "SPN" SG_ 2566782974 GeneratorPhaseBRealPower 2454;
BA_ "SAEDocument" SG_ 2566782974 GeneratorPhaseBRealPower "J1939-75";
BA_ "SigType" SG_ 2566783230 GeneratorPhaseBACRMSCurrent 1;
BA_ "SPN" SG_ 2566783230 GeneratorPhaseBACRMSCurrent 2450;
BA_ "SAEDocument" SG_ 2566783230 GeneratorPhaseBACRMSCurrent "J1939-75";
BA_ "SigType" SG_ 2566783230 GeneratorPhaseBACFrequency 1;
BA_ "SPN" SG_ 2566783230 GeneratorPhaseBACFrequency 2438;
BA_ "SAEDocument" SG_ 2566783230 GeneratorPhaseBACFrequency "J1939-75";
BA_ "SigType" SG_ 2566783230 GnrtrPhsBLneNeutralACRMSVoltage 1;
BA_ "SPN" SG_ 2566783230 GnrtrPhsBLneNeutralACRMSVoltage 2446;
BA_ "SAEDocument" SG_ 2566783230 GnrtrPhsBLneNeutralACRMSVoltage "J1939-75";
BA_ "SigType" SG_ 2566783230 GnrtrPhseBCLineLineACRMSVoltage 1;
BA_ "SPN" SG_ 2566783230 GnrtrPhseBCLineLineACRMSVoltage 2442;
BA_ "SAEDocument" SG_ 2566783230 GnrtrPhseBCLineLineACRMSVoltage "J1939-75";
BA_ "SigType" SG_ 2566783486 GnratorPhaseAPowerFactorLagging 4;
BA_ "SPN" SG_ 2566783486 GnratorPhaseAPowerFactorLagging 2519;
BA_ "SAEDocument" SG_ 2566783486 GnratorPhaseAPowerFactorLagging "J1939-75";
BA_ "SigType" SG_ 2566783486 GeneratorPhaseAPowerFactor 1;
BA_ "SPN" SG_ 2566783486 GeneratorPhaseAPowerFactor 2465;
BA_ "SAEDocument" SG_ 2566783486 GeneratorPhaseAPowerFactor "J1939-75";
BA_ "SigType" SG_ 2566783486 GeneratorPhaseAReactivePower 1;
BA_ "SPN" SG_ 2566783486 GeneratorPhaseAReactivePower 2457;
BA_ "SAEDocument" SG_ 2566783486 GeneratorPhaseAReactivePower "J1939-75";
BA_ "SigType" SG_ 2566783742 GeneratorPhaseAApparentPower 1;
BA_ "SPN" SG_ 2566783742 GeneratorPhaseAApparentPower 2461;
BA_ "SAEDocument" SG_ 2566783742 GeneratorPhaseAApparentPower "J1939-75";
BA_ "SigType" SG_ 2566783742 GeneratorPhaseARealPower 1;
BA_ "SPN" SG_ 2566783742 GeneratorPhaseARealPower 2453;
BA_ "SAEDocument" SG_ 2566783742 GeneratorPhaseARealPower "J1939-75";
BA_ "SigType" SG_ 2566783998 GeneratorPhaseAACRMSCurrent 1;
BA_ "SPN" SG_ 2566783998 GeneratorPhaseAACRMSCurrent 2449;
BA_ "SAEDocument" SG_ 2566783998 GeneratorPhaseAACRMSCurrent "J1939-75";
BA_ "SigType" SG_ 2566783998 GeneratorPhaseAACFrequency 1;
BA_ "SPN" SG_ 2566783998 GeneratorPhaseAACFrequency 2437;
BA_ "SAEDocument" SG_ 2566783998 GeneratorPhaseAACFrequency "J1939-75";
BA_ "SigType" SG_ 2566783998 GnrtrPhsALneNeutralACRMSVoltage 1;
BA_ "SPN" SG_ 2566783998 GnrtrPhsALneNeutralACRMSVoltage 2445;
BA_ "SAEDocument" SG_ 2566783998 GnrtrPhsALneNeutralACRMSVoltage "J1939-75";
BA_ "SigType" SG_ 2566783998 GnrtrPhseABLineLineACRMSVoltage 1;
BA_ "SPN" SG_ 2566783998 GnrtrPhseABLineLineACRMSVoltage 2441;
BA_ "SAEDocument" SG_ 2566783998 GnrtrPhseABLineLineACRMSVoltage "J1939-75";
BA_ "SigType" SG_ 2566784766 GeneratorAverageACRMSCurrent 1;
BA_ "SPN" SG_ 2566784766 GeneratorAverageACRMSCurrent 2448;
BA_ "SAEDocument" SG_ 2566784766 GeneratorAverageACRMSCurrent "J1939-75";
BA_ "SigType" SG_ 2566784766 GeneratorAverageACFrequency 1;
BA_ "SPN" SG_ 2566784766 GeneratorAverageACFrequency 2436;
BA_ "SAEDocument" SG_ 2566784766 GeneratorAverageACFrequency "J1939-75";
BA_ "SigType" SG_ 2566784766 GnrtrAvrgLneNeutralACRMSVoltage 1;
BA_ "SPN" SG_ 2566784766 GnrtrAvrgLneNeutralACRMSVoltage 2444;
BA_ "SAEDocument" SG_ 2566784766 GnrtrAvrgLneNeutralACRMSVoltage "J1939-75";
BA_ "SigType" SG_ 2566784766 GnrtrAvrageLineLineACRMSVoltage 1;
BA_ "SPN" SG_ 2566784766 GnrtrAvrageLineLineACRMSVoltage 2440;
BA_ "SAEDocument" SG_ 2566784766 GnrtrAvrageLineLineACRMSVoltage "J1939-75";
BA_ "SigType" SG_ 2566776830 Bus1_UtilityACPhaseDifference 1;
BA_ "SPN" SG_ 2566776830 Bus1_UtilityACPhaseDifference 2517;
BA_ "SAEDocument" SG_ 2566776830 Bus1_UtilityACPhaseDifference "J1939-75";
BA_ "SigType" SG_ 2566776830 Bus1_UtilityInSync 4;
BA_ "SPN" SG_ 2566776830 Bus1_UtilityInSync 2534;
BA_ "SAEDocument" SG_ 2566776830 Bus1_UtilityInSync "J1939-75";
BA_ "SigType" SG_ 2566776830 Bus1_UtilityVoltageMatch 4;
BA_ "SPN" SG_ 2566776830 Bus1_UtilityVoltageMatch 2532;
BA_ "SAEDocument" SG_ 2566776830 Bus1_UtilityVoltageMatch "J1939-75";
BA_ "SigType" SG_ 2566776830 Bus1_UtilityFrequencyMatch 4;
BA_ "SPN" SG_ 2566776830 Bus1_UtilityFrequencyMatch 2533;
BA_ "SAEDocument" SG_ 2566776830 Bus1_UtilityFrequencyMatch "J1939-75";
BA_ "SigType" SG_ 2566776830 Bus1_UtilityPhaseMatch 4;
BA_ "SPN" SG_ 2566776830 Bus1_UtilityPhaseMatch 2531;
BA_ "SAEDocument" SG_ 2566776830 Bus1_UtilityPhaseMatch "J1939-75";
BA_ "SigType" SG_ 2566776830 Bus1_UtilityDeadBus 4;
BA_ "SPN" SG_ 2566776830 Bus1_UtilityDeadBus 2535;
BA_ "SAEDocument" SG_ 2566776830 Bus1_UtilityDeadBus "J1939-75";
BA_ "SigType" SG_ 2566777342 Bus1PhaseCACFrequency 1;
BA_ "SPN" SG_ 2566777342 Bus1PhaseCACFrequency 2507;
BA_ "SAEDocument" SG_ 2566777342 Bus1PhaseCACFrequency "J1939-75";
BA_ "SigType" SG_ 2566777342 Bs1PhseCLineNeutralACRMSVoltage 1;
BA_ "SPN" SG_ 2566777342 Bs1PhseCLineNeutralACRMSVoltage 2515;
BA_ "SAEDocument" SG_ 2566777342 Bs1PhseCLineNeutralACRMSVoltage "J1939-75";
BA_ "SigType" SG_ 2566777342 Bus1PhaseCALineLineACRMSVoltage 1;
BA_ "SPN" SG_ 2566777342 Bus1PhaseCALineLineACRMSVoltage 2511;
BA_ "SAEDocument" SG_ 2566777342 Bus1PhaseCALineLineACRMSVoltage "J1939-75";
BA_ "SigType" SG_ 2566777598 Bus1PhaseBACFrequency 1;
BA_ "SPN" SG_ 2566777598 Bus1PhaseBACFrequency 2506;
BA_ "SAEDocument" SG_ 2566777598 Bus1PhaseBACFrequency "J1939-75";
BA_ "SigType" SG_ 2566777598 Bs1PhseBLineNeutralACRMSVoltage 1;
BA_ "SPN" SG_ 2566777598 Bs1PhseBLineNeutralACRMSVoltage 2514;
BA_ "SAEDocument" SG_ 2566777598 Bs1PhseBLineNeutralACRMSVoltage "J1939-75";
BA_ "SigType" SG_ 2566777598 Bus1PhaseBCLineLineACRMSVoltage 1;
BA_ "SPN" SG_ 2566777598 Bus1PhaseBCLineLineACRMSVoltage 2510;
BA_ "SAEDocument" SG_ 2566777598 Bus1PhaseBCLineLineACRMSVoltage "J1939-75";
BA_ "SigType" SG_ 2566777854 Bus1PhaseAACFrequency 1;
BA_ "SPN" SG_ 2566777854 Bus1PhaseAACFrequency 2505;
BA_ "SAEDocument" SG_ 2566777854 Bus1PhaseAACFrequency "J1939-75";
BA_ "SigType" SG_ 2566777854 Bs1PhseALineNeutralACRMSVoltage 1;
BA_ "SPN" SG_ 2566777854 Bs1PhseALineNeutralACRMSVoltage 2513;
BA_ "SAEDocument" SG_ 2566777854 Bs1PhseALineNeutralACRMSVoltage "J1939-75";
BA_ "SigType" SG_ 2566777854 Bus1PhaseABLineLineACRMSVoltage 1;
BA_ "SPN" SG_ 2566777854 Bus1PhaseABLineLineACRMSVoltage 2509;
BA_ "SAEDocument" SG_ 2566777854 Bus1PhaseABLineLineACRMSVoltage "J1939-75";
BA_ "SigType" SG_ 2566777086 Bus1_GeneratorACPhaseDifference 1;
BA_ "SPN" SG_ 2566777086 Bus1_GeneratorACPhaseDifference 2516;
BA_ "SAEDocument" SG_ 2566777086 Bus1_GeneratorACPhaseDifference "J1939-75";
BA_ "SigType" SG_ 2566777086 Bus1_GeneratorInSync 4;
BA_ "SPN" SG_ 2566777086 Bus1_GeneratorInSync 2529;
BA_ "SAEDocument" SG_ 2566777086 Bus1_GeneratorInSync "J1939-75";
BA_ "SigType" SG_ 2566777086 Bus1_GeneratorVoltageMatch 4;
BA_ "SPN" SG_ 2566777086 Bus1_GeneratorVoltageMatch 2527;
BA_ "SAEDocument" SG_ 2566777086 Bus1_GeneratorVoltageMatch "J1939-75";
BA_ "SigType" SG_ 2566777086 Bus1_GeneratorFrequencyMatch 4;
BA_ "SPN" SG_ 2566777086 Bus1_GeneratorFrequencyMatch 2528;
BA_ "SAEDocument" SG_ 2566777086 Bus1_GeneratorFrequencyMatch "J1939-75";
BA_ "SigType" SG_ 2566777086 Bus1_GeneratorPhaseMatch 4;
BA_ "SPN" SG_ 2566777086 Bus1_GeneratorPhaseMatch 2526;
BA_ "SAEDocument" SG_ 2566777086 Bus1_GeneratorPhaseMatch "J1939-75";
BA_ "SigType" SG_ 2566777086 Bus1_GeneratorDeadBus 4;
BA_ "SPN" SG_ 2566777086 Bus1_GeneratorDeadBus 2530;
BA_ "SAEDocument" SG_ 2566777086 Bus1_GeneratorDeadBus "J1939-75";
BA_ "SigType" SG_ 2566778110 Bus1AverageACFrequency 1;
BA_ "SPN" SG_ 2566778110 Bus1AverageACFrequency 2504;
BA_ "SAEDocument" SG_ 2566778110 Bus1AverageACFrequency "J1939-75";
BA_ "SigType" SG_ 2566778110 Bs1AvrgeLineNeutralACRMSVoltage 1;
BA_ "SPN" SG_ 2566778110 Bs1AvrgeLineNeutralACRMSVoltage 2512;
BA_ "SAEDocument" SG_ 2566778110 Bs1AvrgeLineNeutralACRMSVoltage "J1939-75";
BA_ "SigType" SG_ 2566778110 Bus1AverageLineLineACRMSVoltage 1;
BA_ "SPN" SG_ 2566778110 Bus1AverageLineLineACRMSVoltage 2508;
BA_ "SAEDocument" SG_ 2566778110 Bus1AverageLineLineACRMSVoltage "J1939-75";
BA_ "SigType" SG_ 2633895422 NumberOfMembers 3;
BA_ "SigType" SG_ 2566838526 AddressAssignment 1;
BA_ "SPN" SG_ 2566838526 AddressAssignment 2847;
BA_ "SAEDocument" SG_ 2566838526 AddressAssignment "J1939-81";
BA_ "SPN" SG_ 2566838526 ArbitraryAddressCapable 2844;
BA_ "SAEDocument" SG_ 2566838526 ArbitraryAddressCapable "J1939-81";
BA_ "SPN" SG_ 2566838526 IndustryGroup 2846;
BA_ "SAEDocument" SG_ 2566838526 IndustryGroup "NMEA2000";
BA_ "SPN" SG_ 2566838526 VehicleSystemInstance 2843;
BA_ "SAEDocument" SG_ 2566838526 VehicleSystemInstance "J1939-81";
BA_ "SPN" SG_ 2566838526 Function 2841;
BA_ "SAEDocument" SG_ 2566838526 Function "J1939-81";
BA_ "SAEDocument" SG_ 2566838526 VehicleSystem "J1939-81";
BA_ "SPN" SG_ 2566838526 FunctionInstance 2839;
BA_ "SAEDocument" SG_ 2566838526 FunctionInstance "J1939-81";
BA_ "SPN" SG_ 2566838526 ECUInstance 2840;
BA_ "SAEDocument" SG_ 2566838526 ECUInstance "J1939-81";
BA_ "SigType" SG_ 2566838526 ManufacturerCode 1;
BA_ "SPN" SG_ 2566838526 ManufacturerCode 2838;
BA_ "SAEDocument" SG_ 2566838526 ManufacturerCode "NMEA2000";
BA_ "SPN" SG_ 2566838526 IdentityNumber 2837;
BA_ "SAEDocument" SG_ 2566838526 IdentityNumber "J1939-81";
BA_ "SAEDocument" SG_ 2566838526 VehicleSystem5 "J1939-81";
BA_ "SAEDocument" SG_ 2566838526 VehicleSystem4 "J1939-81";
BA_ "SAEDocument" SG_ 2566838526 VehicleSystem3 "J1939-81";
BA_ "SAEDocument" SG_ 2566838526 VehicleSystem2 "J1939-81";
BA_ "SAEDocument" SG_ 2566838526 VehicleSystem1 "J1939-81";
BA_ "SPN" SG_ 2565799678 ArbitraryAddressCapable 2844;
BA_ "SAEDocument" SG_ 2565799678 ArbitraryAddressCapable "J1939-81";
BA_ "SPN" SG_ 2565799678 IndustryGroup 2846;
BA_ "SAEDocument" SG_ 2565799678 IndustryGroup "NMEA2000";
BA_ "SPN" SG_ 2565799678 VehicleSystemInstance 2843;
BA_ "SAEDocument" SG_ 2565799678 VehicleSystemInstance "J1939-81";
BA_ "SPN" SG_ 2565799678 Function 2841;
BA_ "SAEDocument" SG_ 2565799678 Function "J1939-81";
BA_ "SPN" SG_ 2565799678 FunctionInstance 2839;
BA_ "SAEDocument" SG_ 2565799678 FunctionInstance "J1939-81";
BA_ "SPN" SG_ 2565799678 ECUInstance 2840;
BA_ "SAEDocument" SG_ 2565799678 ECUInstance "J1939-81";
BA_ "SigType" SG_ 2565799678 ManufacturerCode 1;
BA_ "SPN" SG_ 2565799678 ManufacturerCode 2838;
BA_ "SAEDocument" SG_ 2565799678 ManufacturerCode "NMEA2000";
BA_ "SPN" SG_ 2565799678 IdentityNumber 2837;
BA_ "SAEDocument" SG_ 2565799678 IdentityNumber "J1939-81";
BA_ "SAEDocument" SG_ 2565799678 VehicleSystem "J1939-81";
BA_ "SAEDocument" SG_ 2565799678 VehicleSystem5 "J1939-81";
BA_ "SAEDocument" SG_ 2565799678 VehicleSystem4 "J1939-81";
BA_ "SAEDocument" SG_ 2565799678 VehicleSystem3 "J1939-81";
BA_ "SAEDocument" SG_ 2565799678 VehicleSystem2 "J1939-81";
BA_ "SAEDocument" SG_ 2565799678 VehicleSystem1 "J1939-81";
BA_ "SigType" SG_ 2563440382 ShrtNameOfActualReportingDevice 4;
BA_ "SPN" SG_ 2563440382 ShrtNameOfActualReportingDevice 2554;
BA_ "SAEDocument" SG_ 2563440382 ShrtNameOfActualReportingDevice "J1939-21";
BA_ "SigType" SG_ 2563440382 LengthOfDataForTheReportedPGN 1;
BA_ "SPN" SG_ 2563440382 LengthOfDataForTheReportedPGN 2553;
BA_ "SAEDocument" SG_ 2563440382 LengthOfDataForTheReportedPGN "J1939-21";
BA_ "SigType" SG_ 2563440382 PGNofRequstedInformation 6;
BA_ "SPN" SG_ 2563440382 PGNofRequstedInformation 2552;
BA_ "SAEDocument" SG_ 2563440382 PGNofRequstedInformation "J1939-21";
BA_ "SigType" SG_ 2632711934 SequenceNumber 1;
BA_ "GenSigStartValue" SG_ 2632711934 SequenceNumber 1;
BA_ "SPN" SG_ 2632711934 SequenceNumber 2572;
BA_ "SAEDocument" SG_ 2632711934 SequenceNumber "J1939-21";
BA_ "SAEDocument" SG_ 2632777470 TotalNumberOfPacketsEoMA "J1939-21";
BA_ "SAEDocument" SG_ 2632777470 TotalMessageSizeEoMA "J1939-21";
BA_ "SAEDocument" SG_ 2632777470 TotalMessageSizeBAM "J1939-21";
BA_ "SAEDocument" SG_ 2632777470 TotalNumberOfPacketsBAM "J1939-21";
BA_ "SPN" SG_ 2632777470 ConnectionAbortReason 2570;
BA_ "SAEDocument" SG_ 2632777470 ConnectionAbortReason "J1939-21";
BA_ "SPN" SG_ 2632777470 NextPacketNumberToBeSent 2562;
BA_ "SAEDocument" SG_ 2632777470 NextPacketNumberToBeSent "J1939-21";
BA_ "SPN" SG_ 2632777470 NumberOfPacketsThatCanBeSent 2561;
BA_ "SAEDocument" SG_ 2632777470 NumberOfPacketsThatCanBeSent "J1939-21";
BA_ "SigType" SG_ 2632777470 PGNumber 6;
BA_ "SPN" SG_ 2632777470 PGNumber 2560;
BA_ "SAEDocument" SG_ 2632777470 PGNumber "J1939-21";
BA_ "SPN" SG_ 2632777470 MaximumNumberOfPackets 2559;
BA_ "SAEDocument" SG_ 2632777470 MaximumNumberOfPackets "J1939-21";
BA_ "SPN" SG_ 2632777470 TotalNumberOfPackets 2558;
BA_ "SAEDocument" SG_ 2632777470 TotalNumberOfPackets "J1939-21";
BA_ "SPN" SG_ 2632777470 TotalMessageSize 2557;
BA_ "SAEDocument" SG_ 2632777470 TotalMessageSize "J1939-21";
BA_ "SPN" SG_ 2632777470 ControlByte 2556;
BA_ "SAEDocument" SG_ 2632777470 ControlByte "J1939-21";
BA_ "SigType" SG_ 2563374846 UseTransferMode 4;
BA_ "SPN" SG_ 2563374846 UseTransferMode 2575;
BA_ "SAEDocument" SG_ 2563374846 UseTransferMode "J1939-21";
BA_ "SigType" SG_ 2563374846 ParameterGroupNumber 6;
BA_ "SPN" SG_ 2563374846 ParameterGroupNumber 2574;
BA_ "SAEDocument" SG_ 2563374846 ParameterGroupNumber "J1939-21";
BA_ "SigType" SG_ 2565537534 ParameterGroupNumber 6;
BA_ "SPN" SG_ 2565537534 ParameterGroupNumber 2574;
BA_ "SAEDocument" SG_ 2565537534 ParameterGroupNumber "J1939-21";
BA_ "SigType" SG_ 2499635966 AxleGroupWeight 1;
BA_ "SPN" SG_ 2499635966 AxleGroupWeight 409;
BA_ "SAEDocument" SG_ 2499635966 AxleGroupWeight "J1939-71";
BA_ "SPN" SG_ 2499635966 AxleGroupLocation 4073;
BA_ "SAEDocument" SG_ 2499635966 AxleGroupLocation "J1939-71";
BA_ "SPN" SG_ 2633853438 AxleGroupLocation 4074;
BA_ "SAEDocument" SG_ 2633853438 AxleGroupLocation "J1939-71";
BA_ "SigType" SG_ 2633853438 AxleGroupFullWeightCalib 1;
BA_ "SPN" SG_ 2633853438 AxleGroupFullWeightCalib 407;
BA_ "SAEDocument" SG_ 2633853438 AxleGroupFullWeightCalib "J1939-71";
BA_ "SigType" SG_ 2633853438 AxleGroupEmptyWeightCalib 1;
BA_ "SPN" SG_ 2633853438 AxleGroupEmptyWeightCalib 408;
BA_ "SAEDocument" SG_ 2633853438 AxleGroupEmptyWeightCalib "J1939-71";
BA_ "SPN" SG_ 2432520702 DsrdAftrclrClntThermostatOpening 4200;
BA_ "SAEDocument" SG_ 2432520702 DsrdAftrclrClntThermostatOpening "J1939-71";
BA_ "SPN" SG_ 2432520702 DsrdAftercoolerCoolantIntakeTemp 4199;
BA_ "SAEDocument" SG_ 2432520702 DsrdAftercoolerCoolantIntakeTemp "J1939-71";
BA_ "SigType" SG_ 2432520702 AftercoolerCoolantThermostatMode 5;
BA_ "SPN" SG_ 2432520702 AftercoolerCoolantThermostatMode 4198;
BA_ "SAEDocument" SG_ 2432520702 AftercoolerCoolantThermostatMode "J1939-71";
BA_ "SigType" SG_ 2566745086 AddtnlTrlrAxlGrupWeightAvailable 5;
BA_ "SPN" SG_ 2566745086 AddtnlTrlrAxlGrupWeightAvailable 4072;
BA_ "SAEDocument" SG_ 2566745086 AddtnlTrlrAxlGrupWeightAvailable "J1939-71";
BA_ "SigType" SG_ 2566745086 TrailerHAxleGroupWeightAvailable 5;
BA_ "SPN" SG_ 2566745086 TrailerHAxleGroupWeightAvailable 4071;
BA_ "SAEDocument" SG_ 2566745086 TrailerHAxleGroupWeightAvailable "J1939-71";
BA_ "SigType" SG_ 2566745086 TrailerGAxleGroupWeightAvailable 5;
BA_ "SPN" SG_ 2566745086 TrailerGAxleGroupWeightAvailable 4070;
BA_ "SAEDocument" SG_ 2566745086 TrailerGAxleGroupWeightAvailable "J1939-71";
BA_ "SigType" SG_ 2566745086 TrailerFAxleGroupWeightAvailable 5;
BA_ "SPN" SG_ 2566745086 TrailerFAxleGroupWeightAvailable 4069;
BA_ "SAEDocument" SG_ 2566745086 TrailerFAxleGroupWeightAvailable "J1939-71";
BA_ "SigType" SG_ 2566745086 TrailerEAxleGroupWeightAvailable 5;
BA_ "SPN" SG_ 2566745086 TrailerEAxleGroupWeightAvailable 4068;
BA_ "SAEDocument" SG_ 2566745086 TrailerEAxleGroupWeightAvailable "J1939-71";
BA_ "SigType" SG_ 2566745086 TrailerDAxleGroupWeightAvailable 5;
BA_ "SPN" SG_ 2566745086 TrailerDAxleGroupWeightAvailable 4067;
BA_ "SAEDocument" SG_ 2566745086 TrailerDAxleGroupWeightAvailable "J1939-71";
BA_ "SigType" SG_ 2566745086 TrailerCAxleGroupWeightAvailable 5;
BA_ "SPN" SG_ 2566745086 TrailerCAxleGroupWeightAvailable 4066;
BA_ "SAEDocument" SG_ 2566745086 TrailerCAxleGroupWeightAvailable "J1939-71";
BA_ "SigType" SG_ 2566745086 TrailerBAxleGroupWeightAvailable 5;
BA_ "SPN" SG_ 2566745086 TrailerBAxleGroupWeightAvailable 4065;
BA_ "SAEDocument" SG_ 2566745086 TrailerBAxleGroupWeightAvailable "J1939-71";
BA_ "SigType" SG_ 2566745086 TrailerAAxleGroupWeightAvailable 5;
BA_ "SPN" SG_ 2566745086 TrailerAAxleGroupWeightAvailable 4064;
BA_ "SAEDocument" SG_ 2566745086 TrailerAAxleGroupWeightAvailable "J1939-71";
BA_ "SigType" SG_ 2566745086 AddtnlTrctrAxlGrpWeightAvailable 5;
BA_ "SPN" SG_ 2566745086 AddtnlTrctrAxlGrpWeightAvailable 4063;
BA_ "SAEDocument" SG_ 2566745086 AddtnlTrctrAxlGrpWeightAvailable "J1939-71";
BA_ "SigType" SG_ 2566745086 TagAxleGroupWeightAvailable 5;
BA_ "SPN" SG_ 2566745086 TagAxleGroupWeightAvailable 4062;
BA_ "SAEDocument" SG_ 2566745086 TagAxleGroupWeightAvailable "J1939-71";
BA_ "SigType" SG_ 2566745086 DriveAxleGroupWeightAvailable 5;
BA_ "SPN" SG_ 2566745086 DriveAxleGroupWeightAvailable 4061;
BA_ "SAEDocument" SG_ 2566745086 DriveAxleGroupWeightAvailable "J1939-71";
BA_ "SigType" SG_ 2566745086 LiftAxleGroupWeightAvailable 5;
BA_ "SPN" SG_ 2566745086 LiftAxleGroupWeightAvailable 4060;
BA_ "SAEDocument" SG_ 2566745086 LiftAxleGroupWeightAvailable "J1939-71";
BA_ "SigType" SG_ 2566745086 SteerAxleGroupWeightAvailable 5;
BA_ "SPN" SG_ 2566745086 SteerAxleGroupWeightAvailable 4059;
BA_ "SAEDocument" SG_ 2566745086 SteerAxleGroupWeightAvailable "J1939-71";
BA_ "SigType" SG_ 2566739198 FlashRedStopLamp 4;
BA_ "SPN" SG_ 2566739198 FlashRedStopLamp 3039;
BA_ "SAEDocument" SG_ 2566739198 FlashRedStopLamp "J1939-73";
BA_ "SigType" SG_ 2566739198 FlashProtectLamp 4;
BA_ "SPN" SG_ 2566739198 FlashProtectLamp 3041;
BA_ "SAEDocument" SG_ 2566739198 FlashProtectLamp "J1939-73";
BA_ "SigType" SG_ 2566739198 FlashMalfuncIndicatorLamp 4;
BA_ "SPN" SG_ 2566739198 FlashMalfuncIndicatorLamp 3038;
BA_ "SAEDocument" SG_ 2566739198 FlashMalfuncIndicatorLamp "J1939-73";
BA_ "SigType" SG_ 2566739198 FlashAmberWarningLamp 4;
BA_ "SPN" SG_ 2566739198 FlashAmberWarningLamp 3040;
BA_ "SAEDocument" SG_ 2566739198 FlashAmberWarningLamp "J1939-73";
BA_ "SigType" SG_ 2566739198 MalfunctionIndicatorLampStatus 4;
BA_ "SPN" SG_ 2566739198 MalfunctionIndicatorLampStatus 1213;
BA_ "SAEDocument" SG_ 2566739198 MalfunctionIndicatorLampStatus "J1939-73";
BA_ "SigType" SG_ 2566739198 AmberWarningLampStatus 4;
BA_ "SPN" SG_ 2566739198 AmberWarningLampStatus 624;
BA_ "SAEDocument" SG_ 2566739198 AmberWarningLampStatus "J1939-73";
BA_ "SigType" SG_ 2566739198 RedStopLampState 4;
BA_ "SPN" SG_ 2566739198 RedStopLampState 623;
BA_ "SAEDocument" SG_ 2566739198 RedStopLampState "J1939-73";
BA_ "SigType" SG_ 2566739198 ProtectLampStatus 4;
BA_ "SPN" SG_ 2566739198 ProtectLampStatus 987;
BA_ "SAEDocument" SG_ 2566739198 ProtectLampStatus "J1939-73";
BA_ "SigType" SG_ 2566739198 DTC5 7;
BA_ "SAEDocument" SG_ 2566739198 DTC5 "J1939-73";
BA_ "SigType" SG_ 2566739198 DTC4 7;
BA_ "SAEDocument" SG_ 2566739198 DTC4 "J1939-73";
BA_ "SigType" SG_ 2566739198 DTC3 7;
BA_ "SAEDocument" SG_ 2566739198 DTC3 "J1939-73";
BA_ "SigType" SG_ 2566739198 DTC2 7;
BA_ "SAEDocument" SG_ 2566739198 DTC2 "J1939-73";
BA_ "SigType" SG_ 2566739198 DTC1 7;
BA_ "SAEDocument" SG_ 2566739198 DTC1 "J1939-73";
VAL_ 2365479678 SuspensionCtrlRefusalInformation 15 "Not available" 14 "Error" 8 "1101 Not defined" 7 "Requested level not available" 6 "General reject Ie no specified reason applies" 5 "Below speed limit" 4 "Above speed limit" 3 "Bogie differential not locked" 2 "Would exceed axle load limit tag axle" 1 "Axle load limit reached load transfer" 0 "Actual request not refused" ;
VAL_ 2365479678 SpeedDependantLevelCtrlStatus 3 "Dont care/take no action" 2 "Reserved" 1 "Active" 0 "Inactive" ;
VAL_ 2365479678 AllwLevelCtrlDuringBrakingStatus 3 "Dont care/take no action" 2 "Reserved" 1 "Activate" 0 "Deactivate" ;
VAL_ 2365479678 SuspensionRemoteCtrl2 3 "Not available" 2 "Error" 1 "Active" 0 "Not active" ;
VAL_ 2365479678 SuspensionRemoteCtrl1 3 "Not available" 2 "Error" 1 "Active" 0 "Not active" ;
VAL_ 2365479678 LiftAxle2Pos 3 "Not available" 2 "Error" 1 "Lift axle position up / tag axle unladen" 0 "Lift axle position down / tag axle laden" ;
VAL_ 2365479678 RearAxleInBumperRange 3 "Not available" 2 "Error" 1 "Actual level within bumper range" 0 "Actual level out of bumper range" ;
VAL_ 2365479678 FrontAxleInBumperRange 3 "Not available" 2 "Error" 1 "Actual level within bumper range" 0 "Actual level out of bumper range" ;
VAL_ 2365479678 LiftAxle1Pos 3 "Not available" 2 "Error" 1 "Lift axle position up / tag axle unladen" 0 "Lift axle position down / tag axle laden" ;
VAL_ 2365479678 DoorRelease 3 "Not available" 2 "Error" 1 "Doors may be opened" 0 "Doors may not be opened" ;
VAL_ 2365479678 VehicleMotionInhibit 3 "Not available" 2 "Error" 1 "Vehicle motion is inhibited" 0 "Vehicle may be moved" ;
VAL_ 2365479678 SecurityDevice 3 "Not available" 2 "Error" 1 "Active" 0 "Not active" ;
VAL_ 2365479678 LevelCtrlMode 10 "Automatic air suspension control prohibited" 15 "Not available" 14 "Error" 9 "Air suspension control prohibited  ie hold current pressures in all suspension devices" 8 "Exhausting bellow function ie the bellows are exhausted totally" 7 "Traction help  load reduce ie the driven axle load is reduced to normal load condition" 6 "Optimum traction 2 ie the pressure at the driven axle is controlled at a fixed value 2" 5 "Optimum traction 1 ie the pressure at the driven axle is controlled at a fixed value 1" 4 "Pressure ratio 2 ie the ratio between the pressures at the driven axle and at the third axle is controlled so that" 3 "Pressure ratio 1 ie the ratio between the pressures at the driven axle and at the third axle is controlled so that" 2 "Load fixing ie the driven axlen is loaded to a value defined by the driver" 1 "Traction help load transfer ie the driven axle is loaded to a maximum value given by legislation or design" 0 "Normal operation ie the system performs a pure control of the vehicle height" ;
VAL_ 2365479678 KneelingInformation 15 "Not available" 14 "Error" 4 "Kneeling abortedie in case of manual actuation the request was dropped before the kneeling level was reached" 3 "Lifting activeie the vehicle is lifted due to a recover request" 2 "Kneeling level reachedie the vehicle is at the fixed kneeling level" 0 "Not activeie the kneeling function is not active" ;
VAL_ 2365479678 LiftingCtrlModeRearAxle 3 "Not available" 2 "Error" 1 "Lifting active" 0 "Lifting not active" ;
VAL_ 2365479678 LiftingCtrlModeFrontAxle 3 "Not available" 2 "Error" 1 "Lifting active" 0 "Lifting not active" ;
VAL_ 2365479678 LoweringCtrlModeRearAxle 3 "Not available" 2 "Error" 1 "Lowering active" 0 "Lowering not active" ;
VAL_ 2365479678 LoweringCtrlModeFrontAxle 3 "Not available" 2 "Error" 1 "Lowering active" 0 "Lowering not active" ;
VAL_ 2365479678 AboveNominalLevelRearAxle 3 "Not available" 2 "Error" 1 "Above" 0 "Not above" ;
VAL_ 2365479678 AboveNominalLevelFrontAxle 3 "Not available" 2 "Error" 1 "Above" 0 "Not above" ;
VAL_ 2365479678 BelowNominalLevelRearAxle 3 "Not available" 2 "Error" 1 "Below" 0 "Not below" ;
VAL_ 2365479678 BelowNominalLevelFrontAxle 3 "Not available" 2 "Error" 1 "Below" 0 "Not below" ;
VAL_ 2365479678 NominalLevelRearAxle 9 "Raising" 10 "Lowering" 15 "Not available" 14 "Error" 8 "Not defined" 7 "Lower Levelie the lowest level to be controlled" 6 "Upper Levelie the highest level to be controlled" 5 "Customer Levelie a level to be defined by customer via parameter setting" 4 "Preset Levelie a level to be defined externally via CAN" 3 "Normal Level 3ie a level permitted for driving for example to lift the vehicle in case of offroad" 2 "Normal Level 2ie a level permitted for driving for example to lower the vehicle in case of high speed" 1 "Normal Level 1ie the level prescribed for normal driving given by design" 0 "Level not specifiedie the nominal level is none of the specified levels no error condition" ;
VAL_ 2365479678 NominalLevelFrontAxle 9 "Raising" 10 "Lowering" 15 "Not available" 14 "Error" 8 "Not defined" 7 "Lower Levelie the lowest level to be controlled" 6 "Upper Levelie the highest level to be controlled" 5 "Customer Levelie a level to be defined by customer via parameter setting" 4 "Preset Levelie a level to be defined externally via CAN" 3 "Normal Level 3ie a level permitted for driving for example to lift the vehicle in case of offroad" 2 "Normal Level 2ie a level permitted for driving for example to lower the vehicle in case of high speed" 1 "Normal Level 1ie the level prescribed for normal driving given by design" 0 "Level not specifiedie the nominal level is none of the specified levels no error condition" ;
VAL_ 2566837758 Alt4Status 3 "not available" 2 "error" 1 "Alternator 4 charging" 0 "Alternator 4 not charging" ;
VAL_ 2566837758 Alt3Status 3 "not available" 2 "error" 1 "Alternator 3 charging" 0 "Alternator 3 not charging" ;
VAL_ 2566837758 Alt2Status 3 "not available" 2 "error" 1 "Alternator 2 charging" 0 "Alternator 2 not charging" ;
VAL_ 2566837758 Alt1Status 3 "not available" 2 "error" 1 "Alternator 1 charging" 0 "Alternator 1 not charging" ;
VAL_ 2566836478 TestIdentifier 250 "Last Measured Scaled Results" 249 "Command Standard Test" 247 "All scaled test results" ;
VAL_ 2565078782 TestIdentifier 250 "Last Measured Scaled Results" 249 "Command Standard Test" 247 "All scaled test results" ;
VAL_ 2565078782 FailureModeIdentifier1 31 "Not available" 19 "Received network data in error" 18 "Below normal (moderately severe)" 17 "Below normal (least severe)" 16 "Above normal (moderately severe)" 15 "Above normal (least severe)" 14 "Special intstructions" 13 "Out of calibration" 12 "Bad intelligent device" 11 "Root cause not known" 10 "Abnormal rate of change" 9 "Abnormal update rate" 8 "Abnormal frequency" 7 "Mechanical system not responding" 6 "Current above normal" 5 "Current below normal" 4 "Voltage below normal" 3 "Voltage above normal" 2 "Data erratic" 1 "Below normal (most severe)" 0 "Above normal (most severe)" ;
VAL_ 2566836222 FlashRedStopLamp 3 "Unavailable / Do Not Flash" 2 "Reserved" 1 "Fast Flash" 0 "Slow Flash" ;
VAL_ 2566836222 FlashProtectLamp 3 "Unavailable / Do Not Flash" 2 "Reserved" 1 "Fast Flash" 0 "Slow Flash" ;
VAL_ 2566836222 FlashMalfuncIndicatorLamp 3 "Unavailable / Do Not Flash" 2 "Reserved" 1 "Fast Flash" 0 "Slow Flash" ;
VAL_ 2566836222 FlashAmberWarningLamp 3 "Unavailable / Do Not Flash" 2 "Reserved" 1 "Fast Flash" 0 "Slow Flash" ;
VAL_ 2566836222 MalfunctionIndicatorLampStatus 3 "Not available" 2 "Reserved" 1 "Lamp on" 0 "Lamp off" ;
VAL_ 2566836222 RedStopLampState 3 "Not available" 2 "Reserved" 1 "Lamp on" 0 "Lamp off" ;
VAL_ 2566836222 AmberWarningLampStatus 3 "Not available" 2 "Reserved" 1 "Lamp on" 0 "Lamp off" ;
VAL_ 2566836222 ProtectLampStatus 3 "Not available" 2 "Reserved" 1 "Lamp on" 0 "Lamp off" ;
VAL_ 2566835966 MisfireMonitoringSupport 3 "Not available" 2 "Reserved" 1 "test supported" 0 "test not supported" ;
VAL_ 2566835966 OBDCompliance 10 "JOBD" 11 "JOBD and OBD II" 12 "JOBD and EOBD" 13 "JOBD, EOBD and OBD II" 14 "Heavy Duty Vehicles (EURO IV) B1" 15 "Heavy Duty Vehicles (EURO V) B2" 16 "Heavy Duty Vehicles (EURO EEC) C" 17 "EMD" 18 "EMD+" 19 "HD OBD P" 20 "HD OBD" 21 "WWH OBD" 22 "OBD II (California, ARB 07/08)" 23 "HD EOBD" 25 "OBD-M (SI-SD/I)" 6 "EOBD" 7 "EOBD and OBD II" 8 "EOBD and OBD" 9 "EOBD, OBD and OBD II" 5 "Not intended to meet OBD II req." 4 "OBD I" 3 "OBD and OBD II" 2 "OBD (Federal, EPA)" 1 "OBD II (California, ARB)" 0 "Reserver for assignment by SAE" ;
VAL_ 2566835966 SecondAirSystemMonStatus 1 "TestNotComplete" 0 "TestComplete" ;
VAL_ 2566835966 EvaporativeSystemMonStatus 1 "TestNotComplete" 0 "TestComplete" ;
VAL_ 2566835966 ACSystemRefrigerantMonStatus 1 "TestNotComplete" 0 "TestComplete" ;
VAL_ 2566835966 OxygenSensorHeaterMonStatus 1 "TestNotComplete" 0 "TestComplete" ;
VAL_ 2566835966 OxygenSensorMonStatus 1 "test not complete" 0 "test complete" ;
VAL_ 2566835966 EGRSystemMonitoringStatus 1 "TestNotComplete" 0 "TestComplete" ;
VAL_ 2566835966 CatalystMonStatus 0 "TestComplete" 1 "TestNotComplete" ;
VAL_ 2566835966 ColdStartAidSystemMonStatus 1 "TestNotComplete" 0 "TestComplete" ;
VAL_ 2566835966 HeatedCatalystMonStatus 1 "TestNotComplete" 0 "TestComplete" ;
VAL_ 2566835966 CatalystMonSupp 1 "TestSupported" 0 "TestNotSupported" ;
VAL_ 2566835966 ColdStartAidSystemMonSupp 1 "TestSupported" 0 "TestNotSupported" ;
VAL_ 2566835966 HeatedCatalystMonSupp 1 "TestSupported" 0 "TestNotSupported" ;
VAL_ 2566835966 EvaporativeSystemMonSupp 1 "TestSupported" 0 "TestNotSupported" ;
VAL_ 2566835966 SecondAirSystemMonSupp 1 "TestSupported" 0 "TestNotSupported" ;
VAL_ 2566835966 ACSystemRefrigerantMonSupp 1 "TestSupported" 0 "TestNotSupported" ;
VAL_ 2566835966 OxygenSensorMonSupp 1 "TestSupported" 0 "TestNotSupported" ;
VAL_ 2566835966 OxygenSensorHeaterMonSupp 1 "TestSupported" 0 "TestNotSupported" ;
VAL_ 2566835966 EGRSystemMonitoringSupp 1 "TestSupported" 0 "TestNotSupported" ;
VAL_ 2566835966 MisfireMonitoringStatus 1 "test not complete" 0 "test complete" ;
VAL_ 2566835966 ComprehensiveCompMonStatus 1 "test not complete" 0 "test complete" ;
VAL_ 2566835966 FuelSystemMonitoringStatus 1 "test not complete" 0 "test complete" ;
VAL_ 2566835966 ComprehensiveComponentMonSupp 3 "Not available" 2 "Reserved" 1 "test supported" 0 "test not supported" ;
VAL_ 2566835966 FuelSystemMonitoringSupport 1 "test supported" 0 "test not supported" ;
VAL_ 2566764286 SPNSupportTypeSTR3 1 "SupportedInScaledTestResults" 0 "NotSupportedInScaledTestResults" ;
VAL_ 2566764286 SPNSupportTypeSTR2 1 "SupportedInScaledTestResults" 0 "NotSupportedInScaledTestResults" ;
VAL_ 2566764286 SPNSupportTypeEFF3 1 "SupportedInExFreezeFrame" 0 "NotSupportedInExFreezeFrame" ;
VAL_ 2566764286 SPNSupportTypeEFF2 1 "SupportedInExFreezeFrame" 0 "NotSupportedInExFreezeFrame" ;
VAL_ 2566764286 SPNSupportTypeDS3 1 "SupportedInDataStream" 0 "NotSupportedInDataStream" ;
VAL_ 2566764286 SPNSupportTypeDS2 1 "SupportedInDataStream" 0 "NotSupportedInDataStream" ;
VAL_ 2566764286 SPNSupportTypeSTR1 1 "SupportedInScaledTestResults" 0 "NotSupportedInScaledTestResults" ;
VAL_ 2566764286 SPNSupportTypeDS1 1 "SupportedInDataStream" 0 "NotSupportedInDataStream" ;
VAL_ 2566764286 SPNSupportTypeEFF1 1 "SupportedInExFreezeFrame" 0 "NotSupportedInExFreezeFrame" ;
VAL_ 2566764030 FlashRedStopLamp 3 "Unavailable / Do Not Flash" 2 "Reserved" 1 "Fast Flash" 0 "Slow Flash" ;
VAL_ 2566764030 FlashProtectLamp 3 "Unavailable / Do Not Flash" 2 "Reserved" 1 "Fast Flash" 0 "Slow Flash" ;
VAL_ 2566764030 FlashMalfuncIndicatorLamp 3 "Unavailable / Do Not Flash" 2 "Reserved" 1 "Fast Flash" 0 "Slow Flash" ;
VAL_ 2566764030 FlashAmberWarningLamp 3 "Unavailable / Do Not Flash" 2 "Reserved" 1 "Fast Flash" 0 "Slow Flash" ;
VAL_ 2566764030 MalfunctionIndicatorLampStatus 3 "Not available" 2 "Reserved" 1 "Lamp on" 0 "Lamp off" ;
VAL_ 2566764030 RedStopLampState 3 "Not available" 2 "Reserved" 1 "Lamp on" 0 "Lamp off" ;
VAL_ 2566764030 AmberWarningLampStatus 3 "Not available" 2 "Reserved" 1 "Lamp on" 0 "Lamp off" ;
VAL_ 2566764030 ProtectLampStatus 3 "Not available" 2 "Reserved" 1 "Lamp on" 0 "Lamp off" ;
VAL_ 2562981630 FailureModeIdentifier1 31 "Not available" 19 "Received network data in error" 18 "Below normal (moderately severe)" 17 "Below normal (least severe)" 16 "Above normal (moderately severe)" 15 "Above normal (least severe)" 14 "Special intstructions" 13 "Out of calibration" 12 "Bad intelligent device" 11 "Root cause not known" 10 "Abnormal rate of change" 9 "Abnormal update rate" 8 "Abnormal frequency" 7 "Mechanical system not responding" 6 "Current above normal" 5 "Current below normal" 4 "Voltage below normal" 3 "Voltage above normal" 2 "Data erratic" 1 "Below normal (most severe)" 0 "Above normal (most severe)" ;
VAL_ 2564357886 Seed 255 "NoFurtherKeyRequiredOfTool" 1 "UseLongSeedOrKeyFromDataSecMsg" 0 "SeedCompleted_BeginSendingKey" ;
VAL_ 2564357886 EDCP_Extension 9 "DataInErrIndAndDataInSeedIsTime" 6 "DataInErrorIndicator" 3 "ConcatenateDataAsLowerEDCParam" 2 "ConcatenateDataAsHigherEDCParam" 0 "Completed" 255 "NoErrIndicator/EDCParamAvailable" ;
VAL_ 2564357886 ErrorIndicator 16777215 "NoErrorIndicatorAvailable" 65540 "TransprtNotComplWithinTimeAllowd" 65539 "TransportNotInitWithinTimeAllowd" 65538 "NoResponseInTheTimeAllowed" 65537 "ModuleExceedingNumberOfRetries" 65536 "AbortFromExtToNormalSoftwareProc" 4103 "VehicleNotInParkOrNotStationary" 4102 "EngineRunning" 4101 "NotInEngineeringOrDevelopmentMode" 4100 "NotInDiagnosticMode" 4099 "InvalidKey" 4098 "InvalidUserLevel" 4097 "InvalidPassword" 4096 "SecurityErrorGeneral" 266 "NameDoesNotConformToExpectdValue" 265 "DataDoesNotConformToValueRanges" 264 "AddrForBootLoadExeInvalidBoundary" 263 "AddrForBootLoadExeOutsideExeMem" 262 "OpReqExeTransfAndEraseOfProgMem" 261 "OpRequiresPriorEraseOfProgramMem" 260 "OpRequiresPriorEraseOfDataMem" 259 "ReqMemoryExceededAvailableMemory" 258 "LengthNotValidForMemStructAndOp" 257 "AddressNotOnValidBoundary" 256 "AddressingOrDataGeneralError" 36 "InternalFailurePreventingReq" 35 "PROMDidNotVerifyOnWrite" 34 "FLASHDidNotVerifyOnWrite" 33 "RAMDidNotVerifyOnWrite" 32 "EDCParaNotCorrectForDataStream" 31 "ProcessUnspecReqFromThisAddress" 23 "ProcessingEDCPGenerationReq" 22 "ProcessingBootLoadReq" 19 "ProcessingStatusReq" 18 "ProcessingWriteReq" 17 "ProcessingReadReq" 16 "ProcessingEraseReq" 2 "ProcessingForSomeoneElse" 1 "ErrorNotIdentified" 0 "NoError" ;
VAL_ 2564357886 Status 1 "NotEnoughMemoryAvailable" 0 "EnoughMemoryAvailable" ;
VAL_ 2564423422 KeyOrUserLevel 65535 "NoKeyAvailable" 0 "UseLongSeedOrKey" ;
VAL_ 2564423422 PointerExtension 0 "SPN_SPACE" ;
VAL_ 2564423422 Command 10 "SetValueAndAcknowledge" 9 "PeerControlAssignment" 0 "TechnicalData" 1 "DeviceDescription" 2 "RequestValue" 3 "ValueCommand" 4 "TimeInterval" 5 "DistanceInterval" 6 "MinWithinThreshold" 7 "MaxWithinThreshold" 8 "ChangeThreshold" 13 "PDACK" 14 "TaskControllerStatus" 15 "WorkingSetTask" ;
VAL_ 2564423422 PointerType 1 "DirectedSpatialAddressing" 0 "DirectMemoryAddressing" ;
VAL_ 2564816638 HoldSignal 15 "Not available" 1 "Devices whose broadcast state ha" 0 "All devices" ;
VAL_ 2564816638 J1939Network3 3 "Don't care" 2 "Reserved" 1 "Start broadcast" 0 "Stop broadcast" ;
VAL_ 2564816638 J1939Network2 3 "Don't care" 2 "Reserved" 1 "Start broadcast" 0 "Stop broadcast" ;
VAL_ 2564816638 ISO9141 3 "Don't care" 2 "Reserved" 1 "Start broadcast" 0 "Stop broadcast" ;
VAL_ 2564816638 SAE_J1850 3 "Don't care" 2 "Reserved" 1 "Start broadcast" 0 "Stop broadcast" ;
VAL_ 2564816638 ManufacturerSpecificPort 3 "Don't care" 2 "Reserved" 1 "Start broadcast" 0 "Stop broadcast" ;
VAL_ 2564816638 CurrentDataLink 3 "Don't care" 2 "Reserved" 1 "Start broadcast" 0 "Stop broadcast" ;
VAL_ 2564816638 SAE_J1587 3 "Don't care" 2 "Reserved" 1 "Start broadcast" 0 "Stop broadcast" ;
VAL_ 2564816638 SAE_J1922 3 "Don't care" 2 "Reserved" 1 "Start broadcast" 0 "Stop broadcast" ;
VAL_ 2564816638 J1939Network1 3 "Don't care" 2 "Reserved" 1 "Start broadcast" 0 "Stop broadcast" ;
VAL_ 2564816638 SuspendSignal 15 "NotAvailable" 14 "ResumingNormalBroadcastPattern" 3 "TemporarySuspensionOfSomeMessages" 2 "TemporarySuspensionOfAllBroadcasts" 1 "IndefiniteSuspensionOfSomeMessages" 0 "IndefiniteSuspensionOfAllBroadcasts" ;
VAL_ 2566837502 FlashRedStopLamp 3 "Unavailable / Do Not Flash" 2 "Reserved" 1 "Fast Flash" 0 "Slow Flash" ;
VAL_ 2566837502 FlashProtectLamp 3 "Unavailable / Do Not Flash" 2 "Reserved" 1 "Fast Flash" 0 "Slow Flash" ;
VAL_ 2566837502 MalfunctionIndicatorLampStatus 3 "Not available" 2 "Reserved" 1 "Lamp on" 0 "Lamp off" ;
VAL_ 2566837502 RedStopLampState 3 "Not available" 2 "Reserved" 1 "Lamp on" 0 "Lamp off" ;
VAL_ 2566837502 AmberWarningLampStatus 3 "Not available" 2 "Reserved" 1 "Lamp on" 0 "Lamp off" ;
VAL_ 2566837502 ProtectLampStatus 3 "Not available" 2 "Reserved" 1 "Lamp on" 0 "Lamp off" ;
VAL_ 2566837502 FlashMalfuncIndicatorLamp 3 "Unavailable / Do Not Flash" 2 "Reserved" 1 "Fast Flash" 0 "Slow Flash" ;
VAL_ 2566837502 FlashAmberWarningLamp 3 "Unavailable / Do Not Flash" 2 "Reserved" 1 "Fast Flash" 0 "Slow Flash" ;
VAL_ 2566834942 Failure_Mode_Indentifier5 31 "Not available" 19 "Received network data in error" 18 "Below normal (moderately severe)" 17 "Below normal (least severe)" 16 "Above normal (moderately severe)" 15 "Above normal (least severe)" 14 "Special intstructions" 13 "Out of calibration" 12 "Bad intelligent device" 11 "Root cause not known" 10 "Abnormal rate of change" 9 "Abnormal update rate" 8 "Abnormal frequency" 7 "Mechanical system not responding" 6 "Current above normal" 5 "Current below normal" 4 "Voltage below normal" 3 "Voltage above normal" 2 "Data erratic" 1 "Below normal (most severe)" 0 "Above normal (most severe)" ;
VAL_ 2566834942 Failure_Mode_Indentifier4 31 "Not available" 19 "Received network data in error" 18 "Below normal (moderately severe)" 17 "Below normal (least severe)" 16 "Above normal (moderately severe)" 15 "Above normal (least severe)" 14 "Special intstructions" 13 "Out of calibration" 12 "Bad intelligent device" 11 "Root cause not known" 10 "Abnormal rate of change" 9 "Abnormal update rate" 8 "Abnormal frequency" 7 "Mechanical system not responding" 6 "Current above normal" 5 "Current below normal" 4 "Voltage below normal" 3 "Voltage above normal" 2 "Data erratic" 1 "Below normal (most severe)" 0 "Above normal (most severe)" ;
VAL_ 2566834942 Failure_Mode_Indentifier3 31 "Not available" 19 "Received network data in error" 18 "Below normal (moderately severe)" 17 "Below normal (least severe)" 16 "Above normal (moderately severe)" 15 "Above normal (least severe)" 14 "Special intstructions" 13 "Out of calibration" 12 "Bad intelligent device" 11 "Root cause not known" 10 "Abnormal rate of change" 9 "Abnormal update rate" 8 "Abnormal frequency" 7 "Mechanical system not responding" 6 "Current above normal" 5 "Current below normal" 4 "Voltage below normal" 3 "Voltage above normal" 2 "Data erratic" 1 "Below normal (most severe)" 0 "Above normal (most severe)" ;
VAL_ 2566834942 Failure_Mode_Indentifier2 31 "Not available" 19 "Received network data in error" 18 "Below normal (moderately severe)" 17 "Below normal (least severe)" 16 "Above normal (moderately severe)" 15 "Above normal (least severe)" 14 "Special intstructions" 13 "Out of calibration" 12 "Bad intelligent device" 11 "Root cause not known" 10 "Abnormal rate of change" 9 "Abnormal update rate" 8 "Abnormal frequency" 7 "Mechanical system not responding" 6 "Current above normal" 5 "Current below normal" 4 "Voltage below normal" 3 "Voltage above normal" 2 "Data erratic" 1 "Below normal (most severe)" 0 "Above normal (most severe)" ;
VAL_ 2566834942 Failure_Mode_Indentifier 31 "Not available" 19 "Received network data in error" 18 "Below normal (moderately severe)" 17 "Below normal (least severe)" 16 "Above normal (moderately severe)" 15 "Above normal (least severe)" 14 "Special intstructions" 13 "Out of calibration" 12 "Bad intelligent device" 11 "Root cause not known" 10 "Abnormal rate of change" 9 "Abnormal update rate" 8 "Abnormal frequency" 7 "Mechanical system not responding" 6 "Current above normal" 5 "Current below normal" 4 "Voltage below normal" 3 "Voltage above normal" 2 "Data erratic" 1 "Below normal (most severe)" 0 "Above normal (most severe)" ;
VAL_ 2566834942 FlashRedStopLamp 3 "Unavailable / Do Not Flash" 2 "Reserved" 1 "Fast Flash" 0 "Slow Flash" ;
VAL_ 2566834942 FlashProtectLamp 3 "Unavailable / Do Not Flash" 2 "Reserved" 1 "Fast Flash" 0 "Slow Flash" ;
VAL_ 2566834942 FlashMalfuncIndicatorLamp 3 "Unavailable / Do Not Flash" 2 "Reserved" 1 "Fast Flash" 0 "Slow Flash" ;
VAL_ 2566834942 FlashAmberWarningLamp 3 "Unavailable / Do Not Flash" 2 "Reserved" 1 "Fast Flash" 0 "Slow Flash" ;
VAL_ 2566834942 MalfunctionIndicatorLampStatus 3 "Not available" 2 "Reserved" 1 "Lamp on" 0 "Lamp off" ;
VAL_ 2566834942 AmberWarningLampStatus 3 "Not available" 2 "Reserved" 1 "Lamp on" 0 "Lamp off" ;
VAL_ 2566834942 RedStopLampState 3 "Not available" 2 "Reserved" 1 "Lamp on" 0 "Lamp off" ;
VAL_ 2566834942 ProtectLampStatus 3 "Not available" 2 "Reserved" 1 "Lamp on" 0 "Lamp off" ;
VAL_ 2566784254 GnrtorOverallPowerFactorLagging 3 "NotAvailable_NotInstalled" 2 "Error" 1 "Lagging" 0 "Leading" ;
VAL_ 2566781950 GnratorPhaseCPowerFactorLagging 3 "NotAvailable_NotInstalled" 2 "Error" 1 "Lagging" 0 "Leading" ;
VAL_ 2566782718 GnratorPhaseBPowerFactorLagging 3 "NotAvailable_NotInstalled" 2 "Error" 1 "Lagging" 0 "Leading" ;
VAL_ 2566783486 GnratorPhaseAPowerFactorLagging 3 "NotAvailable_NotInstalled" 2 "Error" 1 "Lagging" 0 "Leading" ;
VAL_ 2566776830 Bus1_UtilityInSync 3 "NotAvailable" 2 "Error" 1 "Sycnchronized" 0 "NotSynchronized" ;
VAL_ 2566776830 Bus1_UtilityVoltageMatch 3 "NotAvailable" 2 "Error" 1 "VoltagesMatch" 0 "VolatagesDoNotMatch" ;
VAL_ 2566776830 Bus1_UtilityFrequencyMatch 3 "NotAvailable" 2 "Error" 1 "FrequenciesMatch" 0 "FrequenciesDoNotMatch" ;
VAL_ 2566776830 Bus1_UtilityPhaseMatch 3 "NotAvailable" 2 "Error" 1 "PhasesMatch" 0 "PhasesDoNotMatch" ;
VAL_ 2566776830 Bus1_UtilityDeadBus 3 "NotAvailable" 2 "Error" 1 "BusIsDead" 0 "BusIsNotDead" ;
VAL_ 2566777086 Bus1_GeneratorInSync 3 "NotAvailable" 2 "Error" 1 "Sycnchronized" 0 "NotSynchronized" ;
VAL_ 2566777086 Bus1_GeneratorVoltageMatch 3 "NotAvailable" 2 "Error" 1 "VoltagesMatch" 0 "VolatagesDoNotMatch" ;
VAL_ 2566777086 Bus1_GeneratorFrequencyMatch 3 "NotAvailable" 2 "Error" 1 "FrequenciesMatch" 0 "FrequenciesDoNotMatch" ;
VAL_ 2566777086 Bus1_GeneratorPhaseMatch 3 "NotAvailable" 2 "Error" 1 "PhasesMatch" 0 "PhasesDoNotMatch" ;
VAL_ 2566777086 Bus1_GeneratorDeadBus 3 "NotAvailable" 2 "Error" 1 "BusIsDead" 0 "BusIsNotDead" ;
VAL_ 2566838526 IndustryGroup 6 "Reserved for SAE" 7 "Reserved for SAE" 5 "IndustrialProcessCtrlStationary" 4 "Marine" 3 "Construction" 2 "Agricultural and Forestry" 1 "On-Highway" 0 "Global" ;
VAL_ 2566838526 Function 127 "Reserved" 126 "Reserved" 125 "Reserved" 124 "Reserved" 123 "Reserved" 122 "Reserved" 121 "Reserved" 120 "Reserved" 119 "Reserved" 118 "Reserved" 117 "Reserved" 116 "Reserved" 115 "Reserved" 114 "Reserved" 113 "Reserved" 112 "Reserved" 111 "Reserved" 110 "Reserved" 109 "Reserved" 108 "Reserved" 107 "Reserved" 106 "Reserved" 105 "Reserved" 104 "Reserved" 103 "Reserved" 102 "Reserved" 101 "Reserved" 42 "Water Pump Control" 41 "Lighting - Operator Controls" 40 "Seat Control" 39 "Ignition Control Module" 38 "Tire Pressure Control" 37 "Cab Controller" 36 "Pneumatic - System Controller" 35 "Suspension - System Controller" 34 "Hydraulic Pump Controller" 33 "System Monitor" 32 "Headway Controller" 31 "Propulsion Battery Charger" 30 "Management Computer" 29 "Virtual Terminal (in cab)" 28 "Off Vehicle Gateway" 27 "Power TakeOff (Secondary or Front)" 26 "Body Controller" 25 "Network Interconnect ECU" 24 "Vehicle Security" 23 "Vehicle Navigation" 22 "Aerodynamic Control" 21 "Cab Climate Control" 20 "Trip Recorder" 19 "Instrument Cluster" 18 "Suspension - Drive Axle" 17 "Suspension - Steer Axle" 16 "Steering Controller" 15 "Fuel System" 14 "Cruise Control" 13 "Retarder - Driveline" 12 "Retarder - Engine" 11 "Brakes - Drive Axle" 10 "Brakes - Steer Axle" 9 "Brakes - System Controller" 8 "Axle - Drive" 7 "Axle - Steering" 6 "Power TakeOff - (Main or Rear)" 5 "Shift Control/Console" 4 "Battery Pack Monitor" 3 "Transmission" 2 "Electric Propulsion Control" 1 "Auxiliary Power Unit (APU)" 0 "Engine" 100 "Reserved" 99 "Reserved" 98 "Reserved" 97 "Reserved" 96 "Reserved" 95 "Reserved" 94 "Reserved" 93 "Reserved" 92 "Reserved" 91 "Reserved" 90 "Reserved" 89 "Reserved" 88 "Reserved" 87 "Reserved" 86 "Reserved" 85 "Reserved" 84 "Reserved" 83 "Reserved" 82 "Reserved" 81 "Reserved" 80 "Reserved" 79 "Reserved" 78 "Reserved" 77 "Reserved" 76 "Reserved" 75 "Supplemental Fan" 74 "Lubrication System" 73 "Rollover Detection Control" 72 "Coolant Valve Controller" 71 "Transfer Case Control" 70 "Auxiliary Regeneration Device" 69 "Engine Emission Aftertreatement System" 68 "Aftertreatment system gas measurement" 67 "Electrical System Controller" 66 "I/O Controller" 65 "Gas Flow Measurement" 64 "Endurance Braking" 63 "Engine Valve Controller" 62 "On-Board Diagnostic Unit" 61 "File Server/Printer" 60 "Cab Display" 59 "Starter" 58 "Fan Drive Control" 57 "Steering Column Unit" 56 "Communications Unit, Radio" 55 "Communications Unit, Satellite" 54 "Communications Unit, Cellular" 53 "Alternator/Charging System" 52 "Chassis Controller" 51 "Forward-Looking Collision Warning System" 50 "Auxiliary Heater" 49 "Clutch/Converter Control" 48 "Ramp Control" 47 "Information System Controller" 46 "Oil Sensor Unit" 45 "Vehicle Dynamic Stability Control" 44 "Exhaust Emission Control" 43 "Transmission Display" ;
VAL_ 2566838526 VehicleSystem 0 "Non-specific System" 127 "Not Available" ;
VAL_ 2566838526 ManufacturerCode 381 "B&G" 374 "Northern Lights" 373 "Electronic Design" 371 "Delphi" 370 "Heinzmann GmbH & Co. KG" 369 "Power Torque Engineering Ltd" 368 "HANSENHOF_electronic" 367 "Fliegl Agrartechnik" 366 "Viewnyx Corp." 365 "Digi-Star, LLC" 364 "OEM Controls Inc." 363 "BEI Duncan" 362 "Alois Poettinger Maschinenfabrik GmbH" 361 "InMach" 360 "HJS Fahrzeugtechnik GmbH & Co KG" 359 "Ludwig Bergmann GmbH" 358 "Victron Energy BV" 357 "Hardi International A/S" 356 "Fischer Panda Generators, Inc" 355 "Mastervolt International B.V." 354 "Junkkari OY" 353 "Hegemon Electronics, Inc." 352 "SAME DEUTZ-FAHR" 351 "Thrane & Thrane" 350 "Noris Marine Systems GmbH & Co KG" 349 "Suonentiet" 348 "Amazonen Werke H. Dreyer" 347 "Honeywell" 346 "Control Solutions" 345 "Korean Maritime University" 344 "Parvus Corporation" 343 "Baumer Group" 342 "THOMAS MAGNETE GmbH" 341 "Boning GmbH & Co" 340 "Continental AG" 339 "Competence Center ISOBUS e.V." 338 "GRAF-SYTECO" 337 "Carraro S.p.A." 336 "APE s.r.o." 335 "Evo Electric Ltd" 334 "Takata-Petri AG" 333 "Hadley Products Corporation" 332 "HWH Corporation" 331 "Horton, Inc." 330 "Kidde Aerospace and Defense" 329 "Deif A/S" 328 "Qwerty Electronik AB" 252 "Sensor-Technik Wiedemann GmbH" 251 "German Agricultural Society" 250 "Kuhn Group" 249 "Schaltbau GmbH" 233 "Yacht Monitoring Solutions Inc." 232 "TSD Integrated Controls" 1863 "Thomas G. Faria Co." 1862 "Sanshin" 1861 "Vector CANtech" 1860 "MMP" 1859 "Kvasar AB" 1858 "Litton" 1857 "Simrad" 1856 "Trimble" 1855 "Furuno USA" 1854 "Northstar Technologies" 1853 "Japan Radio Co." 1852 "Navionics" 1851 "Raymarine" 1850 "Teleflex" 222 "Generac Power Systems, Inc." 221 "SiE" 220 "Beede Electrical Instrument Company, Inc." 219 "Cat OEM Solutions" 218 "Gits Manufacturing Company" 217 "RM Michaelides Software & Elektronik GmbH" 216 "Paneltronics Inc." 215 "Aetna Engineering/Fireboy-Xintex" 214 "MC elettronica Srl" 213 "CNH Belgium N.V." 212 "Sure Power Industries, Inc." 211 "DNA Group" 210 "Iteris, Inc." 209 "Bell Equip. Co. SA (PTY) LTD" 208 "Drew Technologies, Inc." 207 "Otto Engineering" 206 "port GmbH" 205 "SmarTire Systems Inc" 204 "The Morey Corporation" 203 "MILtronik GmbH" 202 "Curtis Instruments, Inc." 201 "Disenos y Tecnologia S.A." 200 "MGM Brakes" 199 "Actia Corp." 198 "Mystic Valley Communications" 197 "Mechron Power Systems" 196 "LEMKEN GmbH & Co. KG" 195 "General Engine Products" 194 "TriMark Corporation" 193 "Nobletec" 192 "Floscan" 191 "XATA Corporation" 190 "Hella KGaA Hueck & Co." 189 "QUALCOMM" 188 "EMP Corp." 187 "Air-Weigh" 186 "Altronic, Inc." 185 "Beede Electrical Instrument Company" 184 "EIA Electronics" 183 "KDS Controls, Inc." 182 "Vehicle Systems Engineering B.V." 181 "Coretronics, Inc." 180 "Smart Power Systems" 179 "TeeJet Technologies Denmark" 178 "Siemens VDO Automotive AG" 177 "Diagnostic System Associates" 176 "Moritz Aerospace" 175 "Veris Technologies, Inc." 174 "AB Volvo Penta" 173 "Ryeso, Inc." 172 "Yanmar Marine USA" 171 "Wachendorff Elektronik GmbH & Co. KG" 170 "Computronics Corporation Ltd." 169 "Marlin Technologies Inc." 168 "Xantrex" 167 "JLG Industries Inc." 166 "Phoenix International" 165 "CPAC Systems AB" 164 "DaimlerChrysler Off-Highway" 163 "BRP Inc." 162 "Axiomatic Technologies" 161 "Offshore Systems (UK) Limited" 160 "Nido" 159 "NTech Industries Inc." 158 "Firestone Industrial Products Company" 157 "ISSPRO Inc." 156 "ITT Industries - Cannon" 155 "Vetronix Corporation" 154 "Westerbeke Corporation" 153 "Woodward, Industrial Controls Division" 152 "elobau GmbH & Co. KG" 151 "Raven Industries Inc. - Flow Controls Division" 150 "Fleetguard" 149 "Holset" 148 "Blue Water Data, Inc." 147 "Nautibus Electronic GmbH" 146 "Maxima Technologies" 145 "MurCal Controls" 144 "Mercury Marine" 143 "W. Gmeiner GmbH & Co." 142 "TRW Automotive (Commercial Steering Systems)" 141 "Thales Navigation Ltd." 140 "Lowrance Electronics, Inc." 139 "Caterpillar Trimble Control Technologies (CTCT), LLC" 138 "Georg Fritzmeier GmbH & Co. KG" 137 "Maretron" 136 "Komatsu Ltd." 135 "Airmar Technology Corporation" 134 "Iris Technology Ltd." 133 "Bucher Schoerling GmbH" 132 "Mulag-Fahrzeugwerk" 131 "ITT Industries" 130 "Nido - Universal Machines B.V." 129 "OMNEX Control Systems, Inc." 128 "Gerhard Duecker GmbH & Co. KG" 127 "Holland USA" 126 "Driver Tech" 125 "Nevada Automotive Test Center" 124 "Hydac Electronic" 123 "Basler Electric" 122 "FG Wilson (Engineering) Limited" 121 "HED (Hydro Electronic Devices, Inc.)" 120 "RDS Technology Ltd." 119 "IntegriNautics" 118 "Intron GmbH" 117 "HUSCO International" 116 "BEELINE Technologies" 115 "NACCO Materials Handling Group, Inc." 114 "EControls, Inc." 113 "Stress-Tek, Inc." 112 "MECALAC" 111 "Maschinenfabrik Bernhard Krone GmbH" 110 "EPIQ Sensor-Nite" 109 "TeeJet Technologies Denmark" 108 "WTK-Elecktronik GmbH" 107 "Grimme Landmaschinen GmbH & Co. KG" 106 "BAE Systems Controls, Inc." 105 "Kiepe Elektrik GmbH & Co. KG" 104 "Claas Selbstfahrende Erntemaschinen GmbH" 103 "Agrocom GmbH & Co. Agrarsystem KG" 102 "AGCO GmbH & Co." 101 "Sensoria" 100 "VDO Technik AG" 99 "International Transmissions Ltd (ITL)" 98 "Mueller-Elektronik GmbH & Co." 97 "Ag Leader Technology, Inc." 96 "Mech@tronic IT GmbH" 95 "Pacific Insight Electronics Corp." 94 "CNH Global N.V." 93 "Perkins Engines Company Ltd." 92 "Ag-Chem Equipment Co., Inc." 91 "BSG Bodensee Steuergeraete GmbH" 90 "Knorr-Bremse SfN GmbH" 89 "Kverneland Group, Electronics Division" 88 "Satloc Precision GPS" 87 "J.C. Bamford Excavators Ltd (JCB)" 86 "C.E. Niehoff & Company" 85 "Kohler Co." 84 "New Holland UK Limited" 83 "Eaton VORAD Technologies" 82 "Bobcat/Ingersoll-Rand" 81 "Fire Research Corp" 80 "Twin Disc, Inc." 79 "Daimler Benz AG - Engine Division (PBM)" 78 "Frank W. Murphy Manufacturing, Inc." 77 "Deere Power Systems Group" 76 "unused" 75 "Deere & Co. Agricultural Division" 74 "Eaton Axle-Brake Division" 73 "LeTourneau, Inc." 72 "Sisu Corporation" 71 "Vansco Electronics Ltd." 70 "Flex-Coil Limited" 69 "Trimble Navigation" 68 "Scania" 67 "Funk Manufacturing Company" 66 "John Deere Construction Equipment Division" 65 "MAN Nutzfahrzeuge AG" 64 "unused" 63 "ZF Industries Inc." 62 "Wabco" 61 "Volvo Truck Corp." 60 "Volvo Trucks North America Inc." 59 "VES Inc." 58 "SPX Corporation, OTC Division" 57 "Sauer-Danfoss Co." 56 "SAIC" 55 "Ryder System Inc." 54 "Meritor Wabco" 53 "Continental Automotive Systems US, Inc." 52 "Meritor Automotive, Inc." 51 "Robert Bosch GmbH" 50 "Robert Bosch Corp" 49 "RE America Inc." 48 "Pollak Alphabet" 47 "Phillips Semiconductor" 46 "Parasoft Computing Solutions" 45 "PACCAR" 44 "Nippondenso Co. Ltd." 43 "International Truck and Engine Corp. Vehicle Electronics" 42 "International Truck and Engine Corp. Engine Electronics" 41 "Motorola Inc." 40 "Motorola AIEG Inc." 39 "Microfirm Inc." 38 "Micro Processor Systems Inc." 37 "Mack Trucks Inc." 36 "Lucas Ltd." 35 "Kenworth Truck Co." 34 "Kelsey Hayes Co." 33 "John Deere" 32 "Jacobs Vehicle Systems" 31 "J Pollak Corp." 30 "Isuzu Motors Ltd." 29 "Hino Motors Ltd." 28 "Grote Ind. Inc." 27 "GMC" 26 "General Motors Corp., Service Technology Group" 25 "Daimler Trucks North America LLC" 24 "Ford Motor Co., Vehicle Controls" 23 "Ford Motor Co., Heavy Truck" 22 "Ford Motor Co., Electronic Concepts $ Systems" 21 "Echilin Inc., Midland Brake Inc." 20 "Eaton Ltd" 19 "Eaton Corp. Trucking Info Services" 18 "Eaton Corp, Transmission Division" 17 "Eaton Corp. Res & Dev" 16 "Eaton Corp." 15 "Dickey-John Corp." 14 "Detroit Diesel Corporation" 13 "Delco Electronics" 12 "Deere & Company, Precision Farming" 11 "Dearborn Group Inc." 10 "Cummins Engine Co." 9 "Chrysler Corp." 8 "Caterpillar Inc." 7 "Case Corp." 6 "Berifors Electronics AB" 5 "AMP Inc." 4 "Ametek-Dixson" 3 "Ametek, US Gauge Division" 2 "Allison Transmission, GMC" 1 "Allied Signal Inc." 0 "Reserved" 231 "Topcon Positioning Systems, Inc." 230 "Saucon Technologies" 229 "Garmin International Inc." 228 "ZF Marine Electronics" 227 "Lykketronic A/S" 226 "Monaco Coach Corporation" 225 "SKF" 224 "EMMI Network, S.L." 223 "Vaueo Retarder Co., Ltd." 263 "IMMI" 262 "HydraForce, Inc" 261 "Red Dot Corporation" 260 "Reichhardt GmbH" 259 "Jetter AG" 258 "ARAG" 257 "Honda Motor Co., Ltd" 256 "Tyco Electronics AMP" 255 "MEAS France" 254 "GE Sensing" 253 "Mobile Control Systems" 298 "Holley Performance" 297 "Zonar Systems Inc" 296 "micro dynamics GmbH" 295 "BEP Marine" 294 "Grayhill Inc." 293 "Spyder Controls Corp." 292 "IKUSI - Angel Iglesias S.A." 291 "Groeneveld Transport Efficiency BV" 290 "Kuebler GmbH" 289 "Watlow" 288 "Mitsubishi FUSO Truck & Bus Corp." 287 "NTech Industries, Inc" 286 "Coelmo srl" 285 "Sea Recovery Corp" 284 "Mobile Tech Chile" 283 "CWF Hamilton & Co Ltd" 282 "Medallion Instrumentation Systems" 281 "Precision Governors LLC" 311 "Patrick Power Products" 310 "TECNORD srl" 309 "Krauss-Maffei Wegmann GmbH & Co. KG" 308 "Cyntrx" 307 "MAS Technologies" 306 "Sleipner Motor AB" 305 "NovAtel Inc" 304 "EmpirBus AB" 303 "CTS Corporation" 302 "Nissin Kogyo Co., LTD" 301 "Parker Hannifin (UK) Ltd FDE group" 300 "Systron Donner Automotive" 299 "Rauch Landmaschinen GmbH" 280 "Leica Geosystems Pty Ltd" 279 "Geometris LP" 278 "Takata Electronics" 277 "LHP Telematics" 276 "Aqua-Hot Heating Systems" 275 "Navico Egersund AS" 274 "LTW Technology Co., LTD" 273 "Active Research Limited" 272 "Gross Mechanical Laboratories, Inc" 327 "Sonceboz SA" 326 "Akron Brass Company" 325 "ASM Automation Sensorik Messtechnik GmbH" 324 "Snap-on Diagnostics" 323 "Mobileye Vision Technologies Ltd." 322 "MICHENKA s.r.o." 321 "Ultra Electronics, Electrics" 320 "Miedema Landbouwwerktuigenfabriek B.V." 319 "Cadec Global" 318 "SAT Plan" 317 "Navtronics Bvba" 316 "ITT Flow Control" 315 "Icom Incorporated" 314 "CSM GmbH" 313 "Ilmor Engineering, Inc" 312 "Lectronix, Inc." 271 "Cole Hersee" 270 "Tennant" 269 "Saft America Inc.,  Space & Defense Division" 268 "Accurate Technologies" 267 "Red Lion Controls, Inc" 266 "International Thermal Research Ltd" 265 "MTS Sensor Technologie GmbH" 264 "Autolync" 248 "Cooper Standard Automotive Active Systems Group" 247 "ePULSE" 246 "Class 1, Inc" 245 "Capstan Ag Systems, Inc." 244 "Techno-Matic" 243 "eRide, Inc." 242 "Kokusandenki Co. Ltd" 241 "Schneider Automation SAS " 240 "Vanair Mfg" 239 "May & Scofield Ltd" 238 "ZF Friedrichshafen AG" 237 "Agtron Enterprises Inc" 236 "Norac Systems International Inc" 235 "SailorMade Marine Telemetry - Tetra Technology Ltd." 234 "Mondial electronic GmbH" ;
VAL_ 2566838526 VehicleSystem5 127 "Not Available" 0 "Ind. Process Control Stationary" ;
VAL_ 2566838526 VehicleSystem4 100 "Deck/Cargo/Fishing equip. sys" 90 "Environmental (HVAC) Systems" 80 "Instrumentation/General Systems" 70 "Communications Systems" 60 "Navigation Systems" 50 "Propulsion Systems" 40 "Steering Systems" 30 "Power Mgmt and lighting systems" 25 "Gateway" 20 "Safety Systems" 10 "System Tools" 127 "Not Available" 0 "Non-specific System" ;
VAL_ 2566838526 VehicleSystem3 8 "Grader" 7 "Four Wheel Drive Loader" 6 "Forklift" 5 "Excavator" 4 "Crawler" 3 "Backhoe" 2 "Articulated Dump Truck" 1 "Skid Steer Loader" 127 "Not Available" 0 "Non-specific System" ;
VAL_ 2566838526 VehicleSystem2 16 "Skidder" 15 "Earth Work" 14 "Special Crops" 13 "Powered Auxiliary Device" 12 "Farm Yard Operations" 11 "Transport/Trailer" 10 "Irrigation" 9 "Forage" 8 "Root Harvesters" 7 "Harvesters" 6 "Sprayers" 5 "Fertilizers" 4 "Planters/Seeders" 3 "Secondary Tillage" 2 "Tillage" 1 "Tractor" 127 "Not Available" 0 "Non-specific System" ;
VAL_ 2566838526 VehicleSystem1 2 "Trailer" 1 "Tractor" 127 "Not Available" 0 "Non-specific System" ;
VAL_ 2565799678 IndustryGroup 6 "Reserved for SAE" 0 "Global" 1 "On-Highway" 2 "Agricultural and Forestry" 3 "Construction" 4 "Marine" 5 "IndustrialProcessCtrlStationary" 7 "Reserved for SAE" ;
VAL_ 2565799678 Function 127 "Reserved" 126 "Reserved" 125 "Reserved" 124 "Reserved" 123 "Reserved" 122 "Reserved" 121 "Reserved" 120 "Reserved" 119 "Reserved" 118 "Reserved" 117 "Reserved" 116 "Reserved" 115 "Reserved" 114 "Reserved" 113 "Reserved" 112 "Reserved" 111 "Reserved" 110 "Reserved" 109 "Reserved" 108 "Reserved" 107 "Reserved" 106 "Reserved" 105 "Reserved" 104 "Reserved" 103 "Reserved" 102 "Reserved" 101 "Reserved" 42 "Water Pump Control" 41 "Lighting - Operator Controls" 40 "Seat Control" 39 "Ignition Control Module" 38 "Tire Pressure Control" 37 "Cab Controller" 36 "Pneumatic - System Controller" 35 "Suspension - System Controller" 34 "Hydraulic Pump Controller" 33 "System Monitor" 32 "Headway Controller" 31 "Propulsion Battery Charger" 30 "Management Computer" 29 "Virtual Terminal (in cab)" 28 "Off Vehicle Gateway" 27 "Power TakeOff (Secondary or Front)" 26 "Body Controller" 25 "Network Interconnect ECU" 24 "Vehicle Security" 23 "Vehicle Navigation" 22 "Aerodynamic Control" 21 "Cab Climate Control" 20 "Trip Recorder" 19 "Instrument Cluster" 18 "Suspension - Drive Axle" 17 "Suspension - Steer Axle" 16 "Steering Controller" 15 "Fuel System" 14 "Cruise Control" 13 "Retarder - Driveline" 12 "Retarder - Engine" 11 "Brakes - Drive Axle" 10 "Brakes - Steer Axle" 9 "Brakes - System Controller" 8 "Axle - Drive" 7 "Axle - Steering" 6 "Power TakeOff - (Main or Rear)" 5 "Shift Control/Console" 4 "Battery Pack Monitor" 3 "Transmission" 2 "Electric Propulsion Control" 1 "Auxiliary Power Unit (APU)" 0 "Engine" 100 "Reserved" 99 "Reserved" 98 "Reserved" 97 "Reserved" 96 "Reserved" 95 "Reserved" 94 "Reserved" 93 "Reserved" 92 "Reserved" 91 "Reserved" 90 "Reserved" 89 "Reserved" 88 "Reserved" 87 "Reserved" 86 "Reserved" 85 "Reserved" 84 "Reserved" 83 "Reserved" 82 "Reserved" 81 "Reserved" 80 "Reserved" 79 "Reserved" 78 "Fire Suppression System" 77 "Fuel Properties Sensor" 76 "Temperature Sensor" 75 "Supplemental Fan" 74 "Lubrication System" 73 "Rollover Detection Control" 72 "Coolant Valve Controller" 71 "Transfer Case Control" 70 "Auxiliary Regeneration Device" 69 "Engine Emission Aftertreatement System" 68 "Aftertreatment system gas measurement" 67 "Electrical System Controller" 66 "I/O Controller" 65 "Gas Flow Measurement" 64 "Endurance Braking" 63 "Engine Valve Controller" 62 "On-Board Diagnostic Unit" 61 "File Server/Printer" 60 "Cab Display" 59 "Starter" 58 "Fan Drive Control" 57 "Steering Column Unit" 56 "Communications Unit, Radio" 55 "Communications Unit, Satellite" 54 "Communications Unit, Cellular" 53 "Alternator/Charging System" 52 "Chassis Controller" 51 "Forward-Looking Collision Warning System" 50 "Auxiliary Heater" 49 "Clutch/Converter Control" 48 "Ramp Control" 47 "Information System Controller" 46 "Oil Sensor Unit" 45 "Vehicle Dynamic Stability Control" 44 "Exhaust Emission Control" 43 "Transmission Display" ;
VAL_ 2565799678 ManufacturerCode 520 "Trapeze" 519 "Peeters Landbouwmachines b.v." 518 "Transas USA Inc." 517 "Noland Engineering" 516 "AVAT Automation GmbH" 515 "GINAF Trucks Nederland B.V." 514 "DISTek Integration, Inc." 513 "FarmscanAg" 512 "Inpower LLC" 511 "Sulky" 510 "Marinesoft Co. Ltd" 509 "MOTORTECH GmbH" 508 "Transtech Innovations" 507 "Test Center ISOBUS" 506 "IHI STAR Machinery Corporation" 505 "Yetter Farm Equipment" 504 "Vesper Marine" 503 "Naviop S.R.L." 502 "Attwood Corporation" 501 "Agrotronix S.A." 500 "Oxbo International Corporation" 499 "LCJ Capteurs" 498 "Innovative Design Solutions, Inc." 497 "SENTRON Sistemas Embarcados" 496 "W. Gessmann GmbH" 495 "HOLMER Maschinenbau GmbH" 494 "Synerject" 493 "Watcheye" 492 "Inergy Automotive Systems" 491 "Penny and Giles Ltd" 490 "QuikQ" 489 "Appareo Systems" 488 "The Charles Machine Works, Inc." 487 "DSE Test Solutions A/S" 486 "Westport Innovations Inc." 485 "MATT automotive" 484 "Headsight Inc." 483 "Valeo" 482 "Tricon Electronics" 481 "Chetco Digital Instruments" 480 "EnerDel, Inc." 454 "NGK Spark Plug Co. Ltd" 453 "Cooper Bussmann" 452 "WIKA Alexander Wiegand SE & Co. KG" 451 "Parker Hannifin Corp" 450 "Dycor Technologies Ltd." 449 "Polaris Industries Inc" 448 "Stanadyne Corporation, Electronics Systems" 447 "Great Plains Mfg." 446 "CertTech, L.L.C." 445 "KAT MECHATRONIC, Electronic Product Division" 444 "ITT Power Solutions" 443 "SignalQuest, Inc." 442 "Horsch Maschinen GmbH" 441 "PTG Reifendruckregelsysteme GmbH" 440 "Cummins Power Generation" 439 "Hyundai Heavy Industries" 438 "Comar Systems Ltd" 437 "Digital Yacht Limited" 436 "Kinze Manufacturing" 435 "Zunhammer GmbH" 434 "Stored Energy Systems" 433 "Rowe Electronics" 432 "S&A Systems, Inc." 431 "Tohatsu Corporation" 430 "Auteq Telematica S.A." 479 "Vapor Bus International" 478 "OceanSat BV" 477 "OilQuick AB" 476 "Hummingbird Marine Electronics" 475 "GME" 474 "Persen Technologies Inc." 473 "Boss Industries, Inc." 472 "Tenneco Inc." 471 "Sea Cross Marine AB" 470 "SI-TEX Marine Electronics" 469 "RA Consulting GmbH" 468 "Tyco Fire Protection Products" 467 "Lely Industries N.V." 466 "Veethree Electronics and Marine LLC" 465 "Ashcroft Inc" 464 "Leach International Corporation" 463 "PROBOTIQ" 462 "IHI Shibaura Machinery Corporation" 461 "HAWE Hydraulik SE" 460 "San Giorgio S.E.I.N." 459 "Alltek Marine Electronics Corp" 458 "Control Solutions, Inc." 457 "RUSELPROM-ElectricDrive Ltd" 456 "General Kinetics" 455 "ADZ NAGANO GmbH" 429 "Rota Engineering Ltd." 428 "Mfg_428" 427 "em-trak Marine Electronics Ltd" 426 "Egersund Marine Electronics AS" 425 "Methode Electronics Inc, MDI" 424 "Odyne LLC" 423 "BSM Wireless, Inc." 422 "True Heading AB" 421 "Vertex Standard Co., Ltd" 420 "Vermeer Corporation, ACS Group" 419 "Fusion Electronics Ltd" 418 "Intellistick Inc" 417 "KZValve" 416 "Kubota Corporation" 415 "Valid Manufacturing Ltd." 414 "Cattron Group International" 413 "Datapross Nijbroek bv" 412 "WebTech Wireless Inc." 411 "Hy-Drive Technologies Ltd." 410 "COBO S.p.A. Divisione 3B6" 409 "Transfluid S.r.L." 408 "Corvus Energy Ltd." 407 "Comtech Mobile Datacom" 406 "Vecima Networks Inc." 405 "Wema System AS" 404 "Com Nav Marine Ltd" 403 "Trackwell ADS, Inc." 402 "Simma Software, Inc." 401 "Torqeedo GmbH" 400 "Livorsi Marine" 399 "ISEKI & Co., Ltd." 398 "Hilite International" 397 "Sanyo-kiki Co Ltd." 396 "Beyond Measure" 395 "GENTEC S.R.L." 394 "Capi 2 Nederland BV" 393 "Harvest Tec, Inc" 392 "Tianyuan Technology Co Ltd." 391 "Electronic Design for Industry, Inc" 390 "Partech Inc." 389 "Benchmark Electronics, Minnesota Division" 388 "Innomatix, LLC" 387 "Orscheln Products, LLC" 386 "JLG Automation BVBA" 385 "Johnson Outdoor Marine Electronics" 384 "Camano Light" 383 "MCL Industries" 382 "National Agricultural and Food Research Organization" 380 "Suntech International Ltd." 379 "Yamabiko Corporation" 378 "Glendinning Marine Products" 377 "ifm electronic gmbh" 376 "Quake Global" 375 "Williams Controls Inc." 372 "Delphi" 381 "B&G" 374 "Northern Lights, Inc." 373 "Electronic Design Inc." 371 "Heinzmann GmbH & Co. KG" 370 "Rolls-Royce Marine AS" 369 "Power Torque Engineering Ltd" 368 "HANSENHOF_electronic" 367 "Fliegl Agrartechnik" 366 "Viewnyx Corp." 365 "Digi-Star, LLC" 364 "OEM Controls Inc." 363 "BEI Duncan" 362 "Alois Poettinger Maschinenfabrik GmbH" 361 "InMach" 360 "HJS Emission Technology GmbH & Co KG" 359 "Ludwig Bergmann GmbH" 358 "Victron Energy BV" 357 "Hardi International A/S" 356 "Fischer Panda Generators, Inc" 355 "Mastervolt International B.V." 354 "Junkkari OY" 353 "Hegemon Electronics, Inc." 352 "SAME DEUTZ-FAHR" 351 "Thrane & Thrane" 350 "Noris Marine Systems GmbH & Co KG" 349 "Suonentiet" 348 "Amazonen Werke H. Dreyer" 347 "Honeywell" 346 "Control Solutions" 345 "Korean Maritime University" 344 "Parvus Corporation" 343 "Baumer Group" 342 "THOMAS MAGNETE GmbH" 341 "Boning GmbH & Co" 340 "Continental AG" 339 "Competence Center ISOBUS e.V." 338 "GRAF-SYTECO" 337 "Carraro S.p.A." 336 "APE s.r.o." 335 "Evo Electric Ltd" 334 "Takata-Petri AG" 333 "Hadley Products Corporation" 332 "HWH Corporation" 331 "Horton, Inc." 330 "Kidde Aerospace and Defense" 329 "Deif A/S" 328 "Qwerty Electronik AB" 252 "Sensor-Technik Wiedemann GmbH" 251 "German Agricultural Society" 250 "Kuhn Group" 249 "Schaltbau GmbH" 233 "Yacht Monitoring Solutions Inc." 232 "TSD Integrated Controls" 1863 "Thomas G. Faria Co." 1862 "Sanshin" 1861 "Vector CANtech" 1860 "MMP" 1859 "Kvasar AB" 1858 "Litton" 1857 "Simrad" 1856 "Trimble" 1855 "Furuno USA" 1854 "Northstar Technologies" 1853 "Japan Radio Co." 1852 "Navionics" 1851 "Raymarine" 1850 "Teleflex" 222 "Generac Power Systems, Inc." 221 "SiE" 220 "Beede Electrical Instrument Company, Inc." 219 "Cat OEM Solutions" 218 "Gits Manufacturing Company" 217 "RM Michaelides Software & Elektronik GmbH" 216 "Paneltronics Inc." 215 "Aetna Engineering/Fireboy-Xintex" 214 "MC elettronica Srl" 213 "CNH Belgium N.V." 212 "Sure Power Industries, Inc." 211 "DNA Group" 210 "Iteris, Inc." 209 "Bell Equip. Co. SA (PTY) LTD" 208 "Drew Technologies, Inc." 207 "Otto Engineering" 206 "port GmbH" 205 "SmarTire Systems Inc" 204 "The Morey Corporation" 203 "MILtronik GmbH" 202 "Curtis Instruments, Inc." 201 "Disenos y Tecnologia S.A." 200 "MGM Brakes" 199 "Actia Corp." 198 "Mystic Valley Communications" 197 "Mechron Power Systems" 196 "LEMKEN GmbH & Co. KG" 195 "General Engine Products" 194 "TriMark Corporation" 193 "Nobletec" 192 "Floscan" 191 "XRS Corporation" 190 "Hella KGaA Hueck & Co." 189 "QUALCOMM" 188 "EMP Corp." 187 "Air-Weigh" 186 "Altronic, Inc." 185 "Beede Electrical Instrument Company" 184 "EIA Electronics" 183 "KDS Controls, Inc." 182 "Vehicle Systems Engineering B.V." 181 "Coretronics, Inc." 180 "Smart Power Systems" 179 "TeeJet Technologies Denmark" 178 "Siemens VDO Automotive AG" 177 "Diagnostic System Associates" 176 "Moritz Aerospace" 175 "Veris Technologies, Inc." 174 "AB Volvo Penta" 173 "Ryeso, Inc." 172 "Yanmar Marine USA" 171 "Wachendorff Elektronik GmbH & Co. KG" 170 "Computronics Corporation Ltd." 169 "Marlin Technologies Inc." 168 "Xantrex" 167 "JLG Industries Inc." 166 "Phoenix International" 165 "CPAC Systems AB" 164 "DaimlerChrysler Off-Highway" 163 "BRP Inc." 162 "Axiomatic Technologies" 161 "Offshore Systems (UK) Limited" 160 "Nido" 159 "NTech Industries Inc." 158 "Firestone Industrial Products Company" 157 "ISSPRO Inc." 156 "ITT Industries - Cannon" 155 "Vetronix Corporation" 154 "Westerbeke Corporation" 153 "Woodward, Industrial Controls Division" 152 "elobau GmbH & Co. KG" 151 "Raven Industries Inc. - Flow Controls Division" 150 "Fleetguard" 149 "Holset" 148 "Blue Water Data, Inc." 147 "Nautibus Electronic GmbH" 146 "Maxima Technologies" 145 "MurCal Controls" 144 "Mercury Marine" 143 "W. Gmeiner GmbH & Co." 142 "TRW Automotive (Commercial Steering Systems)" 141 "Thales Navigation Ltd." 140 "Lowrance Electronics, Inc." 139 "Caterpillar Trimble Control Technologies (CTCT), LLC" 138 "Georg Fritzmeier GmbH & Co. KG" 137 "Maretron" 136 "Komatsu Ltd." 135 "Airmar Technology Corporation" 134 "Iris Technology Ltd." 133 "Bucher Schoerling GmbH" 132 "Mulag-Fahrzeugwerk" 131 "ITT Industries" 130 "Nido - Universal Machines B.V." 129 "OMNEX Control Systems, Inc." 128 "Gerhard Duecker GmbH & Co. KG" 127 "Holland USA" 126 "Driver Tech" 125 "Nevada Automotive Test Center" 124 "Hydac Electronic" 123 "Basler Electric" 122 "FG Wilson (Engineering) Limited" 121 "HED (Hydro Electronic Devices, Inc.)" 120 "RDS Technology Ltd." 119 "IntegriNautics" 118 "Intron GmbH" 117 "HUSCO International" 116 "BEELINE Technologies" 115 "NACCO Materials Handling Group, Inc." 114 "EControls, Inc." 113 "Stress-Tek, Inc." 112 "MECALAC" 111 "Maschinenfabrik Bernard Krone GmbH" 110 "EPIQ Sensor-Nite" 109 "TeeJet Technologies Denmark" 108 "WTK-Elecktronik GmbH" 107 "Grimme Landmaschinen GmbH & Co. KG" 106 "BAE Systems Controls, Inc." 105 "Kiepe Elektrik GmbH & Co. KG" 104 "Claas Selbstfahrende Erntemaschinen GmbH" 103 "CLAAS Agrosystems GmbH & Co. KG" 102 "AGCO GmbH & Co." 101 "Sensoria" 100 "VDO Technik AG" 99 "International Transmissions Ltd (ITL)" 98 "Mueller-Elektronik GmbH & Co." 97 "Ag Leader Technology, Inc." 96 "Mech@tronic IT GmbH" 95 "Pacific Insight Electronics Corp." 94 "CNH Global N.V." 93 "Perkins Engines Company Ltd." 92 "Ag-Chem Equipment Co., Inc." 91 "BSG Bodensee Steuergeraete GmbH" 90 "Knorr-Bremse SfN GmbH" 89 "Kverneland Group, Electronics Division" 88 "Satloc Precision GPS" 87 "J.C. Bamford Excavators Ltd (JCB)" 86 "C.E. Niehoff & Company" 85 "Kohler Co." 84 "New Holland UK Limited" 83 "Bendix VORAD Technologies" 82 "Bobcat/Ingersoll-Rand" 81 "Fire Research Corp" 80 "Twin Disc, Inc." 79 "Daimler Benz AG - Engine Division (PBM)" 78 "Frank W. Murphy Manufacturing, Inc." 77 "Deere Power Systems Group" 76 "unused" 75 "Deere & Co. Agricultural Division" 74 "Eaton Axle-Brake Division" 73 "LeTourneau, Inc." 72 "Sisu Corporation" 71 "Vansco Electronics Ltd." 70 "Flex-Coil Limited" 69 "Trimble Navigation" 68 "Scania" 67 "Funk Manufacturing Company" 66 "John Deere Construction Equipment Division" 65 "MAN Nutzfahrzeuge AG" 64 "unused" 63 "ZF Industries Inc." 62 "Wabco" 61 "Volvo Truck Corp." 60 "Volvo Trucks North America Inc." 59 "VES Inc." 58 "SPX Corporation, OTC Division" 57 "Sauer-Danfoss Co." 56 "SAIC" 55 "Ryder System Inc." 54 "Meritor Wabco" 53 "Continental Automotive Systems US, Inc." 52 "Meritor Automotive, Inc." 51 "Robert Bosch GmbH" 50 "Robert Bosch Corp" 49 "RE America Inc." 48 "Pollak Alphabet" 47 "Phillips Semiconductor" 46 "Noregon Systems, Inc" 45 "PACCAR" 44 "Nippondenso Co. Ltd." 43 "International Truck and Engine Corp. Vehicle Electronics" 42 "International Truck and Engine Corp. Engine Electronics" 41 "Motorola Inc." 40 "Motorola AIEG Inc." 39 "Microfirm Inc." 38 "Micro Processor Systems Inc." 37 "Mack Trucks Inc." 36 "Lucas Ltd." 35 "Kenworth Truck Co." 34 "Kelsey Hayes Co." 33 "John Deere" 32 "Jacobs Vehicle Systems" 31 "J Pollak Corp." 30 "Isuzu Motors Ltd." 29 "Hino Motors Ltd." 28 "Grote Ind. Inc." 27 "GMC" 26 "General Motors Corp., Service Technology Group" 25 "Daimler Trucks North America LLC" 24 "Ford Motor Co., Vehicle Controls" 23 "Ford Motor Co., Heavy Truck" 22 "Ford Motor Co., Electronic Concepts $ Systems" 21 "Echilin Inc., Midland Brake Inc." 20 "Eaton Ltd" 19 "Eaton Corp. Trucking Info Services" 18 "Eaton Corp, Transmission Division" 17 "Eaton Corp. Res & Dev" 16 "Eaton Corp." 15 "Dickey-John Corp." 14 "Detroit Diesel Corporation" 13 "Delco Electronics" 12 "Deere & Company, Precision Farming" 11 "Dearborn Group Inc." 10 "Cummins Engine Co." 9 "Chrysler Corp." 8 "Caterpillar Inc." 7 "Case Corp." 6 "Berifors Electronics AB" 5 "AMP Inc." 4 "Ametek-Dixson" 3 "Ametek, US Gauge Division" 2 "Allison Transmission, GMC" 1 "Allied Signal Inc." 0 "Reserved" 231 "Topcon Positioning Systems, Inc." 230 "Saucon Technologies" 229 "Garmin International Inc." 228 "ZF Marine Electronics" 227 "Lykketronic A/S" 226 "Monaco Coach Corporation" 225 "SKF" 224 "EMMI Network, S.L." 223 "Vaueo Retarder Co., Ltd." 263 "IMMI" 262 "HydraForce, Inc" 261 "Red Dot Corporation" 260 "Reichhardt GmbH" 259 "Jetter AG" 258 "ARAG" 257 "Honda Motor Co., Ltd" 256 "Tyco Electronics AMP" 255 "MEAS France" 254 "GE Sensing" 253 "Mobile Control Systems" 298 "Holley Performance" 297 "Zonar Systems Inc" 296 "micro dynamics GmbH" 295 "BEP Marine" 294 "Grayhill Inc." 293 "Spyder Controls Corp." 292 "IKUSI - Angel Iglesias S.A." 291 "Groeneveld Transport Efficiency BV" 290 "Kuebler GmbH" 289 "Watlow" 288 "Mitsubishi FUSO Truck & Bus Corp." 287 "NTech Industries, Inc" 286 "Coelmo srl" 285 "Sea Recovery Corp" 284 "Mobile Tech Chile" 283 "CWF Hamilton & Co Ltd" 282 "Medallion Instrumentation Systems" 281 "Precision Governors LLC" 311 "Patrick Power Products" 310 "TECNORD srl" 309 "Krauss-Maffei Wegmann GmbH & Co. KG" 308 "Cyntrx" 307 "MBW Technologies" 306 "Sleipner Motor AB" 305 "NovAtel Inc" 304 "EmpirBus AB" 303 "CTS Corporation" 302 "Nissin Kogyo Co., LTD" 301 "Parker Hannifin (UK) Ltd FDE group" 300 "Systron Donner Automotive" 299 "Rauch Landmaschinen GmbH" 280 "Leica Geosystems Pty Ltd" 279 "Geometris LP" 278 "Takata Electronics" 277 "LHP Telematics" 276 "Aqua-Hot Heating Systems" 275 "Navico Egersund AS" 274 "LTW Technology Co., LTD" 273 "Active Research Limited" 272 "Gross Mechanical Laboratories, Inc" 327 "Sonceboz SA" 326 "Akron Brass Company" 325 "ASM Automation Sensorik Messtechnik GmbH" 324 "Snap-on Diagnostics" 323 "Mobileye Vision Technologies Ltd." 322 "MICHENKA s.r.o." 321 "Ultra Electronics, Electrics" 320 "Miedema Landbouwwerktuigenfabriek B.V." 319 "Cadec Global" 318 "SAT Plan" 317 "Navtronics Bvba" 316 "ITT Flow Control" 315 "Icom Incorporated" 314 "CSM GmbH" 313 "Ilmor Engineering, Inc" 312 "Lectronix, Inc." 271 "Cole Hersee" 270 "Tennant" 269 "Saft America Inc.,  Space & Defense Division" 268 "Accurate Technologies" 267 "Red Lion Controls, Inc" 266 "International Thermal Research Ltd" 265 "MTS Sensor Technologie GmbH" 264 "Autolync" 248 "Cooper Standard Automotive Active Systems Group" 247 "ePULSE" 246 "Class 1, Inc" 245 "Capstan Ag Systems, Inc." 244 "Techno-Matic" 243 "eRide, Inc." 242 "Kokusandenki Co. Ltd" 241 "Schneider Automation SAS " 240 "Vanair Mfg" 239 "May & Scofield Ltd" 238 "ZF Friedrichshafen AG" 237 "Agtron Enterprises Inc" 236 "Norac Systems International Inc" 235 "SailorMade Marine Telemetry - Tetra Technology Ltd." 234 "Mondial electronic GmbH" ;
VAL_ 2565799678 VehicleSystem 0 "Non-specific System" 127 "Not Available" ;
VAL_ 2565799678 VehicleSystem5 127 "Not Available" 0 "Ind. Process Control Stationary" ;
VAL_ 2565799678 VehicleSystem4 100 "Deck/Cargo/Fishing equip. sys" 90 "Environmental (HVAC) Systems" 80 "Instrumentation/General Systems" 70 "Communications Systems" 60 "Navigation Systems" 50 "Propulsion Systems" 40 "Steering Systems" 30 "Power Mgmt and lighting systems" 25 "Gateway" 20 "Safety Systems" 10 "System Tools" 127 "Not Available" 0 "Non-specific System" ;
VAL_ 2565799678 VehicleSystem3 8 "Grader" 7 "Four Wheel Drive Loader" 6 "Forklift" 5 "Excavator" 4 "Crawler" 3 "Backhoe" 2 "Articulated Dump Truck" 1 "Skid Steer Loader" 127 "Not Available" 0 "Non-specific System" ;
VAL_ 2565799678 VehicleSystem2 25 "Slurry Applicators" 24 "Utility Vehicles" 23 "Mulchers" 22 "Timber Processing Machines" 21 "Timber loaders" 20 "Forwarders" 19 "Timber Harvesters" 17 "Sensor Systems" 16 "Skidder" 15 "Earth Work" 14 "Special Crops" 13 "Powered Auxiliary Device" 12 "Farm Yard Operations" 11 "Transport/Trailer" 10 "Irrigation" 9 "Forage" 8 "Root Harvesters" 7 "Harvesters" 6 "Sprayers" 5 "Fertilizers" 4 "Planters/Seeders" 3 "Secondary Tillage" 2 "Tillage" 1 "Tractor" 127 "Not Available" 0 "Non-specific System" ;
VAL_ 2565799678 VehicleSystem1 2 "Trailer" 1 "Tractor" 127 "Not Available" 0 "Non-specific System" ;
VAL_ 2632711934 SequenceNumber 255 "NoSequenceAvailable" ;
VAL_ 2632777470 ConnectionAbortReason 7 "AnyOtherError" 6 "DuplicateSequenceNumber" 5 "BadSequenceNumber" 4 "UnexpectedDataTransferPacket" 3 "Timeout_CloseSession" 2 "NoFreeSystemResources" 1 "AlreadyInConnManagedSession" ;
VAL_ 2632777470 PGNumber 255 "NotAvailable" ;
VAL_ 2632777470 ControlByte 24 "EAbort" 23 "EEoMACK" 22 "EDPO" 21 "ECTS" 20 "ERTS" 255 "Abort" 32 "BAM" 19 "EoMA" 17 "CTS" 16 "RTS" ;
VAL_ 2563374846 UseTransferMode 3 "NA" 2 "Undefined" 1 "Yes" 0 "No" ;
VAL_ 2499635966 AxleGroupLocation 3 "Trailer F axle group" 2 "Trailer E axle group" ;
VAL_ 2633853438 AxleGroupLocation 3 "Trailer F axle group" 2 "Trailer E axle group" ;
VAL_ 2432520702 AftercoolerCoolantThermostatMode 3 "dont care/reserved" 2 "reserved" 1 "position control mode used for service only" 0 "temperature control mode" ;
VAL_ 2566745086 AddtnlTrlrAxlGrupWeightAvailable 3 "Not available / not applicable" 2 "Reserved" 1 "Additional trailer axle group present" 0 "Additional trailer axle group not present" ;
VAL_ 2566745086 TrailerHAxleGroupWeightAvailable 3 "Not available / not applicable" 2 "Reserved" 1 "Trailer H axle group present" 0 "Trailer H axle group not present" ;
VAL_ 2566745086 TrailerGAxleGroupWeightAvailable 3 "Not available / not applicable" 2 "Reserved" 1 "Trailer G axle group present" 0 "Trailer G axle group not present" ;
VAL_ 2566745086 TrailerFAxleGroupWeightAvailable 3 "Not available / not applicable" 2 "Reserved" 1 "Trailer F axle group present" 0 "Trailer F axle group not present" ;
VAL_ 2566745086 TrailerEAxleGroupWeightAvailable 3 "Not available / not applicable" 2 "Reserved" 1 "Trailer E axle group present" 0 "Trailer E axle group not present" ;
VAL_ 2566745086 TrailerDAxleGroupWeightAvailable 3 "Not available / not applicable" 2 "Reserved" 1 "Trailer D axle group present" 0 "Trailer D axle group not present" ;
VAL_ 2566745086 TrailerCAxleGroupWeightAvailable 3 "Not available / not applicable" 2 "Reserved" 1 "Trailer C axle group present" 0 "Trailer C axle group not present" ;
VAL_ 2566745086 TrailerBAxleGroupWeightAvailable 3 "Not available / not applicable" 2 "Reserved" 1 "Trailer B axle group present" 0 "Trailer B axle group not present" ;
VAL_ 2566745086 TrailerAAxleGroupWeightAvailable 3 "Not available / not applicable" 2 "Reserved" 1 "Trailer A axle group present" 0 "Trailer A axle group not present" ;
VAL_ 2566745086 AddtnlTrctrAxlGrpWeightAvailable 3 "Not available / not applicable" 2 "Reserved" 1 "Additional tractor axle group present" 0 "Additional tractor axle group not present" ;
VAL_ 2566745086 TagAxleGroupWeightAvailable 3 "Not available / not applicable" 2 "Reserved" 1 "Tag axle group present" 0 "Tag axle group not present" ;
VAL_ 2566745086 DriveAxleGroupWeightAvailable 3 "Not available / not applicable" 2 "Reserved" 1 "Drive axle group present" 0 "Drive axle group not present" ;
VAL_ 2566745086 LiftAxleGroupWeightAvailable 3 "Not available / not applicable" 2 "Reserved" 1 "Lift axle group present" 0 "Lift axle group not present" ;
VAL_ 2566745086 SteerAxleGroupWeightAvailable 3 "Not available / not applicable" 2 "Reserved" 1 "Steer axle group present" 0 "Steer axle group not present" ;
VAL_ 2566739198 FlashRedStopLamp 3 "Unavailable / Do Not Flash" 2 "Reserved" 1 "Fast Flash" 0 "Slow Flash" ;
VAL_ 2566739198 FlashProtectLamp 3 "Unavailable / Do Not Flash" 2 "Reserved" 1 "Fast Flash" 0 "Slow Flash" ;
VAL_ 2566739198 FlashMalfuncIndicatorLamp 3 "Unavailable / Do Not Flash" 2 "Reserved" 1 "Fast Flash" 0 "Slow Flash" ;
VAL_ 2566739198 FlashAmberWarningLamp 3 "Unavailable / Do Not Flash" 2 "Reserved" 1 "Fast Flash" 0 "Slow Flash" ;
VAL_ 2566739198 MalfunctionIndicatorLampStatus 3 "Not available" 2 "Reserved" 1 "Lamp on" 0 "Lamp off" ;
VAL_ 2566739198 AmberWarningLampStatus 3 "Not available" 2 "Reserved" 1 "Lamp on" 0 "Lamp off" ;
VAL_ 2566739198 RedStopLampState 3 "Not available" 2 "Reserved" 1 "Lamp on" 0 "Lamp off" ;
VAL_ 2566739198 ProtectLampStatus 3 "Not available" 2 "Reserved" 1 "Lamp on" 0 "Lamp off" ;
